VERSION "DNNBNNNYNNNNNNNNNNNNNNNNNNNNNNNNNNNNNNNNNN/4/%%%/4/'%**4NNN///"

NS_ :

BS_:

BU_: Vector__XXX xSolarWave xSolarSurveyor xSolarStorm xNova xMiata_SCP xMiata_AGS UI INV_CHG INV GATEWAY EMS DIAG CHG BMS BATTMON AGS

BO_ 2147612871 WarnLogSts2: 223 AGS
 SG_ WarnType : 8|3@1+ (1,0) [0|0] "" DIAG,UI
 SG_ WarnTime : 24|32@1+ (1,0) [0|4.29497E+09] "seconds" DIAG,UI
 SG_ WarnId : 11|13@1+ (1,0) [0|0] "" DIAG,UI
 SG_ StringId : 56|16@1+ (1,0) [0|65532] "" DIAG,UI
 SG_ RsvBits : 0|2@1+ (1,0) [0|0] "" DIAG,UI
 SG_ MsgCount : 2|6@1+ (1,0) [0|0] "" DIAG,UI

BO_ 2147612684 WarnLogSts: 223 AGS
 SG_ WarnType : 8|3@1+ (1,0) [0|0] "" DIAG,UI
 SG_ WarnTime : 24|32@1+ (1,0) [0|4.29497E+09] "seconds" DIAG,UI
 SG_ WarnId : 11|13@1+ (1,0) [0|0] "" DIAG,UI
 SG_ RsvBits : 0|2@1+ (1,0) [0|0] "" DIAG,UI
 SG_ MsgCount : 2|6@1+ (1,0) [0|0] "" DIAG,UI

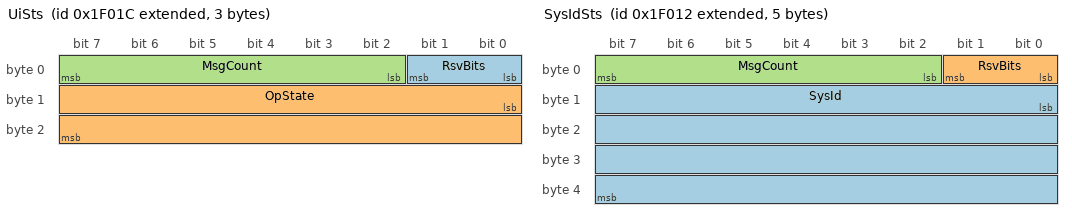
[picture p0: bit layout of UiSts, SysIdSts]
BO_ 2147610652 UiSts: 3 UI
 SG_ RsvBits : 0|2@1+ (1,0) [0|0] "" AGS,BATTMON,CHG,DIAG,INV,INV_CHG,UI
 SG_ OpState : 8|16@1+ (1,0) [0|65532] "" AGS,BATTMON,CHG,DIAG,INV,INV_CHG,UI
 SG_ MsgCount : 2|6@1+ (1,0) [0|0] "" AGS,BATTMON,CHG,DIAG,INV,INV_CHG,UI

BO_ 2147567104 UiCfgWarnTxt: 1785 DIAG
 SG_ WarnType : 16|3@1+ (1,0) [0|0] "" DIAG,UI
 SG_ WarnTxt : 32|256@1+ (1,0) [0|1785] "characters" DIAG,UI
 SG_ WarnId : 19|13@1+ (1,0) [0|0] "" DIAG,UI
 SG_ MsgCount : 2|6@1+ (1,0) [0|0] "" DIAG,UI
 SG_ ConcurAccCtr : 8|8@1+ (1,0) [0|252] "" DIAG,UI
 SG_ CfgType : 0|2@1+ (1,0) [0|0] "" DIAG,UI

BO_ 2147570944 UiCfgWarnBehaviour: 223 DIAG
 SG_ WarnId : 19|13@1+ (1,0) [0|0] "" DIAG,UI
 SG_ WarnBehaviour : 16|3@1+ (1,0) [0|0] "" DIAG,UI
 SG_ MsgCount : 2|6@1+ (1,0) [0|0] "" DIAG,UI
 SG_ ConcurAccCtr : 8|8@1+ (1,0) [0|252] "" DIAG,UI
 SG_ CfgType : 0|2@1+ (1,0) [0|0] "" DIAG,UI

BO_ 2147566080 UiCfgSplashImg: 1785 DIAG
 SG_ Rows : 24|8@1+ (1,0) [0|252] "" DIAG,UI
 SG_ MsgCount : 2|6@1+ (1,0) [0|0] "" DIAG,UI
 SG_ ImgDepth : 16|8@1+ (1,0) [0|252] "" DIAG,UI
 SG_ Image : 40|8@1+ (1,0) [0|1785] "8-Bit Bytes" DIAG,UI
 SG_ ConcurAccCtr : 8|8@1+ (1,0) [0|252] "" DIAG,UI
 SG_ Cols : 32|8@1+ (1,0) [0|252] "" DIAG,UI
 SG_ CfgType : 0|2@1+ (1,0) [0|0] "" DIAG,UI

BO_ 2147566336 UiCfgNodeLbl: 1785 DIAG
 SG_ SystemInstance : 40|4@1+ (1,0) [0|0] "" DIAG,UI
 SG_ RsvBit4 : 44|4@1+ (1,0) [0|0] "" DIAG,UI
 SG_ RsvBit1 : 32|1@1+ (1,0) [0|0] "" DIAG,UI
 SG_ NodeLbl : 48|128@1+ (1,0) [0|1785] "characters" DIAG,UI
 SG_ MsgCount : 2|6@1+ (1,0) [0|0] "" DIAG,UI
 SG_ DeviceInstanceUpper : 19|5@1+ (1,0) [0|0] "" DIAG,UI
 SG_ DeviceInstanceLower : 16|3@1+ (1,0) [0|0] "" DIAG,UI
 SG_ DeviceFunction : 24|8@1+ (1,0) [0|252] "" DIAG,UI
 SG_ DeviceClass : 33|7@1+ (1,0) [0|0] "" DIAG,UI
 SG_ ConcurAccCtr : 8|8@1+ (1,0) [0|252] "" DIAG,UI
 SG_ CfgType : 0|2@1+ (1,0) [0|0] "" DIAG,UI

BO_ 2147566848 UiCfgFaultTxt: 1785 DIAG
 SG_ MsgCount : 2|6@1+ (1,0) [0|0] "" DIAG,UI
 SG_ FaultType : 16|3@1+ (1,0) [0|0] "" DIAG,UI
 SG_ FaultTxt : 32|256@1+ (1,0) [0|1785] "characters" DIAG,UI
 SG_ FaultId : 19|13@1+ (1,0) [0|0] "" DIAG,UI
 SG_ ConcurAccCtr : 8|8@1+ (1,0) [0|252] "" DIAG,UI
 SG_ CfgType : 0|2@1+ (1,0) [0|0] "" DIAG,UI

BO_ 2147570688 UiCfgFaultBehaviour: 223 DIAG
 SG_ MsgCount : 2|6@1+ (1,0) [0|0] "" DIAG,UI
 SG_ FaultId : 19|13@1+ (1,0) [0|0] "" DIAG,UI
 SG_ FaultBehaviour : 16|3@1+ (1,0) [0|0] "" DIAG,UI
 SG_ ConcurAccCtr : 8|8@1+ (1,0) [0|252] "" DIAG,UI
 SG_ CfgType : 0|2@1+ (1,0) [0|0] "" DIAG,UI

BO_ 2147566592 UiCfgAssocLbl: 1785 DIAG
 SG_ RsvBits : 19|5@1+ (1,0) [0|0] "" DIAG,UI
 SG_ MsgCount : 2|6@1+ (1,0) [0|0] "" DIAG,UI
 SG_ ConcurAccCtr : 8|8@1+ (1,0) [0|252] "" DIAG,UI
 SG_ CfgType : 0|2@1+ (1,0) [0|0] "" DIAG,UI
 SG_ AssocType : 16|3@1+ (1,0) [0|0] "" DIAG,UI
 SG_ AssocLbl : 32|128@1+ (1,0) [0|1785] "characters" DIAG,UI
 SG_ AssocId : 24|8@1+ (1,0) [0|252] "" DIAG,UI

BO_ 2147565824 UiCfg: 17 DIAG
 SG_ WarnSndEnDis : 118|2@1+ (1,0) [0|0] "" DIAG,UI
 SG_ Vol : 104|8@1+ (1,0) [0|252] "%" DIAG,UI
 SG_ TimeFmt : 128|8@1+ (1,0) [0|252] "" DIAG,UI
 SG_ SplashScrnTo : 80|8@1+ (1,0) [0|252] "seconds" DIAG,UI
 SG_ SplashScrnStyl : 72|8@1+ (1,0) [0|252] "" DIAG,UI
 SG_ SplashOnWakeEnDis : 96|2@1+ (1,0) [0|0] "" DIAG,UI
 SG_ SndEnDis : 112|2@1+ (1,0) [0|0] "" DIAG,UI
 SG_ ScrnSaveTo : 64|8@1+ (1,0) [0|252] "minutes" DIAG,UI
 SG_ RsvBits : 98|6@1+ (1,0) [0|0] "" DIAG,UI
 SG_ MsgCount : 2|6@1+ (1,0) [0|0] "" DIAG,UI
 SG_ MeasUnit : 120|8@1+ (1,0) [0|252] "" DIAG,UI
 SG_ FaultSndEnDis : 116|2@1+ (1,0) [0|0] "" DIAG,UI
 SG_ DispSeqTo : 56|8@1+ (1,0) [0|252] "seconds" DIAG,UI
 SG_ DispContrast : 24|8@1+ (1,0) [0|252] "%" DIAG,UI
 SG_ DispBright : 16|8@1+ (1,0) [0|252] "%" DIAG,UI
 SG_ ConcurAccCtr : 8|8@1+ (1,0) [0|252] "" DIAG,UI
 SG_ CfgType : 0|2@1+ (1,0) [0|0] "" DIAG,UI
 SG_ BtnSndEnDis : 114|2@1+ (1,0) [0|0] "" DIAG,UI
 SG_ BtnRptRate : 40|8@1+ (1,0) [0|252] "Hz" DIAG,UI
 SG_ BtnHoldTo : 32|8@1+ (1,0) [0|252] "seconds" DIAG,UI
 SG_ BkltTo : 88|8@1+ (1,0) [0|252] "minutes" DIAG,UI
 SG_ AccMode : 48|8@1+ (1,0) [0|252] "" DIAG,UI

BO_ 2147610642 SysIdSts: 5 AGS
 SG_ SysId : 8|32@1+ (1,0) [0|4.29497E+09] "" DIAG,UI,xSolarSurveyor
 SG_ RsvBits : 0|2@1+ (1,0) [0|0] "" DIAG,UI,xSolarSurveyor
 SG_ MsgCount : 2|6@1+ (1,0) [0|0] "" DIAG,UI,xSolarSurveyor

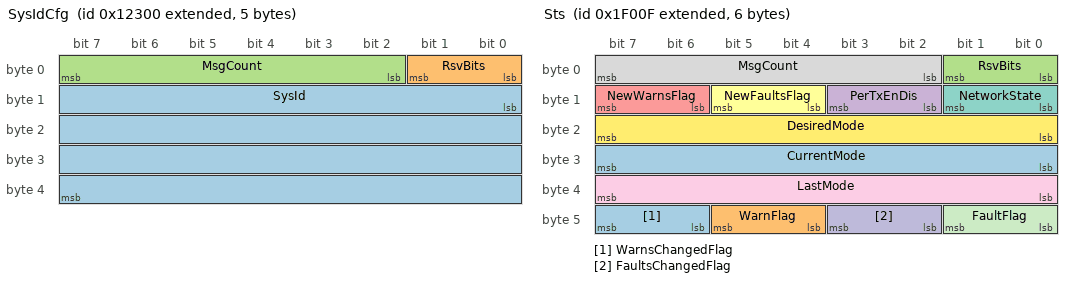
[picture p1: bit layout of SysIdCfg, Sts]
BO_ 2147558144 SysIdCfg: 5 AGS
 SG_ SysId : 8|32@1+ (1,0) [0|4.29497E+09] "" AGS,BATTMON,BMS,CHG,DIAG,EMS,GATEWAY,INV,INV_CHG,UI,xMiata_AGS,xSolarSurveyor,xSolarWave
 SG_ RsvBits : 0|2@1+ (1,0) [0|0] "" AGS,BATTMON,BMS,CHG,DIAG,EMS,GATEWAY,INV,INV_CHG,UI,xMiata_AGS,xSolarSurveyor,xSolarWave
 SG_ MsgCount : 2|6@1+ (1,0) [0|0] "" AGS,BATTMON,BMS,CHG,DIAG,EMS,GATEWAY,INV,INV_CHG,UI,xMiata_AGS,xSolarSurveyor,xSolarWave

BO_ 2147612686 SwVerSts: 223 AGS
 SG_ SwVer : 24|32@1+ (1,0) [0|4.29497E+09] "" DIAG,UI,xSolarWave
 SG_ SwModId : 16|8@1+ (1,0) [0|252] "" DIAG,UI,xSolarWave
 SG_ SwBldNum : 56|16@1+ (1,0) [0|65532] "" DIAG,UI,xSolarWave
 SG_ RsvBits2 : 12|4@1+ (1,0) [0|0] "" DIAG,UI,xSolarWave
 SG_ RsvBits1 : 0|2@1+ (1,0) [0|0] "" DIAG,UI,xSolarWave
 SG_ ProcessorInst : 8|4@1+ (1,0) [0|0] "" DIAG,UI,xSolarWave
 SG_ MsgCount : 2|6@1+ (1,0) [0|0] "" DIAG,UI,xSolarWave

BO_ 2147610639 Sts: 6 AGS
 SG_ WarnsChangedFlag : 46|2@1+ (1,0) [0|0] "" AGS,BATTMON,BMS,CHG,DIAG,EMS,GATEWAY,INV,INV_CHG,UI
 SG_ WarnFlag : 44|2@1+ (1,0) [0|0] "" AGS,BATTMON,BMS,CHG,DIAG,EMS,GATEWAY,INV,INV_CHG,UI
 SG_ RsvBits : 0|2@1+ (1,0) [0|0] "" AGS,BATTMON,BMS,CHG,DIAG,EMS,GATEWAY,INV,INV_CHG,UI
 SG_ PerTxEnDis : 10|2@1+ (1,0) [0|0] "" AGS,BATTMON,BMS,CHG,DIAG,EMS,GATEWAY,INV,INV_CHG,UI
 SG_ NewWarnsFlag : 14|2@1+ (1,0) [0|0] "" AGS,BATTMON,BMS,CHG,DIAG,EMS,GATEWAY,INV,INV_CHG,UI
 SG_ NewFaultsFlag : 12|2@1+ (1,0) [0|0] "" AGS,BATTMON,BMS,CHG,DIAG,EMS,GATEWAY,INV,INV_CHG,UI
 SG_ NetworkState : 8|2@1+ (1,0) [0|0] "" AGS,BATTMON,BMS,CHG,DIAG,EMS,GATEWAY,INV,INV_CHG,UI
 SG_ MsgCount : 2|6@1+ (1,0) [0|0] "" AGS,BATTMON,BMS,CHG,DIAG,EMS,GATEWAY,INV,INV_CHG,UI
 SG_ LastMode : 32|8@1+ (1,0) [0|252] "" AGS,BATTMON,BMS,CHG,DIAG,EMS,GATEWAY,INV,INV_CHG,UI
 SG_ FaultsChangedFlag : 42|2@1+ (1,0) [0|0] "" AGS,BATTMON,BMS,CHG,DIAG,EMS,GATEWAY,INV,INV_CHG,UI
 SG_ FaultFlag : 40|2@1+ (1,0) [0|0] "" AGS,BATTMON,BMS,CHG,DIAG,EMS,GATEWAY,INV,INV_CHG,UI
 SG_ DesiredMode : 16|8@1+ (1,0) [0|252] "" AGS,BATTMON,BMS,CHG,DIAG,EMS,GATEWAY,INV,INV_CHG,UI
 SG_ CurrentMode : 24|8@1+ (1,0) [0|252] "" AGS,BATTMON,BMS,CHG,DIAG,EMS,GATEWAY,INV,INV_CHG,UI

BO_ 2147605760 StringCfg: 223 AGS
 SG_ StringId : 16|16@1+ (1,0) [0|65532] "" AGS,BATTMON,CHG,DIAG,EMS,GATEWAY,INV,INV_CHG,UI,xSolarSurveyor,xSolarWave
 SG_ MsgCount : 2|6@1+ (1,0) [0|0] "" AGS,BATTMON,CHG,DIAG,EMS,GATEWAY,INV,INV_CHG,UI,xSolarSurveyor,xSolarWave
 SG_ ConcurAccCtr : 8|8@1+ (1,0) [0|252] "" AGS,BATTMON,CHG,DIAG,EMS,GATEWAY,INV,INV_CHG,UI,xSolarSurveyor,xSolarWave
 SG_ CharType : 32|8@1- (1,0) [-128|124] "" AGS,BATTMON,CHG,DIAG,EMS,GATEWAY,INV,INV_CHG,UI,xSolarSurveyor,xSolarWave
 SG_ CfgType : 0|2@1+ (1,0) [0|0] "" AGS,BATTMON,CHG,DIAG,EMS,GATEWAY,INV,INV_CHG,UI,xSolarSurveyor,xSolarWave
 SG_ Byte : 40|8@1+ (1,0) [0|1785] "8-Bit Bytes" AGS,BATTMON,CHG,DIAG,EMS,GATEWAY,INV,INV_CHG,UI,xSolarSurveyor,xSolarWave

BO_ 2147612873 StateEvtLogSts2: 223 AGS
 SG_ StringId : 72|16@1+ (1,0) [0|65532] "" DIAG,UI
 SG_ StateId : 24|16@1+ (1,0) [0|65532] "" DIAG,UI
 SG_ RsvBits : 0|2@1+ (1,0) [0|0] "" DIAG,UI
 SG_ MsgCount : 2|6@1+ (1,0) [0|0] "" DIAG,UI
 SG_ EvtTime : 40|32@1+ (1,0) [0|4.29497E+09] "seconds" DIAG,UI
 SG_ EvtId : 8|16@1+ (1,0) [0|65532] "" DIAG,UI

BO_ 2147612687 StateEvtLogSts: 223 AGS
 SG_ StateId : 24|16@1+ (1,0) [0|65532] "" DIAG,UI
 SG_ RsvBits : 0|2@1+ (1,0) [0|0] "" DIAG,UI
 SG_ MsgCount : 2|6@1+ (1,0) [0|0] "" DIAG,UI
 SG_ EvtTime : 40|32@1+ (1,0) [0|4.29497E+09] "seconds" DIAG,UI
 SG_ EvtId : 8|16@1+ (1,0) [0|65532] "" DIAG,UI

BO_ 2147610822 SpsSts: 14 DIAG
 SG_ Voltage : 16|32@1- (0.001,0) [-2.14748E+06|2.14748E+06] "V" DIAG,UI
 SG_ RsvBits : 0|2@1+ (1,0) [0|0] "" DIAG,UI
 SG_ OutputId : 8|8@1+ (1,0) [0|252] "" DIAG,UI
 SG_ OpState : 80|16@1+ (1,0) [0|65532] "" DIAG,UI
 SG_ OnReason : 96|8@1+ (1,0) [0|252] "" DIAG,UI
 SG_ OffReason : 104|8@1+ (1,0) [0|252] "" DIAG,UI
 SG_ MsgCount : 2|6@1+ (1,0) [0|0] "" DIAG,UI
 SG_ Current : 48|32@1- (0.001,0) [-2.14748E+06|2.14748E+06] "Amps" DIAG,UI

BO_ 2147599616 SpsCtrlCmd: 2 DIAG
 SG_ OutputId : 0|8@1+ (1,0) [0|252] "" xSolarSurveyor,xSolarWave
 SG_ DesiredState : 8|8@1+ (1,0) [0|252] "" xSolarSurveyor,xSolarWave

BO_ 2147600128 SpsCfgTrig: 223 BMS
 SG_ TrigEnDis : 24|2@1+ (1,0) [0|0] "" BMS,DIAG,UI,xSolarSurveyor,xSolarWave
 SG_ RsvBits : 26|6@1+ (1,0) [0|0] "" BMS,DIAG,UI,xSolarSurveyor,xSolarWave
 SG_ OutputId : 16|8@1+ (1,0) [0|252] "" BMS,DIAG,UI,xSolarSurveyor,xSolarWave
 SG_ MsgCount : 2|6@1+ (1,0) [0|0] "" BMS,DIAG,UI,xSolarSurveyor,xSolarWave
 SG_ EvtId : 32|16@1+ (1,0) [0|65532] "" BMS,DIAG,UI,xSolarSurveyor,xSolarWave
 SG_ ConcurAccCtr : 8|8@1+ (1,0) [0|252] "" BMS,DIAG,UI,xSolarSurveyor,xSolarWave
 SG_ CfgType : 0|2@1+ (1,0) [0|0] "" BMS,DIAG,UI,xSolarSurveyor,xSolarWave

BO_ 2147574272 SpsCfgBattSoc: 22 BMS
 SG_ TimeIntStopMin : 72|16@1+ (0.01,0) [0|655.32] "seconds" BMS,CHG,DIAG,INV,INV_CHG,UI,xSolarSurveyor,xSolarWave
 SG_ TimeIntStopMax : 88|16@1+ (0.01,0) [0|655.32] "seconds" BMS,CHG,DIAG,INV,INV_CHG,UI,xSolarSurveyor,xSolarWave
 SG_ TimeIntStop : 56|16@1+ (0.01,0) [0|655.32] "seconds" BMS,CHG,DIAG,INV,INV_CHG,UI,xSolarSurveyor,xSolarWave
 SG_ TimeIntStartMin : 144|16@1+ (0.01,0) [0|655.32] "seconds" BMS,CHG,DIAG,INV,INV_CHG,UI,xSolarSurveyor,xSolarWave
 SG_ TimeIntStartMax : 160|16@1+ (0.01,0) [0|655.32] "seconds" BMS,CHG,DIAG,INV,INV_CHG,UI,xSolarSurveyor,xSolarWave
 SG_ TimeIntStart : 128|16@1+ (0.01,0) [0|655.32] "seconds" BMS,CHG,DIAG,INV,INV_CHG,UI,xSolarSurveyor,xSolarWave
 SG_ SocLvlStopMin : 40|8@1+ (1,0) [0|252] "%" BMS,CHG,DIAG,INV,INV_CHG,UI,xSolarSurveyor,xSolarWave
 SG_ SocLvlStopMax : 48|8@1+ (1,0) [0|252] "%" BMS,CHG,DIAG,INV,INV_CHG,UI,xSolarSurveyor,xSolarWave
 SG_ SocLvlStop : 32|8@1+ (1,0) [0|252] "%" BMS,CHG,DIAG,INV,INV_CHG,UI,xSolarSurveyor,xSolarWave
 SG_ SocLvlStartMin : 112|8@1+ (1,0) [0|252] "%" BMS,CHG,DIAG,INV,INV_CHG,UI,xSolarSurveyor,xSolarWave
 SG_ SocLvlStartMax : 120|8@1+ (1,0) [0|252] "%" BMS,CHG,DIAG,INV,INV_CHG,UI,xSolarSurveyor,xSolarWave
 SG_ SocLvlStart : 104|8@1+ (1,0) [0|252] "%" BMS,CHG,DIAG,INV,INV_CHG,UI,xSolarSurveyor,xSolarWave
 SG_ OutputId : 24|8@1+ (1,0) [0|252] "" BMS,CHG,DIAG,INV,INV_CHG,UI,xSolarSurveyor,xSolarWave
 SG_ MsgCount : 2|6@1+ (1,0) [0|0] "" BMS,CHG,DIAG,INV,INV_CHG,UI,xSolarSurveyor,xSolarWave
 SG_ DcSrcId : 16|8@1+ (1,0) [0|252] "" BMS,CHG,DIAG,INV,INV_CHG,UI,xSolarSurveyor,xSolarWave
 SG_ ConcurAccCtr : 8|8@1+ (1,0) [0|252] "" BMS,CHG,DIAG,INV,INV_CHG,UI,xSolarSurveyor,xSolarWave
 SG_ CfgType : 0|2@1+ (1,0) [0|0] "" BMS,CHG,DIAG,INV,INV_CHG,UI,xSolarSurveyor,xSolarWave

BO_ 2147599872 SpsCfg: 28 BMS
 SG_ VoltageMin : 64|32@1- (0.001,0) [-2.14748E+06|2.14748E+06] "V" BMS,DIAG,UI,xSolarSurveyor,xSolarWave
 SG_ VoltageMax : 96|32@1- (0.001,0) [-2.14748E+06|2.14748E+06] "V" BMS,DIAG,UI,xSolarSurveyor,xSolarWave
 SG_ Voltage : 32|32@1- (0.001,0) [-2.14748E+06|2.14748E+06] "V" BMS,DIAG,UI,xSolarSurveyor,xSolarWave
 SG_ RsvBits : 26|6@1+ (1,0) [0|0] "" BMS,DIAG,UI,xSolarSurveyor,xSolarWave
 SG_ OutputId : 16|8@1+ (1,0) [0|252] "" BMS,DIAG,UI,xSolarSurveyor,xSolarWave
 SG_ MsgCount : 2|6@1+ (1,0) [0|0] "" BMS,DIAG,UI,xSolarSurveyor,xSolarWave
 SG_ CurrentMin : 160|32@1- (0.001,0) [-2.14748E+06|2.14748E+06] "Amps" BMS,DIAG,UI,xSolarSurveyor,xSolarWave
 SG_ CurrentMax : 192|32@1- (0.001,0) [-2.14748E+06|2.14748E+06] "Amps" BMS,DIAG,UI,xSolarSurveyor,xSolarWave
 SG_ Current : 128|32@1- (0.001,0) [-2.14748E+06|2.14748E+06] "Amps" BMS,DIAG,UI,xSolarSurveyor,xSolarWave
 SG_ ConcurAccCtr : 8|8@1+ (1,0) [0|252] "" BMS,DIAG,UI,xSolarSurveyor,xSolarWave
 SG_ CfgType : 0|2@1+ (1,0) [0|0] "" BMS,DIAG,UI,xSolarSurveyor,xSolarWave
 SG_ ActiveLevel : 24|2@1+ (1,0) [0|0] "" BMS,DIAG,UI,xSolarSurveyor,xSolarWave

BO_ 2147563520 SimpleCalibCfg: 13 BATTMON
 SG_ Value : 72|32@1- (1,0) [-2.14748E+09|2.14748E+09] "" BATTMON,DIAG,EMS,xNova,xSolarSurveyor,xSolarWave
 SG_ StsPgn : 8|24@1+ (1,0) [0|0] "" BATTMON,DIAG,EMS,xNova,xSolarSurveyor,xSolarWave
 SG_ Scale : 40|16@1+ (1,0) [0|65532] "" BATTMON,DIAG,EMS,xNova,xSolarSurveyor,xSolarWave
 SG_ RsvBits : 0|2@1+ (1,0) [0|0] "" BATTMON,DIAG,EMS,xNova,xSolarSurveyor,xSolarWave
 SG_ Offset : 56|16@1- (1,0) [-32768|32764] "" BATTMON,DIAG,EMS,xNova,xSolarSurveyor,xSolarWave
 SG_ MsgCount : 2|6@1+ (1,0) [0|0] "" BATTMON,DIAG,EMS,xNova,xSolarSurveyor,xSolarWave
 SG_ DataPtId : 32|8@1+ (1,0) [0|252] "" BATTMON,DIAG,EMS,xNova,xSolarSurveyor,xSolarWave

BO_ 2147562240 RxToCfg: 223 AGS
 SG_ Timeout : 40|16@1+ (0.01,0) [0|655.32] "seconds" AGS,BATTMON,BMS,CHG,DIAG,EMS,GATEWAY,INV,INV_CHG,UI,xMiata_AGS,xNova,xSolarSurveyor,xSolarWave
 SG_ ParmGrpNum : 16|24@1+ (1,0) [0|0] "" AGS,BATTMON,BMS,CHG,DIAG,EMS,GATEWAY,INV,INV_CHG,UI,xMiata_AGS,xNova,xSolarSurveyor,xSolarWave
 SG_ MsgCount : 2|6@1+ (1,0) [0|0] "" AGS,BATTMON,BMS,CHG,DIAG,EMS,GATEWAY,INV,INV_CHG,UI,xMiata_AGS,xNova,xSolarSurveyor,xSolarWave
 SG_ ConcurAccCtr : 8|8@1+ (1,0) [0|252] "" AGS,BATTMON,BMS,CHG,DIAG,EMS,GATEWAY,INV,INV_CHG,UI,xMiata_AGS,xNova,xSolarSurveyor,xSolarWave
 SG_ CfgType : 0|2@1+ (1,0) [0|0] "" AGS,BATTMON,BMS,CHG,DIAG,EMS,GATEWAY,INV,INV_CHG,UI,xMiata_AGS,xNova,xSolarSurveyor,xSolarWave

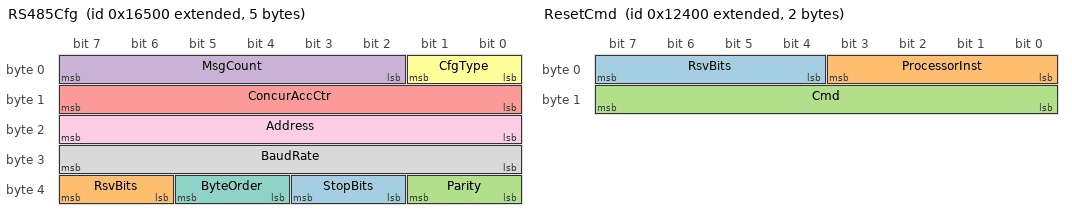
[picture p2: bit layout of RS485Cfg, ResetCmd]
BO_ 2147575040 RS485Cfg: 5 BATTMON
 SG_ StopBits : 34|2@1+ (1,0) [0|0] "" BATTMON,DIAG,UI
 SG_ RsvBits : 38|2@1+ (1,0) [0|0] "" BATTMON,DIAG,UI
 SG_ Parity : 32|2@1+ (1,0) [0|0] "" BATTMON,DIAG,UI
 SG_ MsgCount : 2|6@1+ (1,0) [0|0] "" BATTMON,DIAG,UI
 SG_ ConcurAccCtr : 8|8@1+ (1,0) [0|252] "" BATTMON,DIAG,UI
 SG_ CfgType : 0|2@1+ (1,0) [0|0] "" BATTMON,DIAG,UI
 SG_ ByteOrder : 36|2@1+ (1,0) [0|0] "" BATTMON,DIAG,UI
 SG_ BaudRate : 24|8@1+ (1,0) [0|252] "" BATTMON,DIAG,UI
 SG_ Address : 16|8@1+ (1,0) [0|252] "" BATTMON,DIAG,UI

BO_ 2147606272 RmtProcCallCmd: 223 DIAG
 SG_ ProcedureId : 0|32@1+ (1,0) [0|4.29497E+09] "" INV,INV_CHG,xNova,xSolarWave
 SG_ ProcedureArg : 32|32@1+ (1,0) [0|4.29497E+09] "" INV,INV_CHG,xNova,xSolarWave

BO_ 2147558400 ResetCmd: 2 DIAG
 SG_ RsvBits : 4|4@1+ (1,0) [0|0] "" AGS,BATTMON,BMS,CHG,EMS,GATEWAY,INV,INV_CHG,UI,xMiata_AGS,xNova,xSolarSurveyor,xSolarWave
 SG_ ProcessorInst : 0|4@1+ (1,0) [0|0] "" AGS,BATTMON,BMS,CHG,EMS,GATEWAY,INV,INV_CHG,UI,xMiata_AGS,xNova,xSolarSurveyor,xSolarWave
 SG_ Cmd : 8|8@1+ (1,0) [0|252] "" AGS,BATTMON,BMS,CHG,EMS,GATEWAY,INV,INV_CHG,UI,xMiata_AGS,xNova,xSolarSurveyor,xSolarWave

BO_ 2147610644 ProdInfoSts: 43 AGS
 SG_ RsvBits : 0|2@1+ (1,0) [0|0] "" DIAG,GATEWAY,UI,xSolarWave
 SG_ PwrLvl : 232|32@1+ (1,0) [0|4.29497E+09] "W" DIAG,GATEWAY,UI,xSolarWave
 SG_ NomDcLvl : 264|32@1- (0.001,0) [-2.14748E+06|2.14748E+06] "V" DIAG,GATEWAY,UI,xSolarWave
 SG_ NomAcOutFreq : 328|16@1+ (0.01,0) [0|655.32] "Hz" DIAG,GATEWAY,UI,xSolarWave
 SG_ NomAcLvl : 296|32@1+ (0.001,0) [0|4.29497E+06] "V" DIAG,GATEWAY,UI,xSolarWave
 SG_ MsgCount : 2|6@1+ (1,0) [0|0] "" DIAG,GATEWAY,UI,xSolarWave
 SG_ ModelName : 8|128@1+ (1,0) [0|1785] "characters" DIAG,GATEWAY,UI,xSolarWave
 SG_ Fga : 136|96@1+ (1,0) [0|1785] "characters" DIAG,GATEWAY,UI,xSolarWave

BO_ 2147610826 PidSts: 223 xSolarSurveyor
 SG_ RsvBits : 0|2@1+ (1,0) [0|0] "" DIAG
 SG_ Reference : 16|32@1- (1,0) [-2.14748E+09|2.14748E+09] "" DIAG
 SG_ Readback : 48|32@1- (1,0) [-2.14748E+09|2.14748E+09] "" DIAG
 SG_ PropTerm : 176|32@1- (1,0) [-2.14748E+09|2.14748E+09] "" DIAG
 SG_ Output : 272|32@1- (1,0) [-2.14748E+09|2.14748E+09] "" DIAG
 SG_ MsgCount : 2|6@1+ (1,0) [0|0] "" DIAG
 SG_ LoopId : 8|8@1+ (1,0) [0|252] "" DIAG
 SG_ IntTerm : 208|32@1- (1,0) [-2.14748E+09|2.14748E+09] "" DIAG
 SG_ IntErrterm : 112|32@1- (1,0) [-2.14748E+09|2.14748E+09] "" DIAG
 SG_ ExtraField2 : 320|16@1- (1,0) [-32768|32764] "" DIAG
 SG_ ExtraField1 : 304|16@1- (1,0) [-32768|32764] "" DIAG
 SG_ ErrTerm : 80|32@1- (1,0) [-2.14748E+09|2.14748E+09] "" DIAG
 SG_ DerTerm : 240|32@1- (1,0) [-2.14748E+09|2.14748E+09] "" DIAG
 SG_ DerErrTerm : 144|32@1- (1,0) [-2.14748E+09|2.14748E+09] "" DIAG

BO_ 2147600640 PidCfg: 32 xSolarSurveyor
 SG_ ResBits1 : 26|6@1+ (1,0) [0|0] "" DIAG
 SG_ OutputMin : 160|32@1- (1,0) [-2.14748E+09|2.14748E+09] "" DIAG
 SG_ OutputMax : 192|32@1- (1,0) [-2.14748E+09|2.14748E+09] "" DIAG
 SG_ MsgCount : 2|6@1+ (1,0) [0|0] "" DIAG
 SG_ LoopId : 16|8@1+ (1,0) [0|252] "" DIAG
 SG_ LoopFreq : 32|32@1+ (1,0) [0|4.29497E+09] "" DIAG
 SG_ LoopEnDis : 24|2@1+ (1,0) [0|0] "" DIAG
 SG_ Kp : 64|32@1- (1,0) [-2.14748E+09|2.14748E+09] "" DIAG
 SG_ Ki : 96|32@1- (1,0) [-2.14748E+09|2.14748E+09] "" DIAG
 SG_ Kd : 128|32@1- (1,0) [-2.14748E+09|2.14748E+09] "" DIAG
 SG_ ExtraField2 : 240|16@1- (1,0) [-32768|32764] "" DIAG
 SG_ ExtraField1 : 224|16@1- (1,0) [-32768|32764] "" DIAG
 SG_ ConcurAccCtr : 8|8@1+ (1,0) [0|252] "" DIAG
 SG_ CfgType : 0|2@1+ (1,0) [0|0] "" DIAG

BO_ 2147610112 PgnList: 1785 AGS
 SG_ TXPgns_0 m0 : 8|24@1+ (1,0) [0|0] "" DIAG,UI
 SG_ TXedPgnGroupFunctionCode M : 0|8@1+ (1,0) [0|252] "" DIAG,UI
 SG_ RXPgns_1 m1 : 8|24@1+ (1,0) [0|0] "" DIAG,UI

BO_ 2147560704 PerXmitCfg: 223 AGS
 SG_ XmitPeriod : 48|16@1+ (0.01,0) [0|655.32] "seconds" AGS,BATTMON,BMS,CHG,DIAG,EMS,GATEWAY,INV,INV_CHG,UI,xMiata_AGS,xNova,xSolarSurveyor,xSolarWave
 SG_ XmitAddr : 40|8@1+ (1,0) [0|252] "" AGS,BATTMON,BMS,CHG,DIAG,EMS,GATEWAY,INV,INV_CHG,UI,xMiata_AGS,xNova,xSolarSurveyor,xSolarWave
 SG_ ParmGrpNum : 16|24@1+ (1,0) [0|0] "" AGS,BATTMON,BMS,CHG,DIAG,EMS,GATEWAY,INV,INV_CHG,UI,xMiata_AGS,xNova,xSolarSurveyor,xSolarWave
 SG_ MsgCount : 2|6@1+ (1,0) [0|0] "" AGS,BATTMON,BMS,CHG,DIAG,EMS,GATEWAY,INV,INV_CHG,UI,xMiata_AGS,xNova,xSolarSurveyor,xSolarWave
 SG_ ConcurAccCtr : 8|8@1+ (1,0) [0|252] "" AGS,BATTMON,BMS,CHG,DIAG,EMS,GATEWAY,INV,INV_CHG,UI,xMiata_AGS,xNova,xSolarSurveyor,xSolarWave
 SG_ CfgType : 0|2@1+ (1,0) [0|0] "" AGS,BATTMON,BMS,CHG,DIAG,EMS,GATEWAY,INV,INV_CHG,UI,xMiata_AGS,xNova,xSolarSurveyor,xSolarWave

BO_ 2147610634 OpsSts: 10 CHG
 SG_ Voltage : 16|32@1- (0.001,0) [-2.14748E+06|2.14748E+06] "V" CHG,DIAG,INV,INV_CHG
 SG_ RsvBits : 0|2@1+ (1,0) [0|0] "" CHG,DIAG,INV,INV_CHG
 SG_ OutputId : 8|8@1+ (1,0) [0|252] "" CHG,DIAG,INV,INV_CHG
 SG_ MsgCount : 2|6@1+ (1,0) [0|0] "" CHG,DIAG,INV,INV_CHG
 SG_ Current : 48|32@1- (0.001,0) [-2.14748E+06|2.14748E+06] "Amps" CHG,DIAG,INV,INV_CHG

BO_ 2147553024 OpsCfgUv: 223 CHG
 SG_ UvLvlMin : 88|32@1- (0.001,0) [-2.14748E+06|2.14748E+06] "V" CHG,DIAG,INV,INV_CHG
 SG_ UvLvlMax : 120|32@1- (0.001,0) [-2.14748E+06|2.14748E+06] "V" CHG,DIAG,INV,INV_CHG
 SG_ UvLvl : 56|32@1- (0.001,0) [-2.14748E+06|2.14748E+06] "V" CHG,DIAG,INV,INV_CHG
 SG_ UvIntvlMin : 168|16@1+ (0.01,0) [0|655.32] "seconds" CHG,DIAG,INV,INV_CHG
 SG_ UvIntvlMax : 184|16@1+ (0.01,0) [0|655.32] "seconds" CHG,DIAG,INV,INV_CHG
 SG_ UvIntvl : 152|16@1+ (0.01,0) [0|655.32] "seconds" CHG,DIAG,INV,INV_CHG
 SG_ RefEvtId : 40|16@1+ (1,0) [0|65532] "" CHG,DIAG,INV,INV_CHG
 SG_ OutputId : 16|8@1+ (1,0) [0|252] "" CHG,DIAG,INV,INV_CHG
 SG_ MsgCount : 2|6@1+ (1,0) [0|0] "" CHG,DIAG,INV,INV_CHG
 SG_ EvtId : 24|16@1+ (1,0) [0|65532] "" CHG,DIAG,INV,INV_CHG
 SG_ ConcurAccCtr : 8|8@1+ (1,0) [0|252] "" CHG,DIAG,INV,INV_CHG
 SG_ CfgType : 0|2@1+ (1,0) [0|0] "" CHG,DIAG,INV,INV_CHG

BO_ 2147553280 OpsCfgOv: 223 CHG
 SG_ RefEvtId : 40|16@1+ (1,0) [0|65532] "" CHG,DIAG,INV,INV_CHG
 SG_ OvLvlMin : 88|32@1- (0.001,0) [-2.14748E+06|2.14748E+06] "V" CHG,DIAG,INV,INV_CHG
 SG_ OvLvlMax : 120|32@1- (0.001,0) [-2.14748E+06|2.14748E+06] "V" CHG,DIAG,INV,INV_CHG
 SG_ OvLvl : 56|32@1- (0.001,0) [-2.14748E+06|2.14748E+06] "V" CHG,DIAG,INV,INV_CHG
 SG_ OvIntvlMin : 168|16@1+ (0.01,0) [0|655.32] "seconds" CHG,DIAG,INV,INV_CHG
 SG_ OvIntvlMax : 184|16@1+ (0.01,0) [0|655.32] "seconds" CHG,DIAG,INV,INV_CHG
 SG_ OvIntvl : 152|16@1+ (0.01,0) [0|655.32] "seconds" CHG,DIAG,INV,INV_CHG
 SG_ OutputId : 16|8@1+ (1,0) [0|252] "" CHG,DIAG,INV,INV_CHG
 SG_ MsgCount : 2|6@1+ (1,0) [0|0] "" CHG,DIAG,INV,INV_CHG
 SG_ EvtId : 24|16@1+ (1,0) [0|65532] "" CHG,DIAG,INV,INV_CHG
 SG_ ConcurAccCtr : 8|8@1+ (1,0) [0|252] "" CHG,DIAG,INV,INV_CHG
 SG_ CfgType : 0|2@1+ (1,0) [0|0] "" CHG,DIAG,INV,INV_CHG

BO_ 2147564032 NAMECfg: 10 AGS
 SG_ UniqueNumber : 16|21@1+ (1,0) [0|0] "" AGS,BATTMON,BMS,CHG,DIAG,EMS,GATEWAY,INV,INV_CHG,UI,xMiata_AGS,xNova,xSolarSurveyor,xSolarWave
 SG_ SystemInstance : 72|4@1+ (1,0) [0|0] "" AGS,BATTMON,BMS,CHG,DIAG,EMS,GATEWAY,INV,INV_CHG,UI,xMiata_AGS,xNova,xSolarSurveyor,xSolarWave
 SG_ SelfCfgAddr : 79|1@1+ (1,0) [0|0] "" AGS,BATTMON,BMS,CHG,DIAG,EMS,GATEWAY,INV,INV_CHG,UI,xMiata_AGS,xNova,xSolarSurveyor,xSolarWave
 SG_ RsvBit : 64|1@1+ (1,0) [0|0] "" AGS,BATTMON,BMS,CHG,DIAG,EMS,GATEWAY,INV,INV_CHG,UI,xMiata_AGS,xNova,xSolarSurveyor,xSolarWave
 SG_ MsgCount : 2|6@1+ (1,0) [0|0] "" AGS,BATTMON,BMS,CHG,DIAG,EMS,GATEWAY,INV,INV_CHG,UI,xMiata_AGS,xNova,xSolarSurveyor,xSolarWave
 SG_ ManufacturerCode : 37|11@1+ (1,0) [0|0] "" AGS,BATTMON,BMS,CHG,DIAG,EMS,GATEWAY,INV,INV_CHG,UI,xMiata_AGS,xNova,xSolarSurveyor,xSolarWave
 SG_ IndustryGroup : 76|3@1+ (1,0) [0|0] "" AGS,BATTMON,BMS,CHG,DIAG,EMS,GATEWAY,INV,INV_CHG,UI,xMiata_AGS,xNova,xSolarSurveyor,xSolarWave
 SG_ DeviceInstanceUpper : 51|5@1+ (1,0) [0|0] "" AGS,BATTMON,BMS,CHG,DIAG,EMS,GATEWAY,INV,INV_CHG,UI,xMiata_AGS,xNova,xSolarSurveyor,xSolarWave
 SG_ DeviceInstanceLower : 48|3@1+ (1,0) [0|0] "" AGS,BATTMON,BMS,CHG,DIAG,EMS,GATEWAY,INV,INV_CHG,UI,xMiata_AGS,xNova,xSolarSurveyor,xSolarWave
 SG_ DeviceFunction : 56|8@1+ (1,0) [0|252] "" AGS,BATTMON,BMS,CHG,DIAG,EMS,GATEWAY,INV,INV_CHG,UI,xMiata_AGS,xNova,xSolarSurveyor,xSolarWave
 SG_ DeviceClass : 65|7@1+ (1,0) [0|0] "" AGS,BATTMON,BMS,CHG,DIAG,EMS,GATEWAY,INV,INV_CHG,UI,xMiata_AGS,xNova,xSolarSurveyor,xSolarWave
 SG_ ConcurAccCtr : 8|8@1+ (1,0) [0|252] "" AGS,BATTMON,BMS,CHG,DIAG,EMS,GATEWAY,INV,INV_CHG,UI,xMiata_AGS,xNova,xSolarSurveyor,xSolarWave
 SG_ CfgType : 0|2@1+ (1,0) [0|0] "" AGS,BATTMON,BMS,CHG,DIAG,EMS,GATEWAY,INV,INV_CHG,UI,xMiata_AGS,xNova,xSolarSurveyor,xSolarWave

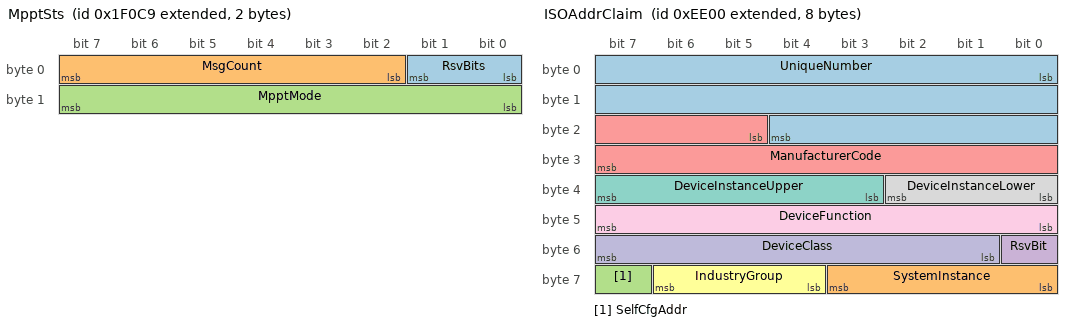
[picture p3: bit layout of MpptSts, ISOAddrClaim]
BO_ 2147610825 MpptSts: 2 CHG
 SG_ RsvBits : 0|2@1+ (1,0) [0|0] "" DIAG,INV_CHG,UI,xSolarWave
 SG_ MsgCount : 2|6@1+ (1,0) [0|0] "" DIAG,INV_CHG,UI,xSolarWave
 SG_ MpptMode : 8|8@1+ (1,0) [0|252] "" DIAG,INV_CHG,UI,xSolarWave

BO_ 2147543808 ISOTpXfer: 8 AGS
 SG_ SeqNumMultiPacketFrame : 0|8@1+ (1,0) [0|252] "" AGS,BATTMON,BMS,CHG,DIAG,EMS,GATEWAY,INV,INV_CHG,UI,xMiata_AGS,xNova,xSolarSurveyor,xSolarWave
 SG_ MultiPacketPacketizedData : 8|56@1+ (1,0) [0|0] "" AGS,BATTMON,BMS,CHG,DIAG,EMS,GATEWAY,INV,INV_CHG,UI,xMiata_AGS,xNova,xSolarSurveyor,xSolarWave

BO_ 2147544064 ISOTpConnMan: 8 AGS
 SG_ TotalNumFramesXmit_16 m16 : 24|8@1+ (1,0) [0|252] "" AGS,BATTMON,BMS,CHG,DIAG,EMS,GATEWAY,INV,INV_CHG,UI,xMiata_AGS,xNova,xSolarSurveyor,xSolarWave
 SG_ TotalNumFramesToBeSent_32 m32 : 24|8@1+ (1,0) [0|252] "" AGS,BATTMON,BMS,CHG,DIAG,EMS,GATEWAY,INV,INV_CHG,UI,xMiata_AGS,xNova,xSolarSurveyor,xSolarWave
 SG_ TotalNumFramesRXed_19 m19 : 24|8@1+ (1,0) [0|252] "" AGS,BATTMON,BMS,CHG,DIAG,EMS,GATEWAY,INV,INV_CHG,UI,xMiata_AGS,xNova,xSolarSurveyor,xSolarWave
 SG_ TotalMsgSz_16 m16 : 8|16@1+ (1,0) [0|65532] "" AGS,BATTMON,BMS,CHG,DIAG,EMS,GATEWAY,INV,INV_CHG,UI,xMiata_AGS,xNova,xSolarSurveyor,xSolarWave
 SG_ TotalMsgSz_32 m32 : 8|16@1+ (1,0) [0|65532] "" AGS,BATTMON,BMS,CHG,DIAG,EMS,GATEWAY,INV,INV_CHG,UI,xMiata_AGS,xNova,xSolarSurveyor,xSolarWave
 SG_ TotalMsgSz_19 m19 : 8|16@1+ (1,0) [0|65532] "" AGS,BATTMON,BMS,CHG,DIAG,EMS,GATEWAY,INV,INV_CHG,UI,xMiata_AGS,xNova,xSolarSurveyor,xSolarWave
 SG_ RTSGroupFunctionCode M : 0|8@1+ (1,0) [0|252] "" AGS,BATTMON,BMS,CHG,DIAG,EMS,GATEWAY,INV,INV_CHG,UI,xMiata_AGS,xNova,xSolarSurveyor,xSolarWave
 SG_ RsvBits_255 m255 : 8|32@1+ (1,0) [0|0] "" AGS,BATTMON,BMS,CHG,DIAG,EMS,GATEWAY,INV,INV_CHG,UI,xMiata_AGS,xNova,xSolarSurveyor,xSolarWave
 SG_ RsvBits_32 m32 : 32|8@1+ (1,0) [0|0] "" AGS,BATTMON,BMS,CHG,DIAG,EMS,GATEWAY,INV,INV_CHG,UI,xMiata_AGS,xNova,xSolarSurveyor,xSolarWave
 SG_ RsvBits_19 m19 : 32|8@1+ (1,0) [0|0] "" AGS,BATTMON,BMS,CHG,DIAG,EMS,GATEWAY,INV,INV_CHG,UI,xMiata_AGS,xNova,xSolarSurveyor,xSolarWave
 SG_ RsvBits_17 m17 : 24|16@1+ (1,0) [0|0] "" AGS,BATTMON,BMS,CHG,DIAG,EMS,GATEWAY,INV,INV_CHG,UI,xMiata_AGS,xNova,xSolarSurveyor,xSolarWave
 SG_ RsvBits_16 m16 : 32|8@1+ (1,0) [0|0] "" AGS,BATTMON,BMS,CHG,DIAG,EMS,GATEWAY,INV,INV_CHG,UI,xMiata_AGS,xNova,xSolarSurveyor,xSolarWave
 SG_ ParmGrpNum_16 m16 : 40|24@1+ (1,0) [0|0] "" AGS,BATTMON,BMS,CHG,DIAG,EMS,GATEWAY,INV,INV_CHG,UI,xMiata_AGS,xNova,xSolarSurveyor,xSolarWave
 SG_ ParmGrpNum_32 m32 : 40|24@1+ (1,0) [0|0] "" AGS,BATTMON,BMS,CHG,DIAG,EMS,GATEWAY,INV,INV_CHG,UI,xMiata_AGS,xNova,xSolarSurveyor,xSolarWave
 SG_ ParmGrpNum_17 m17 : 40|24@1+ (1,0) [0|0] "" AGS,BATTMON,BMS,CHG,DIAG,EMS,GATEWAY,INV,INV_CHG,UI,xMiata_AGS,xNova,xSolarSurveyor,xSolarWave
 SG_ ParmGrpNum_255 m255 : 40|24@1+ (1,0) [0|0] "" AGS,BATTMON,BMS,CHG,DIAG,EMS,GATEWAY,INV,INV_CHG,UI,xMiata_AGS,xNova,xSolarSurveyor,xSolarWave
 SG_ ParmGrpNum_19 m19 : 40|24@1+ (1,0) [0|0] "" AGS,BATTMON,BMS,CHG,DIAG,EMS,GATEWAY,INV,INV_CHG,UI,xMiata_AGS,xNova,xSolarSurveyor,xSolarWave
 SG_ NumNextFrameToBeSent_17 m17 : 16|8@1+ (1,0) [0|252] "" AGS,BATTMON,BMS,CHG,DIAG,EMS,GATEWAY,INV,INV_CHG,UI,xMiata_AGS,xNova,xSolarSurveyor,xSolarWave
 SG_ NumFramesThatCanBeSent_17 m17 : 8|8@1+ (1,0) [0|252] "" AGS,BATTMON,BMS,CHG,DIAG,EMS,GATEWAY,INV,INV_CHG,UI,xMiata_AGS,xNova,xSolarSurveyor,xSolarWave

BO_ 2147543552 ISOReq: 3 AGS
 SG_ ParmGrpNum : 0|24@1+ (1,0) [0|0] "" AGS,BATTMON,BMS,CHG,DIAG,EMS,GATEWAY,INV,INV_CHG,UI,xMiata_AGS,xNova,xSolarSurveyor,xSolarWave

BO_ 2147548888 ISOCmdAddr: 9 DIAG
 SG_ UniqueNumber : 0|21@1+ (1,0) [0|0] "" AGS,BATTMON,BMS,CHG,DIAG,EMS,GATEWAY,INV,INV_CHG,UI,xMiata_AGS,xNova,xSolarSurveyor,xSolarWave
 SG_ SystemInstance : 56|4@1+ (1,0) [0|0] "" AGS,BATTMON,BMS,CHG,DIAG,EMS,GATEWAY,INV,INV_CHG,UI,xMiata_AGS,xNova,xSolarSurveyor,xSolarWave
 SG_ SelfCfgAddr : 63|1@1+ (1,0) [0|0] "" AGS,BATTMON,BMS,CHG,DIAG,EMS,GATEWAY,INV,INV_CHG,UI,xMiata_AGS,xNova,xSolarSurveyor,xSolarWave
 SG_ RsvBit : 48|1@1+ (1,0) [0|0] "" AGS,BATTMON,BMS,CHG,DIAG,EMS,GATEWAY,INV,INV_CHG,UI,xMiata_AGS,xNova,xSolarSurveyor,xSolarWave
 SG_ PrefSrcAddr : 64|8@1+ (1,0) [0|252] "" AGS,BATTMON,BMS,CHG,DIAG,EMS,GATEWAY,INV,INV_CHG,UI,xMiata_AGS,xNova,xSolarSurveyor,xSolarWave
 SG_ ManufacturerCode : 21|11@1+ (1,0) [0|0] "" AGS,BATTMON,BMS,CHG,DIAG,EMS,GATEWAY,INV,INV_CHG,UI,xMiata_AGS,xNova,xSolarSurveyor,xSolarWave
 SG_ IndustryGroup : 60|3@1+ (1,0) [0|0] "" AGS,BATTMON,BMS,CHG,DIAG,EMS,GATEWAY,INV,INV_CHG,UI,xMiata_AGS,xNova,xSolarSurveyor,xSolarWave
 SG_ DeviceInstanceUpper : 35|5@1+ (1,0) [0|0] "" AGS,BATTMON,BMS,CHG,DIAG,EMS,GATEWAY,INV,INV_CHG,UI,xMiata_AGS,xNova,xSolarSurveyor,xSolarWave
 SG_ DeviceInstanceLower : 32|3@1+ (1,0) [0|0] "" AGS,BATTMON,BMS,CHG,DIAG,EMS,GATEWAY,INV,INV_CHG,UI,xMiata_AGS,xNova,xSolarSurveyor,xSolarWave
 SG_ DeviceFunction : 40|8@1+ (1,0) [0|252] "" AGS,BATTMON,BMS,CHG,DIAG,EMS,GATEWAY,INV,INV_CHG,UI,xMiata_AGS,xNova,xSolarSurveyor,xSolarWave
 SG_ DeviceClass : 49|7@1+ (1,0) [0|0] "" AGS,BATTMON,BMS,CHG,DIAG,EMS,GATEWAY,INV,INV_CHG,UI,xMiata_AGS,xNova,xSolarSurveyor,xSolarWave

BO_ 2147544576 ISOAddrClaim: 8 AGS
 SG_ UniqueNumber : 0|21@1+ (1,0) [0|0] "" AGS,BATTMON,BMS,CHG,DIAG,EMS,GATEWAY,INV,INV_CHG,UI,xMiata_AGS,xNova,xSolarSurveyor,xSolarWave
 SG_ SystemInstance : 56|4@1+ (1,0) [0|0] "" AGS,BATTMON,BMS,CHG,DIAG,EMS,GATEWAY,INV,INV_CHG,UI,xMiata_AGS,xNova,xSolarSurveyor,xSolarWave
 SG_ SelfCfgAddr : 63|1@1+ (1,0) [0|0] "" AGS,BATTMON,BMS,CHG,DIAG,EMS,GATEWAY,INV,INV_CHG,UI,xMiata_AGS,xNova,xSolarSurveyor,xSolarWave
 SG_ RsvBit : 48|1@1+ (1,0) [0|0] "" AGS,BATTMON,BMS,CHG,DIAG,EMS,GATEWAY,INV,INV_CHG,UI,xMiata_AGS,xNova,xSolarSurveyor,xSolarWave
 SG_ ManufacturerCode : 21|11@1+ (1,0) [0|0] "" AGS,BATTMON,BMS,CHG,DIAG,EMS,GATEWAY,INV,INV_CHG,UI,xMiata_AGS,xNova,xSolarSurveyor,xSolarWave
 SG_ IndustryGroup : 60|3@1+ (1,0) [0|0] "" AGS,BATTMON,BMS,CHG,DIAG,EMS,GATEWAY,INV,INV_CHG,UI,xMiata_AGS,xNova,xSolarSurveyor,xSolarWave
 SG_ DeviceInstanceUpper : 35|5@1+ (1,0) [0|0] "" AGS,BATTMON,BMS,CHG,DIAG,EMS,GATEWAY,INV,INV_CHG,UI,xMiata_AGS,xNova,xSolarSurveyor,xSolarWave
 SG_ DeviceInstanceLower : 32|3@1+ (1,0) [0|0] "" AGS,BATTMON,BMS,CHG,DIAG,EMS,GATEWAY,INV,INV_CHG,UI,xMiata_AGS,xNova,xSolarSurveyor,xSolarWave
 SG_ DeviceFunction : 40|8@1+ (1,0) [0|252] "" AGS,BATTMON,BMS,CHG,DIAG,EMS,GATEWAY,INV,INV_CHG,UI,xMiata_AGS,xNova,xSolarSurveyor,xSolarWave
 SG_ DeviceClass : 49|7@1+ (1,0) [0|0] "" AGS,BATTMON,BMS,CHG,DIAG,EMS,GATEWAY,INV,INV_CHG,UI,xMiata_AGS,xNova,xSolarSurveyor,xSolarWave

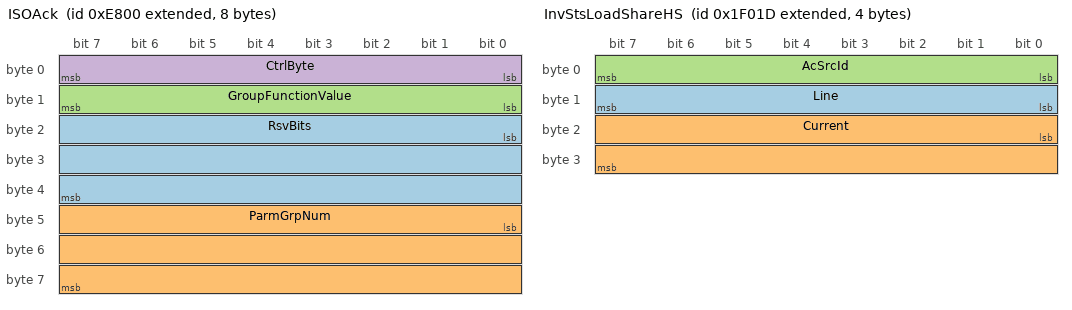
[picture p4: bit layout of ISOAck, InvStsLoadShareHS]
BO_ 2147543040 ISOAck: 8 AGS
 SG_ RsvBits : 16|24@1+ (1,0) [0|0] "" AGS,BATTMON,BMS,CHG,DIAG,EMS,GATEWAY,INV,INV_CHG,UI
 SG_ ParmGrpNum : 40|24@1+ (1,0) [0|0] "" AGS,BATTMON,BMS,CHG,DIAG,EMS,GATEWAY,INV,INV_CHG,UI
 SG_ GroupFunctionValue : 8|8@1+ (1,0) [0|252] "" AGS,BATTMON,BMS,CHG,DIAG,EMS,GATEWAY,INV,INV_CHG,UI
 SG_ CtrlByte : 0|8@1+ (1,0) [0|252] "" AGS,BATTMON,BMS,CHG,DIAG,EMS,GATEWAY,INV,INV_CHG,UI

BO_ 2147610653 InvStsLoadShareHS: 4 INV
 SG_ Line : 8|8@1+ (1,0) [0|252] "" DIAG,INV,INV_CHG,xSolarWave
 SG_ Current : 16|16@1- (0.01,0) [-327.68|327.68] "A" DIAG,INV,INV_CHG,xSolarWave
 SG_ AcSrcId : 0|8@1+ (1,0) [0|252] "" DIAG,INV,INV_CHG,xSolarWave

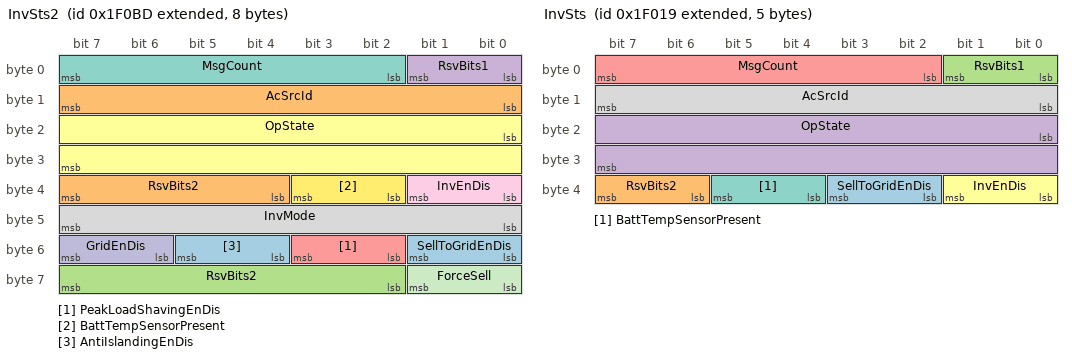
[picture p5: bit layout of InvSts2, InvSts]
BO_ 2147610813 InvSts2: 8 INV
 SG_ SellToGridEnDis : 48|2@1+ (1,0) [0|0] "" AGS,BATTMON,BMS,CHG,DIAG,GATEWAY,INV,INV_CHG,UI,xSolarWave
 SG_ RsvBits2 : 36|4@1+ (1,0) [0|0] "" AGS,BATTMON,BMS,CHG,DIAG,GATEWAY,INV,INV_CHG,UI,xSolarWave
 SG_ RsvBits2 : 58|6@1+ (1,0) [0|0] "" AGS,BATTMON,BMS,CHG,DIAG,GATEWAY,INV,INV_CHG,UI,xSolarWave
 SG_ RsvBits1 : 0|2@1+ (1,0) [0|0] "" AGS,BATTMON,BMS,CHG,DIAG,GATEWAY,INV,INV_CHG,UI,xSolarWave
 SG_ PeakLoadShavingEnDis : 50|2@1+ (1,0) [0|0] "" AGS,BATTMON,BMS,CHG,DIAG,GATEWAY,INV,INV_CHG,UI,xSolarWave
 SG_ OpState : 16|16@1+ (1,0) [0|65532] "" AGS,BATTMON,BMS,CHG,DIAG,GATEWAY,INV,INV_CHG,UI,xSolarWave
 SG_ MsgCount : 2|6@1+ (1,0) [0|0] "" AGS,BATTMON,BMS,CHG,DIAG,GATEWAY,INV,INV_CHG,UI,xSolarWave
 SG_ InvMode : 40|8@1+ (1,0) [0|252] "" AGS,BATTMON,BMS,CHG,DIAG,GATEWAY,INV,INV_CHG,UI,xSolarWave
 SG_ InvEnDis : 32|2@1+ (1,0) [0|0] "" AGS,BATTMON,BMS,CHG,DIAG,GATEWAY,INV,INV_CHG,UI,xSolarWave
 SG_ GridEnDis : 54|2@1+ (1,0) [0|0] "" AGS,BATTMON,BMS,CHG,DIAG,GATEWAY,INV,INV_CHG,UI,xSolarWave
 SG_ ForceSell : 56|2@1+ (1,0) [0|0] "" AGS,BATTMON,BMS,CHG,DIAG,GATEWAY,INV,INV_CHG,UI,xSolarWave
 SG_ BattTempSensorPresent : 34|2@1+ (1,0) [0|0] "" AGS,BATTMON,BMS,CHG,DIAG,GATEWAY,INV,INV_CHG,UI,xSolarWave
 SG_ AntiIslandingEnDis : 52|2@1+ (1,0) [0|0] "" AGS,BATTMON,BMS,CHG,DIAG,GATEWAY,INV,INV_CHG,UI,xSolarWave
 SG_ AcSrcId : 8|8@1+ (1,0) [0|252] "" AGS,BATTMON,BMS,CHG,DIAG,GATEWAY,INV,INV_CHG,UI,xSolarWave

BO_ 2147610649 InvSts: 5 INV
 SG_ SellToGridEnDis : 34|2@1+ (1,0) [0|0] "" AGS,BATTMON,CHG,DIAG,GATEWAY,INV,INV_CHG,UI
 SG_ RsvBits2 : 38|2@1+ (1,0) [0|0] "" AGS,BATTMON,CHG,DIAG,GATEWAY,INV,INV_CHG,UI
 SG_ RsvBits1 : 0|2@1+ (1,0) [0|0] "" AGS,BATTMON,CHG,DIAG,GATEWAY,INV,INV_CHG,UI
 SG_ OpState : 16|16@1+ (1,0) [0|65532] "" AGS,BATTMON,CHG,DIAG,GATEWAY,INV,INV_CHG,UI
 SG_ MsgCount : 2|6@1+ (1,0) [0|0] "" AGS,BATTMON,CHG,DIAG,GATEWAY,INV,INV_CHG,UI
 SG_ InvEnDis : 32|2@1+ (1,0) [0|0] "" AGS,BATTMON,CHG,DIAG,GATEWAY,INV,INV_CHG,UI
 SG_ BattTempSensorPresent : 36|2@1+ (1,0) [0|0] "" AGS,BATTMON,CHG,DIAG,GATEWAY,INV,INV_CHG,UI
 SG_ AcSrcId : 8|8@1+ (1,0) [0|252] "" AGS,BATTMON,CHG,DIAG,GATEWAY,INV,INV_CHG,UI

BO_ 2147610655 InvStatsIntTemp: 223 INV
 SG_ TempSensId : 8|8@1+ (1,0) [0|252] "" DIAG,UI
 SG_ TempMax : 16|16@1+ (0.01,0) [0|655.32] "°K" DIAG,UI
 SG_ RsvBits : 0|2@1+ (1,0) [0|0] "" DIAG,UI
 SG_ MsgCount : 2|6@1+ (1,0) [0|0] "" DIAG,UI

BO_ 2147610656 InvStatsExtTemp: 223 INV
 SG_ TempSensId : 8|8@1+ (1,0) [0|252] "" DIAG,UI
 SG_ TempMin : 16|16@1+ (0.01,0) [0|655.32] "°K" DIAG,UI
 SG_ TempMax : 32|16@1+ (0.01,0) [0|655.32] "°K" DIAG,UI
 SG_ RsvBits : 0|2@1+ (1,0) [0|0] "" DIAG,UI
 SG_ MsgCount : 2|6@1+ (1,0) [0|0] "" DIAG,UI

BO_ 2147610819 InvStatsDc2: 223 INV
 SG_ VoltageMin : 72|32@1- (0.001,0) [-2.14748E+06|2.14748E+06] "V" DIAG,UI
 SG_ VoltageMax : 104|32@1- (0.001,0) [-2.14748E+06|2.14748E+06] "V" DIAG,UI
 SG_ RsvBits : 0|2@1+ (1,0) [0|0] "" DIAG,UI
 SG_ PreviousPeriodCount : 19|5@1+ (1,0) [0|0] "" DIAG,UI
 SG_ PreviousPeriod : 16|3@1+ (1,0) [0|0] "" DIAG,UI
 SG_ NumDcUvDetect : 24|16@1+ (1,0) [0|65532] "" DIAG,UI
 SG_ MsgCount : 2|6@1+ (1,0) [0|0] "" DIAG,UI
 SG_ DcSrcId : 8|8@1+ (1,0) [0|252] "" DIAG,UI
 SG_ CurrentMax : 40|32@1- (0.001,0) [-2.14748E+06|2.14748E+06] "Amps" DIAG,UI
 SG_ CapacityConsumed : 136|32@1- (1,0) [-2.14748E+09|2.14748E+09] "Ah" DIAG,UI

BO_ 2147610654 InvStatsDc: 12 INV
 SG_ VoltageMin : 32|32@1- (0.001,0) [-2.14748E+06|2.14748E+06] "V" DIAG,UI
 SG_ VoltageMax : 64|32@1- (0.001,0) [-2.14748E+06|2.14748E+06] "V" DIAG,UI
 SG_ RsvBits : 0|2@1+ (1,0) [0|0] "" DIAG,UI
 SG_ NumDcUvDetect : 16|16@1+ (1,0) [0|65532] "" DIAG,UI
 SG_ MsgCount : 2|6@1+ (1,0) [0|0] "" DIAG,UI
 SG_ DcSrcId : 8|8@1+ (1,0) [0|252] "" DIAG,UI

BO_ 2147610818 InvStatsAc2: 223 INV
 SG_ VoltageMin : 64|32@1+ (0.001,0) [0|4.29497E+06] "V" DIAG,UI
 SG_ VoltageMax : 96|32@1+ (0.001,0) [0|4.29497E+06] "V" DIAG,UI
 SG_ RsvBits : 0|2@1+ (1,0) [0|0] "" DIAG,UI
 SG_ RealPwrMax : 128|32@1+ (1,0) [0|4.29497E+09] "W" DIAG,UI
 SG_ PreviousPeriodCount : 19|5@1+ (1,0) [0|0] "" DIAG,UI
 SG_ PreviousPeriod : 16|3@1+ (1,0) [0|0] "" DIAG,UI
 SG_ MsgCount : 2|6@1+ (1,0) [0|0] "" DIAG,UI
 SG_ Line : 24|8@1+ (1,0) [0|252] "" DIAG,UI
 SG_ InvTime : 192|32@1+ (1,0) [0|4.29497E+09] "seconds" DIAG,UI
 SG_ Energy : 160|32@1+ (1,0) [0|4.29497E+09] "W h" DIAG,UI
 SG_ CurrentMax : 32|32@1+ (0.001,0) [0|4.29497E+06] "Amps" DIAG,UI
 SG_ AcSrcId : 8|8@1+ (1,0) [0|252] "" DIAG,UI

BO_ 2147610640 InvStatsAc: 223 INV
 SG_ VoltageMin : 208|32@1+ (0.001,0) [0|4.29497E+06] "V" DIAG,UI
 SG_ VoltageMax : 240|32@1+ (0.001,0) [0|4.29497E+06] "V" DIAG,UI
 SG_ TotalInvTimeToday : 152|16@1+ (1,0) [0|65532] "minutes" DIAG,UI
 SG_ TotalFlag : 8|2@1+ (1,0) [0|0] "" DIAG,UI
 SG_ TotalEnergyToday : 88|32@1+ (1,0) [0|4.29497E+09] "W h" DIAG,UI
 SG_ TotalEnergyLife : 120|32@1+ (1,0) [0|4.29497E+09] "W h" DIAG,UI
 SG_ RsvBits2 : 10|6@1+ (1,0) [0|0] "" DIAG,UI
 SG_ RsvBits1 : 0|2@1+ (1,0) [0|0] "" DIAG,UI
 SG_ RealPwrMax : 56|32@1+ (1,0) [0|4.29497E+09] "W" DIAG,UI
 SG_ NumTimesLoadSenseEngaged : 40|16@1+ (1,0) [0|65532] "" DIAG,UI
 SG_ NumInvAcOutOL : 24|16@1+ (1,0) [0|65532] "" DIAG,UI
 SG_ MsgCount : 2|6@1+ (1,0) [0|0] "" DIAG,UI
 SG_ Line : 168|8@1+ (1,0) [0|252] "" DIAG,UI
 SG_ CurrentMax : 176|32@1+ (0.001,0) [0|4.29497E+06] "Amps" DIAG,UI
 SG_ AcSrcId : 16|8@1+ (1,0) [0|252] "" DIAG,UI

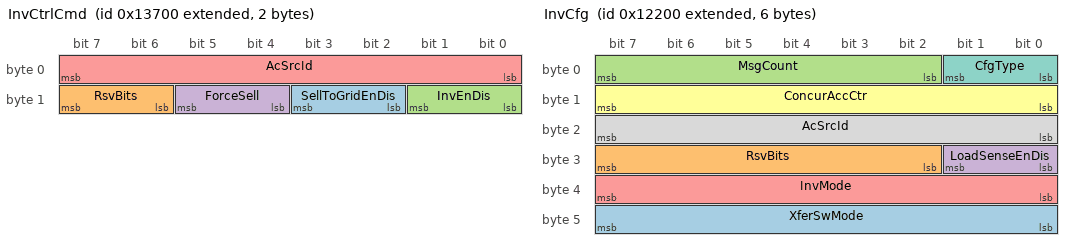
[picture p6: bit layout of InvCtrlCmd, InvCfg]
BO_ 2147563264 InvCtrlCmd: 2 BMS
 SG_ SellToGridEnDis : 10|2@1+ (1,0) [0|0] "" INV,INV_CHG,xNova,xSolarWave
 SG_ RsvBits : 14|2@1+ (1,0) [0|0] "" INV,INV_CHG,xNova,xSolarWave
 SG_ InvEnDis : 8|2@1+ (1,0) [0|0] "" INV,INV_CHG,xNova,xSolarWave
 SG_ ForceSell : 12|2@1+ (1,0) [0|0] "" INV,INV_CHG,xNova,xSolarWave
 SG_ AcSrcId : 0|8@1+ (1,0) [0|252] "" INV,INV_CHG,xNova,xSolarWave

BO_ 2147557632 InvCfgLoadSense: 15 DIAG
 SG_ MsgCount : 2|6@1+ (1,0) [0|0] "" DIAG,INV,INV_CHG,UI,xNova,xSolarWave
 SG_ LoadSensePwrThreshMin : 40|16@1+ (1,0) [0|65532] "W" DIAG,INV,INV_CHG,UI,xNova,xSolarWave
 SG_ LoadSensePwrThreshMax : 56|16@1+ (1,0) [0|65532] "W" DIAG,INV,INV_CHG,UI,xNova,xSolarWave
 SG_ LoadSensePwrThresh : 24|16@1+ (1,0) [0|65532] "W" DIAG,INV,INV_CHG,UI,xNova,xSolarWave
 SG_ LoadSenseIntervalMin : 88|16@1+ (0.01,0) [0|655.32] "seconds" DIAG,INV,INV_CHG,UI,xNova,xSolarWave
 SG_ LoadSenseIntervalMax : 104|16@1+ (0.01,0) [0|655.32] "seconds" DIAG,INV,INV_CHG,UI,xNova,xSolarWave
 SG_ LoadSenseInterval : 72|16@1+ (0.01,0) [0|655.32] "seconds" DIAG,INV,INV_CHG,UI,xNova,xSolarWave
 SG_ ConcurAccCtr : 8|8@1+ (1,0) [0|252] "" DIAG,INV,INV_CHG,UI,xNova,xSolarWave
 SG_ CfgType : 0|2@1+ (1,0) [0|0] "" DIAG,INV,INV_CHG,UI,xNova,xSolarWave
 SG_ AcSrcId : 16|8@1+ (1,0) [0|252] "" DIAG,INV,INV_CHG,UI,xNova,xSolarWave

BO_ 2147557888 InvCfg: 6 DIAG
 SG_ XferSwMode : 40|8@1+ (1,0) [0|252] "" DIAG,INV,INV_CHG,UI,xNova,xSolarWave
 SG_ RsvBits : 26|6@1+ (1,0) [0|0] "" DIAG,INV,INV_CHG,UI,xNova,xSolarWave
 SG_ MsgCount : 2|6@1+ (1,0) [0|0] "" DIAG,INV,INV_CHG,UI,xNova,xSolarWave
 SG_ LoadSenseEnDis : 24|2@1+ (1,0) [0|0] "" DIAG,INV,INV_CHG,UI,xNova,xSolarWave
 SG_ InvMode : 32|8@1+ (1,0) [0|252] "" DIAG,INV,INV_CHG,UI,xNova,xSolarWave
 SG_ ConcurAccCtr : 8|8@1+ (1,0) [0|252] "" DIAG,INV,INV_CHG,UI,xNova,xSolarWave
 SG_ CfgType : 0|2@1+ (1,0) [0|0] "" DIAG,INV,INV_CHG,UI,xNova,xSolarWave
 SG_ AcSrcId : 16|8@1+ (1,0) [0|252] "" DIAG,INV,INV_CHG,UI,xNova,xSolarWave

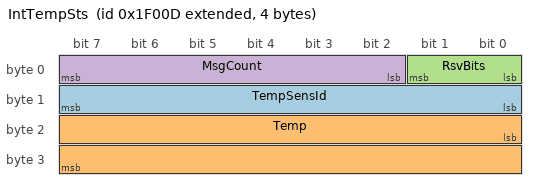
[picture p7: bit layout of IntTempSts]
BO_ 2147610637 IntTempSts: 4 AGS
 SG_ TempSensId : 8|8@1+ (1,0) [0|252] "" AGS,BATTMON,CHG,DIAG,INV,INV_CHG,UI
 SG_ Temp : 16|16@1+ (0.01,0) [0|655.32] "°K" AGS,BATTMON,CHG,DIAG,INV,INV_CHG,UI
 SG_ RsvBits : 0|2@1+ (1,0) [0|0] "" AGS,BATTMON,CHG,DIAG,INV,INV_CHG,UI
 SG_ MsgCount : 2|6@1+ (1,0) [0|0] "" AGS,BATTMON,CHG,DIAG,INV,INV_CHG,UI

BO_ 2147610824 IntTempStats2: 223 AGS
 SG_ TempSensId : 8|8@1+ (1,0) [0|252] "" DIAG,UI
 SG_ TempMin : 24|16@1+ (0.01,0) [0|655.32] "°K" DIAG,UI
 SG_ TempMax : 40|16@1+ (0.01,0) [0|655.32] "°K" DIAG,UI
 SG_ RsvBits : 0|2@1+ (1,0) [0|0] "" DIAG,UI
 SG_ PreviousPeriodCount : 19|5@1+ (1,0) [0|0] "" DIAG,UI
 SG_ PreviousPeriod : 16|3@1+ (1,0) [0|0] "" DIAG,UI
 SG_ MsgCount : 2|6@1+ (1,0) [0|0] "" DIAG,UI

BO_TX_BU_ 2147612871 : xSolarWave,BATTMON,AGS,INV,CHG,UI,INV_CHG,DIAG,GATEWAY,xSolarSurveyor,EMS,BMS;
BO_TX_BU_ 2147612684 : xMiata_AGS,BATTMON,AGS,INV,CHG,UI,INV_CHG,DIAG,GATEWAY,xNova;
BO_TX_BU_ 2147567104 : UI,DIAG;
BO_TX_BU_ 2147570944 : UI,DIAG;
BO_TX_BU_ 2147566080 : UI,DIAG;
BO_TX_BU_ 2147566336 : UI,DIAG;
BO_TX_BU_ 2147566848 : UI,DIAG;
BO_TX_BU_ 2147570688 : UI,DIAG;
BO_TX_BU_ 2147566592 : UI,DIAG;
BO_TX_BU_ 2147565824 : UI,DIAG;
BO_TX_BU_ 2147610642 : xMiata_AGS,xSolarWave,BATTMON,AGS,INV,CHG,UI,INV_CHG,DIAG,GATEWAY,xSolarSurveyor,EMS,BMS;
BO_TX_BU_ 2147558144 : xMiata_AGS,xSolarWave,BATTMON,AGS,INV,CHG,UI,INV_CHG,DIAG,GATEWAY,xSolarSurveyor,EMS,BMS;
BO_TX_BU_ 2147612686 : xMiata_AGS,xSolarWave,BATTMON,AGS,INV,CHG,UI,INV_CHG,DIAG,GATEWAY,xNova,xSolarSurveyor,EMS,BMS;
BO_TX_BU_ 2147610639 : xMiata_AGS,xSolarWave,BATTMON,AGS,INV,CHG,UI,INV_CHG,DIAG,GATEWAY,xNova,xSolarSurveyor,EMS,BMS;
BO_TX_BU_ 2147605760 : xSolarWave,BATTMON,AGS,INV,CHG,UI,INV_CHG,DIAG,GATEWAY,xSolarSurveyor,EMS;
BO_TX_BU_ 2147612873 : xSolarWave,BATTMON,AGS,INV,CHG,UI,INV_CHG,DIAG,GATEWAY,xSolarSurveyor,EMS,BMS;
BO_TX_BU_ 2147612687 : xMiata_AGS,xSolarWave,BATTMON,AGS,INV,CHG,UI,INV_CHG,DIAG,GATEWAY,xNova,xSolarSurveyor;
BO_TX_BU_ 2147610822 : xSolarWave,DIAG,xSolarSurveyor;
BO_TX_BU_ 2147599616 : UI,DIAG;
BO_TX_BU_ 2147600128 : xSolarWave,UI,DIAG,xSolarSurveyor,BMS;
BO_TX_BU_ 2147574272 : xSolarWave,INV,CHG,UI,INV_CHG,DIAG,xSolarSurveyor,BMS;
BO_TX_BU_ 2147599872 : xSolarWave,UI,DIAG,xSolarSurveyor,BMS;
BO_TX_BU_ 2147563520 : xSolarWave,BATTMON,DIAG,xNova,xSolarSurveyor,EMS;
BO_TX_BU_ 2147562240 : xMiata_AGS,xSolarWave,BATTMON,AGS,INV,CHG,UI,INV_CHG,DIAG,GATEWAY,xNova,xSolarSurveyor,EMS,BMS;
BO_TX_BU_ 2147575040 : BATTMON,UI,DIAG;
BO_TX_BU_ 2147606272 : xSolarWave,INV,UI,INV_CHG,DIAG,xNova;
BO_TX_BU_ 2147558400 : UI,DIAG;
BO_TX_BU_ 2147610644 : xMiata_AGS,xSolarWave,BATTMON,AGS,INV,CHG,UI,INV_CHG,DIAG,GATEWAY,xNova,xSolarSurveyor,EMS,BMS;
BO_TX_BU_ 2147610112 : xMiata_AGS,xSolarWave,BATTMON,AGS,INV,CHG,UI,INV_CHG,DIAG,GATEWAY,xNova,xSolarSurveyor,EMS,BMS;
BO_TX_BU_ 2147560704 : xMiata_AGS,xSolarWave,BATTMON,AGS,INV,CHG,UI,INV_CHG,DIAG,GATEWAY,xNova,xSolarSurveyor,EMS,BMS;
BO_TX_BU_ 2147610634 : INV,CHG,INV_CHG,DIAG,xNova;
BO_TX_BU_ 2147553024 : INV,CHG,INV_CHG,DIAG;
BO_TX_BU_ 2147553280 : INV,CHG,INV_CHG,DIAG;
BO_TX_BU_ 2147564032 : xMiata_AGS,xSolarWave,BATTMON,AGS,INV,CHG,UI,INV_CHG,DIAG,GATEWAY,xNova,xSolarSurveyor,EMS,BMS;
BO_TX_BU_ 2147610825 : INV,CHG,INV_CHG,xSolarSurveyor;
BO_TX_BU_ 2147543808 : xMiata_AGS,xSolarWave,BATTMON,AGS,INV,CHG,UI,INV_CHG,DIAG,GATEWAY,xNova,xSolarSurveyor,EMS,BMS;
BO_TX_BU_ 2147544064 : xMiata_AGS,xSolarWave,BATTMON,AGS,INV,CHG,UI,INV_CHG,DIAG,GATEWAY,xNova,xSolarSurveyor,EMS,BMS;
BO_TX_BU_ 2147543552 : xSolarWave,BATTMON,AGS,INV,CHG,UI,INV_CHG,DIAG,GATEWAY,xSolarSurveyor,EMS,BMS;
BO_TX_BU_ 2147544576 : xMiata_AGS,xSolarWave,BATTMON,AGS,INV,CHG,UI,INV_CHG,DIAG,GATEWAY,xNova,xSolarSurveyor,EMS,BMS;
BO_TX_BU_ 2147543040 : xMiata_AGS,xSolarWave,BATTMON,AGS,INV,CHG,UI,INV_CHG,DIAG,GATEWAY,xNova,xSolarSurveyor,EMS,BMS;
BO_TX_BU_ 2147610653 : xSolarWave,INV,INV_CHG;
BO_TX_BU_ 2147610813 : xSolarWave,INV,INV_CHG;
BO_TX_BU_ 2147610649 : INV,INV_CHG,xNova;
BO_TX_BU_ 2147610655 : xSolarWave,INV,INV_CHG,xNova;
BO_TX_BU_ 2147610656 : xSolarWave,INV,INV_CHG,xNova;
BO_TX_BU_ 2147610819 : xSolarWave,INV,INV_CHG;
BO_TX_BU_ 2147610654 : INV,INV_CHG,xNova;
BO_TX_BU_ 2147610818 : xSolarWave,INV,INV_CHG;
BO_TX_BU_ 2147610640 : INV,INV_CHG,xNova;
BO_TX_BU_ 2147563264 : UI,DIAG,GATEWAY,BMS;
BO_TX_BU_ 2147557632 : xSolarWave,INV,UI,INV_CHG,DIAG,xNova;
BO_TX_BU_ 2147557888 : xSolarWave,INV,UI,INV_CHG,DIAG,xNova;
BO_TX_BU_ 2147610637 : xSolarWave,BATTMON,AGS,INV,CHG,UI,INV_CHG,DIAG,xNova,xSolarSurveyor;
BO_TX_BU_ 2147610824 : BATTMON,AGS,INV,CHG,UI,INV_CHG,GATEWAY;

CM_ BO_ 2147612871 "Warning Log Status (Deux)";
CM_ SG_ 2147612871 WarnType "Warning Type";
CM_ SG_ 2147612871 WarnTime "Warning Time";
CM_ SG_ 2147612871 WarnId "Warning Identifier";
CM_ SG_ 2147612871 StringId "String Identifier";
CM_ SG_ 2147612871 RsvBits "Reserved Bits";
CM_ SG_ 2147612871 MsgCount "Message Count";
CM_ BO_ 2147612684 "Warning Log Status";
CM_ SG_ 2147612684 WarnType "Warning Type";
CM_ SG_ 2147612684 WarnTime "Warning Time";
CM_ SG_ 2147612684 WarnId "Warning Identifier";
CM_ SG_ 2147612684 RsvBits "Reserved Bits";
CM_ SG_ 2147612684 MsgCount "Message Count";
CM_ BO_ 2147610652 "User Interface Status";
CM_ SG_ 2147610652 RsvBits "Reserved Bits";
CM_ SG_ 2147610652 OpState "Operating State";
CM_ SG_ 2147610652 MsgCount "Message Count";
CM_ BO_ 2147567104 "User Interface Configuration - Warnings Text";
CM_ SG_ 2147567104 WarnType "Warning Type";
CM_ SG_ 2147567104 WarnTxt "Warning Text";
CM_ SG_ 2147567104 WarnId "Warning Identifier";
CM_ SG_ 2147567104 MsgCount "Message Count";
CM_ SG_ 2147567104 ConcurAccCtr "Concurrent Access Counter";
CM_ SG_ 2147567104 CfgType "Configuration Type";
CM_ BO_ 2147570944 "User Interface Configuration - Warnings Behaviour";
CM_ SG_ 2147570944 WarnId "Warning Identifier";
CM_ SG_ 2147570944 WarnBehaviour "Warning Behaviour";
CM_ SG_ 2147570944 MsgCount "Message Count";
CM_ SG_ 2147570944 ConcurAccCtr "Concurrent Access Counter";
CM_ SG_ 2147570944 CfgType "Configuration Type";
CM_ BO_ 2147566080 "User Interface Configuration - Splash Image";
CM_ SG_ 2147566080 Rows "Number of Pixel Rows";
CM_ SG_ 2147566080 MsgCount "Message Count";
CM_ SG_ 2147566080 ImgDepth "Image Depth";
CM_ SG_ 2147566080 Image "Image Data";
CM_ SG_ 2147566080 ConcurAccCtr "Concurrent Access Counter";
CM_ SG_ 2147566080 Cols "Number of Pixel Columns";
CM_ SG_ 2147566080 CfgType "Configuration Type";
CM_ BO_ 2147566336 "User Interface Configuration - Node Labels";
CM_ SG_ 2147566336 SystemInstance "System Instance (ISO Device Class Instance)";
CM_ SG_ 2147566336 RsvBit4 "Reserved Bit";
CM_ SG_ 2147566336 RsvBit1 "Reserved Bit";
CM_ SG_ 2147566336 NodeLbl "Node Label";
CM_ SG_ 2147566336 MsgCount "Message Count";
CM_ SG_ 2147566336 DeviceInstanceUpper "Device Instance Upper (ISO Function Instance)";
CM_ SG_ 2147566336 DeviceInstanceLower "Device Instance Lower (ISO ECU Instance)";
CM_ SG_ 2147566336 DeviceFunction "Device Function (ISO Function)";
CM_ SG_ 2147566336 DeviceClass "Device Class";
CM_ SG_ 2147566336 ConcurAccCtr "Concurrent Access Counter";
CM_ SG_ 2147566336 CfgType "Configuration Type";
CM_ BO_ 2147566848 "User Interface Configuration - Faults Text";
CM_ SG_ 2147566848 MsgCount "Message Count";
CM_ SG_ 2147566848 FaultType "Fault Type";
CM_ SG_ 2147566848 FaultTxt "Fault Text";
CM_ SG_ 2147566848 FaultId "Fault Identifier";
CM_ SG_ 2147566848 ConcurAccCtr "Concurrent Access Counter";
CM_ SG_ 2147566848 CfgType "Configuration Type";
CM_ BO_ 2147570688 "User Interface Configuration - Faults Behaviour";
CM_ SG_ 2147570688 MsgCount "Message Count";
CM_ SG_ 2147570688 FaultId "Fault Identifier";
CM_ SG_ 2147570688 FaultBehaviour "Fault Behaviour";
CM_ SG_ 2147570688 ConcurAccCtr "Concurrent Access Counter";
CM_ SG_ 2147570688 CfgType "Configuration Type";
CM_ BO_ 2147566592 "User Interface Configuration - Association Labels";
CM_ SG_ 2147566592 RsvBits "Reserved Bits";
CM_ SG_ 2147566592 MsgCount "Message Count";
CM_ SG_ 2147566592 ConcurAccCtr "Concurrent Access Counter";
CM_ SG_ 2147566592 CfgType "Configuration Type";
CM_ SG_ 2147566592 AssocType "Association Type";
CM_ SG_ 2147566592 AssocLbl "Association Label";
CM_ SG_ 2147566592 AssocId "Association Identifier";
CM_ BO_ 2147565824 "User Interface Configuration";
CM_ SG_ 2147565824 WarnSndEnDis "Warning Sound Enable/Disable";
CM_ SG_ 2147565824 Vol "Volume";
CM_ SG_ 2147565824 TimeFmt "Time Format";
CM_ SG_ 2147565824 SplashScrnTo "Splash Screen Timeout";
CM_ SG_ 2147565824 SplashScrnStyl "Splash Screen Style";
CM_ SG_ 2147565824 SplashOnWakeEnDis "Splash Screen on Wakeup Enable/Disable";
CM_ SG_ 2147565824 SndEnDis "Sound Enable/Disable";
CM_ SG_ 2147565824 ScrnSaveTo "Screen Saver Timeout";
CM_ SG_ 2147565824 RsvBits "Reserved Bits";
CM_ SG_ 2147565824 MsgCount "Message Count";
CM_ SG_ 2147565824 MeasUnit "Measurement Unit";
CM_ SG_ 2147565824 FaultSndEnDis "Fault Sound Enable/Disable";
CM_ SG_ 2147565824 DispSeqTo "Display Seqeunce Timeout";
CM_ SG_ 2147565824 DispContrast "Display Contrast";
CM_ SG_ 2147565824 DispBright "Display Brightness";
CM_ SG_ 2147565824 ConcurAccCtr "Concurrent Access Counter";
CM_ SG_ 2147565824 CfgType "Configuration Type";
CM_ SG_ 2147565824 BtnSndEnDis "Button Sound Enable/Disable";
CM_ SG_ 2147565824 BtnRptRate "Button Repeat Rate";
CM_ SG_ 2147565824 BtnHoldTo "Button Hold Timeout";
CM_ SG_ 2147565824 BkltTo "Backlight Timeout";
CM_ SG_ 2147565824 AccMode "Access Mode";
CM_ BO_ 2147610642 "System Identifier Status";
CM_ SG_ 2147610642 SysId "System Identifier";
CM_ SG_ 2147610642 RsvBits "Reserved Bits";
CM_ SG_ 2147610642 MsgCount "Message Count";
CM_ BO_ 2147558144 "System Identifier Configuration";
CM_ SG_ 2147558144 SysId "System Identifier";
CM_ SG_ 2147558144 RsvBits "Reserved Bits";
CM_ SG_ 2147558144 MsgCount "Message Count";
CM_ BO_ 2147612686 "Software Version Status";
CM_ SG_ 2147612686 SwVer "Software Version";
CM_ SG_ 2147612686 SwModId "Software Module Identifier";
CM_ SG_ 2147612686 SwBldNum "Software Build Number";
CM_ SG_ 2147612686 RsvBits2 "Reserved Bits 2";
CM_ SG_ 2147612686 RsvBits1 "Reserved Bits 1";
CM_ SG_ 2147612686 ProcessorInst "Controller or Processor Instance";
CM_ SG_ 2147612686 MsgCount "Message Count";
CM_ BO_ 2147610639 "Status";
CM_ SG_ 2147610639 WarnsChangedFlag "Warnings Changed Flag";
CM_ SG_ 2147610639 WarnFlag "Warning Flag";
CM_ SG_ 2147610639 RsvBits "Reserved Bits";
CM_ SG_ 2147610639 PerTxEnDis "Periodic Transmit Enable/Disable";
CM_ SG_ 2147610639 NewWarnsFlag "New Warnings Flag";
CM_ SG_ 2147610639 NewFaultsFlag "New Faults Flag";
CM_ SG_ 2147610639 NetworkState "Network State";
CM_ SG_ 2147610639 MsgCount "Message Count";
CM_ SG_ 2147610639 LastMode "Last Mode";
CM_ SG_ 2147610639 FaultsChangedFlag "Faults Changed Flag";
CM_ SG_ 2147610639 FaultFlag "Fault Flag";
CM_ SG_ 2147610639 DesiredMode "Desired Mode";
CM_ SG_ 2147610639 CurrentMode "Current Mode";
CM_ BO_ 2147605760 "String Configuration";
CM_ SG_ 2147605760 StringId "String Identifier";
CM_ SG_ 2147605760 MsgCount "Message Count";
CM_ SG_ 2147605760 ConcurAccCtr "Concurrent Access Counter";
CM_ SG_ 2147605760 CharType "Character Type";
CM_ SG_ 2147605760 CfgType "Configuration Type";
CM_ SG_ 2147605760 Byte "Byte";
CM_ BO_ 2147612873 "State/Event Log Status( Duex )";
CM_ SG_ 2147612873 StringId "String Identifier";
CM_ SG_ 2147612873 StateId "State Identifier";
CM_ SG_ 2147612873 RsvBits "Reserved Bits";
CM_ SG_ 2147612873 MsgCount "Message Count";
CM_ SG_ 2147612873 EvtTime "Event Time";
CM_ SG_ 2147612873 EvtId "Event Identifier";
CM_ BO_ 2147612687 "State/Event Log Status";
CM_ SG_ 2147612687 StateId "State Identifier";
CM_ SG_ 2147612687 RsvBits "Reserved Bits";
CM_ SG_ 2147612687 MsgCount "Message Count";
CM_ SG_ 2147612687 EvtTime "Event Time";
CM_ SG_ 2147612687 EvtId "Event Identifier";
CM_ BO_ 2147610822 "Secondary Power Supply Status";
CM_ SG_ 2147610822 Voltage "Voltage";
CM_ SG_ 2147610822 RsvBits "Reserved Bits";
CM_ SG_ 2147610822 OutputId "Output Identifier";
CM_ SG_ 2147610822 OpState "Operating State";
CM_ SG_ 2147610822 OnReason "On Reason";
CM_ SG_ 2147610822 OffReason "Off Reason";
CM_ SG_ 2147610822 MsgCount "Message Count";
CM_ SG_ 2147610822 Current "Current";
CM_ BO_ 2147599616 "Secondary Power Supply Control Command";
CM_ SG_ 2147599616 OutputId "Output Identifier";
CM_ SG_ 2147599616 DesiredState "Desired State";
CM_ BO_ 2147600128 "Secondary Power Supply Configuration - Triggers";
CM_ SG_ 2147600128 TrigEnDis "Trigger Enabled/Disabled";
CM_ SG_ 2147600128 RsvBits "Reserved Bits";
CM_ SG_ 2147600128 OutputId "Output Identifier";
CM_ SG_ 2147600128 MsgCount "Message Count";
CM_ SG_ 2147600128 EvtId "Event Identifier";
CM_ SG_ 2147600128 ConcurAccCtr "Concurrent Access Counter";
CM_ SG_ 2147600128 CfgType "Configuration Type";
CM_ BO_ 2147574272 "Secondary Power Supply Configuration - Battery SOC";
CM_ SG_ 2147574272 TimeIntStopMin "Time Interval to Stop - Min";
CM_ SG_ 2147574272 TimeIntStopMax "Time Interval to Stop - Max";
CM_ SG_ 2147574272 TimeIntStop "Time Interval to Stop";
CM_ SG_ 2147574272 TimeIntStartMin "Time Interval to Start - Min";
CM_ SG_ 2147574272 TimeIntStartMax "Time Interval to Start - Max";
CM_ SG_ 2147574272 TimeIntStart "Time Interval to Start";
CM_ SG_ 2147574272 SocLvlStopMin "State of Charge Level to Stop - Min";
CM_ SG_ 2147574272 SocLvlStopMax "State of Charge Level to Stop - Max";
CM_ SG_ 2147574272 SocLvlStop "State of Charge Level to Stop";
CM_ SG_ 2147574272 SocLvlStartMin "State of Charge Level to Start - Min";
CM_ SG_ 2147574272 SocLvlStartMax "State of Charge Level to Start - Max";
CM_ SG_ 2147574272 SocLvlStart "State of Charge Level to Start";
CM_ SG_ 2147574272 OutputId "Output Identifier";
CM_ SG_ 2147574272 MsgCount "Message Count";
CM_ SG_ 2147574272 DcSrcId "DC Source Identifier";
CM_ SG_ 2147574272 ConcurAccCtr "Concurrent Access Counter";
CM_ SG_ 2147574272 CfgType "Configuration Type";
CM_ BO_ 2147599872 "Secondary Power Supply Configuration";
CM_ SG_ 2147599872 VoltageMin "Voltage - Min";
CM_ SG_ 2147599872 VoltageMax "Voltage - Max";
CM_ SG_ 2147599872 Voltage "Voltage";
CM_ SG_ 2147599872 RsvBits "Reserved Bits";
CM_ SG_ 2147599872 OutputId "Output Identifier";
CM_ SG_ 2147599872 MsgCount "Message Count";
CM_ SG_ 2147599872 CurrentMin "Current - Min";
CM_ SG_ 2147599872 CurrentMax "Current - Max";
CM_ SG_ 2147599872 Current "Current";
CM_ SG_ 2147599872 ConcurAccCtr "Concurrent Access Counter";
CM_ SG_ 2147599872 CfgType "Configuration Type";
CM_ SG_ 2147599872 ActiveLevel "Active Level";
CM_ BO_ 2147563520 "Simple Calibration Configuration";
CM_ SG_ 2147563520 Value "Value";
CM_ SG_ 2147563520 StsPgn "Status Parameter Group Number";
CM_ SG_ 2147563520 Scale "Scaling Factor (k)";
CM_ SG_ 2147563520 RsvBits "Reserved Bits";
CM_ SG_ 2147563520 Offset "Offset";
CM_ SG_ 2147563520 MsgCount "Message Count";
CM_ SG_ 2147563520 DataPtId "Data Point Identifier";
CM_ BO_ 2147562240 "Receive Timeout Configuration";
CM_ SG_ 2147562240 Timeout "Timeout";
CM_ SG_ 2147562240 ParmGrpNum "Parameter Group Number";
CM_ SG_ 2147562240 MsgCount "Message Count";
CM_ SG_ 2147562240 ConcurAccCtr "Concurrent Access Counter";
CM_ SG_ 2147562240 CfgType "Configuration Type";
CM_ BO_ 2147575040 "RS485 Configuration";
CM_ SG_ 2147575040 StopBits "RS485 Stop Bits";
CM_ SG_ 2147575040 RsvBits "Reserved Bits";
CM_ SG_ 2147575040 Parity "RS485 Parity";
CM_ SG_ 2147575040 MsgCount "Message Count";
CM_ SG_ 2147575040 ConcurAccCtr "Concurrent Access Counter";
CM_ SG_ 2147575040 CfgType "Configuration Type";
CM_ SG_ 2147575040 ByteOrder "Modbus Byte Order";
CM_ SG_ 2147575040 BaudRate "RS485 Baud Rate";
CM_ SG_ 2147575040 Address "RS485 Address";
CM_ BO_ 2147606272 "Remote Procedure Call Command";
CM_ SG_ 2147606272 ProcedureId "Procedure Identifier";
CM_ SG_ 2147606272 ProcedureArg "Procedure Argument";
CM_ BO_ 2147558400 "Reset Command";
CM_ SG_ 2147558400 RsvBits "Reserved Bits";
CM_ SG_ 2147558400 ProcessorInst "Controller Instance";
CM_ SG_ 2147558400 Cmd "Command";
CM_ BO_ 2147610644 "Product Information Status";
CM_ SG_ 2147610644 RsvBits "Reserved Bits";
CM_ SG_ 2147610644 PwrLvl "Power Level";
CM_ SG_ 2147610644 NomDcLvl "Nominal DC Level";
CM_ SG_ 2147610644 NomAcOutFreq "Nominal AC Output Frequency";
CM_ SG_ 2147610644 NomAcLvl "Nominal AC Level";
CM_ SG_ 2147610644 MsgCount "Message Count";
CM_ SG_ 2147610644 ModelName "Model Name";
CM_ SG_ 2147610644 Fga "Finished Goods Assembly";
CM_ BO_ 2147610826 "PID Control Loop Status";
CM_ SG_ 2147610826 RsvBits "Reserved Bits";
CM_ SG_ 2147610826 Reference "Loop Reference Value";
CM_ SG_ 2147610826 Readback "Loop Readback Value";
CM_ SG_ 2147610826 PropTerm "Proportional Term";
CM_ SG_ 2147610826 Output "Loop Output";
CM_ SG_ 2147610826 MsgCount "Message Count";
CM_ SG_ 2147610826 LoopId "PID Control Loop Identifier";
CM_ SG_ 2147610826 IntTerm "Integral Term";
CM_ SG_ 2147610826 IntErrterm "Integral Error Term";
CM_ SG_ 2147610826 ExtraField2 "Extra Field 2";
CM_ SG_ 2147610826 ExtraField1 "Extra Field 1";
CM_ SG_ 2147610826 ErrTerm "Error Term";
CM_ SG_ 2147610826 DerTerm "Derivative Term";
CM_ SG_ 2147610826 DerErrTerm "Derivative Error Term";
CM_ BO_ 2147600640 "PID Control Loop Configuration";
CM_ SG_ 2147600640 ResBits1 "Reserve Bits";
CM_ SG_ 2147600640 OutputMin "Minimum output clamp value";
CM_ SG_ 2147600640 OutputMax "Maximum output clamp value";
CM_ SG_ 2147600640 MsgCount "Message Count";
CM_ SG_ 2147600640 LoopId "PID Control Loop Identifier";
CM_ SG_ 2147600640 LoopFreq "Loop Frequency";
CM_ SG_ 2147600640 LoopEnDis "PID Control Loop Enable/Disable";
CM_ SG_ 2147600640 Kp "Proportional Gain";
CM_ SG_ 2147600640 Ki "Integral Gain";
CM_ SG_ 2147600640 Kd "Derivative Gain";
CM_ SG_ 2147600640 ExtraField2 "Extra Field 2";
CM_ SG_ 2147600640 ExtraField1 "Extra Field 1";
CM_ SG_ 2147600640 ConcurAccCtr "Concurrent Access Counter";
CM_ SG_ 2147600640 CfgType "Configuration Type";
CM_ BO_ 2147610112 "PGN List - ";
CM_ SG_ 2147610112 TXPgns_0 "Transmittable PGNs";
CM_ SG_ 2147610112 TXedPgnGroupFunctionCode "Transmitted PGN Group Function Code";
CM_ SG_ 2147610112 RXPgns_1 "Receivable PGNs";
CM_ BO_ 2147560704 "Periodic Transmit Configuration";
CM_ SG_ 2147560704 XmitPeriod "Transmit Period";
CM_ SG_ 2147560704 XmitAddr "Transmit Address";
CM_ SG_ 2147560704 ParmGrpNum "PGN to Transmit";
CM_ SG_ 2147560704 MsgCount "Message Count";
CM_ SG_ 2147560704 ConcurAccCtr "Concurrent Access Counter";
CM_ SG_ 2147560704 CfgType "Configuration Type";
CM_ BO_ 2147610634 "Offline Power Supply Status";
CM_ SG_ 2147610634 Voltage "Voltage";
CM_ SG_ 2147610634 RsvBits "Reserved Bits";
CM_ SG_ 2147610634 OutputId "Output Identifier";
CM_ SG_ 2147610634 MsgCount "Message Count";
CM_ SG_ 2147610634 Current "Current";
CM_ BO_ 2147553024 "Offline Power Supply Configuration - Under Voltage";
CM_ SG_ 2147553024 UvLvlMin "Under Voltage Level - Minimum";
CM_ SG_ 2147553024 UvLvlMax "Under Voltage Level - Maximum";
CM_ SG_ 2147553024 UvLvl "Under Voltage Level";
CM_ SG_ 2147553024 UvIntvlMin "Under Voltage Interval - Minimum";
CM_ SG_ 2147553024 UvIntvlMax "Under Voltage Interval - Maximum";
CM_ SG_ 2147553024 UvIntvl "Under Voltage Interval";
CM_ SG_ 2147553024 RefEvtId "Reference Event Identifier";
CM_ SG_ 2147553024 OutputId "Output Identifier";
CM_ SG_ 2147553024 MsgCount "Message Count";
CM_ SG_ 2147553024 EvtId "Event Identifier";
CM_ SG_ 2147553024 ConcurAccCtr "Concurrent Access Counter";
CM_ SG_ 2147553024 CfgType "Configuration Type";
CM_ BO_ 2147553280 "Offline Power Supply Configuration - Over Voltage";
CM_ SG_ 2147553280 RefEvtId "Reference Event Identifier";
CM_ SG_ 2147553280 OvLvlMin "Over Voltage Level - Minimum";
CM_ SG_ 2147553280 OvLvlMax "Over Voltage Level - Maximum";
CM_ SG_ 2147553280 OvLvl "Over Voltage Level";
CM_ SG_ 2147553280 OvIntvlMin "Over Voltage Interval - Minimum";
CM_ SG_ 2147553280 OvIntvlMax "Over Voltage Interval - Maximum";
CM_ SG_ 2147553280 OvIntvl "Over Voltage Interval";
CM_ SG_ 2147553280 OutputId "Output Identifier";
CM_ SG_ 2147553280 MsgCount "Message Count";
CM_ SG_ 2147553280 EvtId "Event Identifier";
CM_ SG_ 2147553280 ConcurAccCtr "Concurrent Access Counter";
CM_ SG_ 2147553280 CfgType "Configuration Type";
CM_ BO_ 2147564032 "NAME Configuration";
CM_ SG_ 2147564032 UniqueNumber "Unique Number (ISO Identity Number)";
CM_ SG_ 2147564032 SystemInstance "System Instance (ISO Device Class Instance)";
CM_ SG_ 2147564032 SelfCfgAddr "ISO Self Configurable Address";
CM_ SG_ 2147564032 RsvBit "Reserved Bit";
CM_ SG_ 2147564032 MsgCount "Message Count";
CM_ SG_ 2147564032 ManufacturerCode "Manufacturer Code";
CM_ SG_ 2147564032 IndustryGroup "Industry Group";
CM_ SG_ 2147564032 DeviceInstanceUpper "Device Instance Upper (ISO Function Instance)";
CM_ SG_ 2147564032 DeviceInstanceLower "Device Instance Lower (ISO ECU Instance)";
CM_ SG_ 2147564032 DeviceFunction "Device Function (ISO Function)";
CM_ SG_ 2147564032 DeviceClass "Device Class";
CM_ SG_ 2147564032 ConcurAccCtr "Concurrent Access Counter";
CM_ SG_ 2147564032 CfgType "Configuration Type";
CM_ BO_ 2147610825 "Maximum Power Point Tracker Status";
CM_ SG_ 2147610825 RsvBits "Reserved Bits";
CM_ SG_ 2147610825 MsgCount "Message Count";
CM_ SG_ 2147610825 MpptMode "MPPT Mode";
CM_ BO_ 2147543808 "ISO Transport Protocol, Data Transfer";
CM_ SG_ 2147543808 SeqNumMultiPacketFrame "Sequence number of multi-packet frame";
CM_ SG_ 2147543808 MultiPacketPacketizedData "Multi-packet packetized data";
CM_ BO_ 2147544064 "ISO Transport Protocol, Connection Management - ";
CM_ SG_ 2147544064 TotalNumFramesXmit_16 "Total number of frames to be transmitted";
CM_ SG_ 2147544064 TotalNumFramesToBeSent_32 "Total number of frames to be sent";
CM_ SG_ 2147544064 TotalNumFramesRXed_19 "Total number of frames received";
CM_ SG_ 2147544064 TotalMsgSz_16 "Total message size, bytes";
CM_ SG_ 2147544064 TotalMsgSz_32 "Total message size, bytes";
CM_ SG_ 2147544064 TotalMsgSz_19 "Total message size, bytes";
CM_ SG_ 2147544064 RTSGroupFunctionCode "RTS Group Function Code";
CM_ SG_ 2147544064 RsvBits_255 "Reserved Bits";
CM_ SG_ 2147544064 RsvBits_32 "Reserved Bits";
CM_ SG_ 2147544064 RsvBits_19 "Reserved Bits";
CM_ SG_ 2147544064 RsvBits_17 "Reserved Bits";
CM_ SG_ 2147544064 RsvBits_16 "Reserved Bits";
CM_ SG_ 2147544064 ParmGrpNum_16 "PGN of multi-packet message";
CM_ SG_ 2147544064 ParmGrpNum_32 "PGN of multi-packet message";
CM_ SG_ 2147544064 ParmGrpNum_17 "PGN of multi-packet message";
CM_ SG_ 2147544064 ParmGrpNum_255 "PGN of multi-packet message";
CM_ SG_ 2147544064 ParmGrpNum_19 "PGN of multi-packet message";
CM_ SG_ 2147544064 NumNextFrameToBeSent_17 "Number of next frame to be sent";
CM_ SG_ 2147544064 NumFramesThatCanBeSent_17 "Number of frames that can be sent";
CM_ BO_ 2147543552 "ISO Request";
CM_ SG_ 2147543552 ParmGrpNum "PGN being requested";
CM_ BO_ 2147548888 "ISO Commanded Address";
CM_ SG_ 2147548888 UniqueNumber "Unique Number (ISO Identity Number)";
CM_ SG_ 2147548888 SystemInstance "System Instance (ISO Device Class Instance)";
CM_ SG_ 2147548888 SelfCfgAddr "ISO Self Configurable Address";
CM_ SG_ 2147548888 RsvBit "Reserved Bit";
CM_ SG_ 2147548888 PrefSrcAddr "Preferred Source Address";
CM_ SG_ 2147548888 ManufacturerCode "Manufacturer Code";
CM_ SG_ 2147548888 IndustryGroup "Industry Group";
CM_ SG_ 2147548888 DeviceInstanceUpper "Device Instance Upper (ISO Function Instance)";
CM_ SG_ 2147548888 DeviceInstanceLower "Device Instance Lower (ISO ECU Instance)";
CM_ SG_ 2147548888 DeviceFunction "Device Function (ISO Function)";
CM_ SG_ 2147548888 DeviceClass "Device Class";
CM_ BO_ 2147544576 "ISO Address Claim";
CM_ SG_ 2147544576 UniqueNumber "Unique Number (ISO Identity Number)";
CM_ SG_ 2147544576 SystemInstance "System Instance (ISO Device Class Instance)";
CM_ SG_ 2147544576 SelfCfgAddr "ISO Self Configurable Address";
CM_ SG_ 2147544576 RsvBit "Reserved Bit";
CM_ SG_ 2147544576 ManufacturerCode "Manufacturer Code";
CM_ SG_ 2147544576 IndustryGroup "Industry Group";
CM_ SG_ 2147544576 DeviceInstanceUpper "Device Instance Upper (ISO Function Instance)";
CM_ SG_ 2147544576 DeviceInstanceLower "Device Instance Lower (ISO ECU Instance)";
CM_ SG_ 2147544576 DeviceFunction "Device Function (ISO Function)";
CM_ SG_ 2147544576 DeviceClass "Device Class";
CM_ BO_ 2147543040 "ISO Acknowledgment";
CM_ SG_ 2147543040 RsvBits "Reserved Bits";
CM_ SG_ 2147543040 ParmGrpNum "PGN of Requested Information";
CM_ SG_ 2147543040 GroupFunctionValue "Group Function Value";
CM_ SG_ 2147543040 CtrlByte "Control Byte";
CM_ BO_ 2147610653 "Inverter Status - Load Share (High Speed)";
CM_ SG_ 2147610653 Line "Line";
CM_ SG_ 2147610653 Current "Current";
CM_ SG_ 2147610653 AcSrcId "AC Source ID";
CM_ BO_ 2147610813 "Inverter Status (Deux)";
CM_ SG_ 2147610813 SellToGridEnDis "Sell Enable/Disable";
CM_ SG_ 2147610813 RsvBits2 "Reserved Bits";
CM_ SG_ 2147610813 RsvBits2 "Reserved Bits 2";
CM_ SG_ 2147610813 RsvBits1 "Reserved Bits 1";
CM_ SG_ 2147610813 PeakLoadShavingEnDis "Peak Load Shaving Enable/Disable";
CM_ SG_ 2147610813 OpState "Operating State";
CM_ SG_ 2147610813 MsgCount "Message Count";
CM_ SG_ 2147610813 InvMode "Inverter Mode";
CM_ SG_ 2147610813 InvEnDis "Inverter Enable/Disable";
CM_ SG_ 2147610813 GridEnDis "Grid Enable/Disable";
CM_ SG_ 2147610813 ForceSell "Force Sell On/Off";
CM_ SG_ 2147610813 BattTempSensorPresent "Battery Temperature Sensor Present";
CM_ SG_ 2147610813 AntiIslandingEnDis "Anti Islanading Enable/Disable";
CM_ SG_ 2147610813 AcSrcId "AC Source Identifier";
CM_ BO_ 2147610649 "Inverter Status";
CM_ SG_ 2147610649 SellToGridEnDis "Sell Enable/Disable";
CM_ SG_ 2147610649 RsvBits2 "Reserved Bits 2";
CM_ SG_ 2147610649 RsvBits1 "Reserved Bits 1";
CM_ SG_ 2147610649 OpState "Operating State";
CM_ SG_ 2147610649 MsgCount "Message Count";
CM_ SG_ 2147610649 InvEnDis "Inverter Enable/Disable";
CM_ SG_ 2147610649 BattTempSensorPresent "Battery Temperature Sensor Present";
CM_ SG_ 2147610649 AcSrcId "AC Source Identifier";
CM_ BO_ 2147610655 "Inverter Statistics - Internal Temperature";
CM_ SG_ 2147610655 TempSensId "Temperature Sensor Identifier";
CM_ SG_ 2147610655 TempMax "Highest Recorded Temperature";
CM_ SG_ 2147610655 RsvBits "Reserved Bits";
CM_ SG_ 2147610655 MsgCount "Message Count";
CM_ BO_ 2147610656 "Inverter Statistics - External Temperature";
CM_ SG_ 2147610656 TempSensId "Temperature Sensor Identifier";
CM_ SG_ 2147610656 TempMin "Lowest Recorded Temperature";
CM_ SG_ 2147610656 TempMax "Highest Recorded Temperature";
CM_ SG_ 2147610656 RsvBits "Reserved Bits";
CM_ SG_ 2147610656 MsgCount "Message Count";
CM_ BO_ 2147610819 "Inverter Statistics - DC (Deux)";
CM_ SG_ 2147610819 VoltageMin "Lowest DC Voltage";
CM_ SG_ 2147610819 VoltageMax "Highest DC Voltage";
CM_ SG_ 2147610819 RsvBits "Reserved Bits";
CM_ SG_ 2147610819 PreviousPeriodCount "Previous Period Count";
CM_ SG_ 2147610819 PreviousPeriod "Previous Period";
CM_ SG_ 2147610819 NumDcUvDetect "Number of DC Under Voltage Detections";
CM_ SG_ 2147610819 MsgCount "Message Count";
CM_ SG_ 2147610819 DcSrcId "DC Source Identifier";
CM_ SG_ 2147610819 CurrentMax "Current Maximum";
CM_ SG_ 2147610819 CapacityConsumed "CapacityConsumed";
CM_ BO_ 2147610654 "Inverter Statistics - DC";
CM_ SG_ 2147610654 VoltageMin "Lowest DC Voltage";
CM_ SG_ 2147610654 VoltageMax "Highest DC Voltage";
CM_ SG_ 2147610654 RsvBits "Reserved Bits";
CM_ SG_ 2147610654 NumDcUvDetect "Number of DC Under Voltage Detections";
CM_ SG_ 2147610654 MsgCount "Message Count";
CM_ SG_ 2147610654 DcSrcId "DC Source Identifier";
CM_ BO_ 2147610818 "Inverter Statistics - AC (Deux)";
CM_ SG_ 2147610818 VoltageMin "Voltage Minimum";
CM_ SG_ 2147610818 VoltageMax "Voltage Maximum";
CM_ SG_ 2147610818 RsvBits "Reserved Bits";
CM_ SG_ 2147610818 RealPwrMax "Real Power Maximum";
CM_ SG_ 2147610818 PreviousPeriodCount "Previous Period Count";
CM_ SG_ 2147610818 PreviousPeriod "Previous Period";
CM_ SG_ 2147610818 MsgCount "Message Count";
CM_ SG_ 2147610818 Line "Line";
CM_ SG_ 2147610818 InvTime "Inverter Time";
CM_ SG_ 2147610818 Energy "Energy";
CM_ SG_ 2147610818 CurrentMax "Current Maximum";
CM_ SG_ 2147610818 AcSrcId "AC Source Identifier";
CM_ BO_ 2147610640 "Inverter Statistics - AC";
CM_ SG_ 2147610640 VoltageMin "Lowest AC Output Voltage";
CM_ SG_ 2147610640 VoltageMax "Highest AC Output Voltage";
CM_ SG_ 2147610640 TotalInvTimeToday "Total Invert Time Today";
CM_ SG_ 2147610640 TotalFlag "Total Flag";
CM_ SG_ 2147610640 TotalEnergyToday "Total Energy Delivered Today";
CM_ SG_ 2147610640 TotalEnergyLife "Total Energy Delivered Over the Lifetime";
CM_ SG_ 2147610640 RsvBits2 "Reserved Bits 2";
CM_ SG_ 2147610640 RsvBits1 "Reserved Bits 1";
CM_ SG_ 2147610640 RealPwrMax "Highest Output Power";
CM_ SG_ 2147610640 NumTimesLoadSenseEngaged "Number of Times Load Sense has been Engaged";
CM_ SG_ 2147610640 NumInvAcOutOL "Number of Inverter AC Output Over-loads";
CM_ SG_ 2147610640 MsgCount "Message Count";
CM_ SG_ 2147610640 Line "Line";
CM_ SG_ 2147610640 CurrentMax "Highest AC Output Current";
CM_ SG_ 2147610640 AcSrcId "AC Source Identifier";
CM_ BO_ 2147563264 "Inverter Control Command";
CM_ SG_ 2147563264 SellToGridEnDis "Sell Enable/Disable";
CM_ SG_ 2147563264 RsvBits "Reserved Bits";
CM_ SG_ 2147563264 InvEnDis "Inverter Enable/Disable";
CM_ SG_ 2147563264 ForceSell "Force Sell On/Off";
CM_ SG_ 2147563264 AcSrcId "AC Source Identifier";
CM_ BO_ 2147557632 "Inverter Configuration - Load Sense";
CM_ SG_ 2147557632 MsgCount "Message Count";
CM_ SG_ 2147557632 LoadSensePwrThreshMin "Load Sense Power Threshold - Minimum";
CM_ SG_ 2147557632 LoadSensePwrThreshMax "Load Sense Power Threshold - Maximum";
CM_ SG_ 2147557632 LoadSensePwrThresh "Load Sense Power Threshold";
CM_ SG_ 2147557632 LoadSenseIntervalMin "Load Sense Interval - Minimum";
CM_ SG_ 2147557632 LoadSenseIntervalMax "Load Sense Interval - Maximum";
CM_ SG_ 2147557632 LoadSenseInterval "Load Sense Interval";
CM_ SG_ 2147557632 ConcurAccCtr "Concurrent Access Counter";
CM_ SG_ 2147557632 CfgType "Configuration Type";
CM_ SG_ 2147557632 AcSrcId "AC Source Identifier";
CM_ BO_ 2147557888 "Inverter Configuration";
CM_ SG_ 2147557888 XferSwMode "Transfer Switch Mode";
CM_ SG_ 2147557888 RsvBits "Reserved Bits";
CM_ SG_ 2147557888 MsgCount "Message Count";
CM_ SG_ 2147557888 LoadSenseEnDis "Load Sense Enable/Disable";
CM_ SG_ 2147557888 InvMode "Inverter Mode";
CM_ SG_ 2147557888 ConcurAccCtr "Concurrent Access Counter";
CM_ SG_ 2147557888 CfgType "Configuration Type";
CM_ SG_ 2147557888 AcSrcId "AC Source Identifier";
CM_ BO_ 2147610637 "Internal Temperature Status";
CM_ SG_ 2147610637 TempSensId "Temperature Sensor Identifier";
CM_ SG_ 2147610637 Temp "Temperature";
CM_ SG_ 2147610637 RsvBits "Reserved Bits";
CM_ SG_ 2147610637 MsgCount "Message Count";
CM_ BO_ 2147610824 "Internal Temperature Statistics (Deux)";
CM_ SG_ 2147610824 TempSensId "Temperature Sensor Identifier";
CM_ SG_ 2147610824 TempMin "Temperature Minimum";
CM_ SG_ 2147610824 TempMax "Temperature Maximum";
CM_ SG_ 2147610824 RsvBits "Reserved Bits";
CM_ SG_ 2147610824 PreviousPeriodCount "Previous Period Count";
CM_ SG_ 2147610824 PreviousPeriod "Previous Period";
CM_ SG_ 2147610824 MsgCount "Message Count";
BA_DEF_  "IsNMEA" INT 0 1;
BA_DEF_ BO_  "J1939PGPrio" INT 0 7;
BA_DEF_ BO_  "J1939PGR1" INT 0 1;
BA_DEF_ BO_  "J1939PGDest" INT 0 255;
BA_DEF_ BO_  "J1939PGSrc" INT 0 255;
BA_DEF_ BO_  "CycleTime" INT 5 1000;
BA_DEF_ BO_  "SingleFrame" INT 0 1;
BA_DEF_DEF_  "IsNMEA" 1;
BA_DEF_DEF_  "J1939PGPrio" 0;
BA_DEF_DEF_  "J1939PGR1" 0;
BA_DEF_DEF_  "J1939PGDest" 0;
BA_DEF_DEF_  "J1939PGSrc" 0;
BA_DEF_DEF_  "CycleTime" 100;
BA_DEF_DEF_  "SingleFrame" 0;
BA_ "J1939PGPrio" BO_ 2147612871 6;
BA_ "J1939PGDest" BO_ 2147612871 255;
BA_ "J1939PGPrio" BO_ 2147612684 6;
BA_ "J1939PGDest" BO_ 2147612684 255;
BA_ "J1939PGPrio" BO_ 2147610652 6;
BA_ "J1939PGDest" BO_ 2147610652 255;
BA_ "CycleTime" BO_ 2147610652 500;
BA_ "SingleFrame" BO_ 2147610652 1;
BA_ "J1939PGPrio" BO_ 2147567104 6;
BA_ "J1939PGDest" BO_ 2147567104 255;
BA_ "SingleFrame" BO_ 2147567104 1;
BA_ "J1939PGPrio" BO_ 2147570944 6;
BA_ "J1939PGDest" BO_ 2147570944 255;
BA_ "J1939PGPrio" BO_ 2147566080 6;
BA_ "J1939PGDest" BO_ 2147566080 255;
BA_ "SingleFrame" BO_ 2147566080 1;
BA_ "J1939PGPrio" BO_ 2147566336 6;
BA_ "J1939PGDest" BO_ 2147566336 255;
BA_ "SingleFrame" BO_ 2147566336 1;
BA_ "J1939PGPrio" BO_ 2147566848 6;
BA_ "J1939PGDest" BO_ 2147566848 255;
BA_ "SingleFrame" BO_ 2147566848 1;
BA_ "J1939PGPrio" BO_ 2147570688 6;
BA_ "J1939PGDest" BO_ 2147570688 255;
BA_ "J1939PGPrio" BO_ 2147566592 6;
BA_ "J1939PGDest" BO_ 2147566592 255;
BA_ "SingleFrame" BO_ 2147566592 1;
BA_ "J1939PGPrio" BO_ 2147565824 6;
BA_ "J1939PGDest" BO_ 2147565824 255;
BA_ "J1939PGPrio" BO_ 2147610642 6;
BA_ "J1939PGDest" BO_ 2147610642 255;
BA_ "SingleFrame" BO_ 2147610642 1;
BA_ "J1939PGPrio" BO_ 2147558144 6;
BA_ "J1939PGDest" BO_ 2147558144 255;
BA_ "SingleFrame" BO_ 2147558144 1;
BA_ "J1939PGPrio" BO_ 2147612686 6;
BA_ "J1939PGDest" BO_ 2147612686 255;
BA_ "J1939PGPrio" BO_ 2147610639 6;
BA_ "J1939PGDest" BO_ 2147610639 255;
BA_ "CycleTime" BO_ 2147610639 250;
BA_ "SingleFrame" BO_ 2147610639 1;
BA_ "J1939PGPrio" BO_ 2147605760 6;
BA_ "J1939PGDest" BO_ 2147605760 255;
BA_ "J1939PGPrio" BO_ 2147612873 6;
BA_ "J1939PGDest" BO_ 2147612873 255;
BA_ "CycleTime" BO_ 2147612873 5;
BA_ "J1939PGPrio" BO_ 2147612687 6;
BA_ "J1939PGDest" BO_ 2147612687 255;
BA_ "J1939PGPrio" BO_ 2147610822 6;
BA_ "J1939PGDest" BO_ 2147610822 255;
BA_ "CycleTime" BO_ 2147610822 500;
BA_ "J1939PGPrio" BO_ 2147599616 6;
BA_ "J1939PGDest" BO_ 2147599616 255;
BA_ "SingleFrame" BO_ 2147599616 1;
BA_ "J1939PGPrio" BO_ 2147600128 6;
BA_ "J1939PGDest" BO_ 2147600128 255;
BA_ "J1939PGPrio" BO_ 2147574272 6;
BA_ "J1939PGDest" BO_ 2147574272 255;
BA_ "J1939PGPrio" BO_ 2147599872 6;
BA_ "J1939PGDest" BO_ 2147599872 255;
BA_ "J1939PGPrio" BO_ 2147563520 6;
BA_ "J1939PGDest" BO_ 2147563520 255;
BA_ "J1939PGPrio" BO_ 2147562240 6;
BA_ "J1939PGDest" BO_ 2147562240 255;
BA_ "J1939PGPrio" BO_ 2147575040 6;
BA_ "J1939PGDest" BO_ 2147575040 255;
BA_ "SingleFrame" BO_ 2147575040 1;
BA_ "J1939PGPrio" BO_ 2147606272 6;
BA_ "J1939PGDest" BO_ 2147606272 255;
BA_ "CycleTime" BO_ 2147606272 5;
BA_ "J1939PGPrio" BO_ 2147558400 6;
BA_ "J1939PGDest" BO_ 2147558400 255;
BA_ "SingleFrame" BO_ 2147558400 1;
BA_ "J1939PGPrio" BO_ 2147610644 6;
BA_ "J1939PGDest" BO_ 2147610644 255;
BA_ "J1939PGPrio" BO_ 2147610826 6;
BA_ "J1939PGDest" BO_ 2147610826 255;
BA_ "CycleTime" BO_ 2147610826 5;
BA_ "J1939PGPrio" BO_ 2147600640 6;
BA_ "J1939PGDest" BO_ 2147600640 255;
BA_ "CycleTime" BO_ 2147600640 5;
BA_ "J1939PGPrio" BO_ 2147610112 6;
BA_ "J1939PGDest" BO_ 2147610112 255;
BA_ "SingleFrame" BO_ 2147610112 1;
BA_ "J1939PGPrio" BO_ 2147560704 6;
BA_ "J1939PGDest" BO_ 2147560704 255;
BA_ "J1939PGPrio" BO_ 2147610634 6;
BA_ "J1939PGDest" BO_ 2147610634 255;
BA_ "J1939PGPrio" BO_ 2147553024 6;
BA_ "J1939PGDest" BO_ 2147553024 255;
BA_ "J1939PGPrio" BO_ 2147553280 6;
BA_ "J1939PGDest" BO_ 2147553280 255;
BA_ "J1939PGPrio" BO_ 2147564032 6;
BA_ "J1939PGDest" BO_ 2147564032 255;
BA_ "J1939PGPrio" BO_ 2147610825 6;
BA_ "J1939PGDest" BO_ 2147610825 255;
BA_ "CycleTime" BO_ 2147610825 5;
BA_ "SingleFrame" BO_ 2147610825 1;
BA_ "J1939PGPrio" BO_ 2147543808 7;
BA_ "J1939PGDest" BO_ 2147543808 255;
BA_ "SingleFrame" BO_ 2147543808 1;
BA_ "J1939PGPrio" BO_ 2147544064 7;
BA_ "J1939PGDest" BO_ 2147544064 255;
BA_ "SingleFrame" BO_ 2147544064 1;
BA_ "J1939PGPrio" BO_ 2147543552 6;
BA_ "J1939PGDest" BO_ 2147543552 255;
BA_ "SingleFrame" BO_ 2147543552 1;
BA_ "J1939PGPrio" BO_ 2147548888 6;
BA_ "J1939PGDest" BO_ 2147548888 255;
BA_ "SingleFrame" BO_ 2147548888 1;
BA_ "J1939PGPrio" BO_ 2147544576 6;
BA_ "J1939PGDest" BO_ 2147544576 255;
BA_ "CycleTime" BO_ 2147544576 1000;
BA_ "SingleFrame" BO_ 2147544576 1;
BA_ "J1939PGPrio" BO_ 2147543040 6;
BA_ "J1939PGDest" BO_ 2147543040 255;
BA_ "SingleFrame" BO_ 2147543040 1;
BA_ "J1939PGPrio" BO_ 2147610653 2;
BA_ "J1939PGDest" BO_ 2147610653 255;
BA_ "SingleFrame" BO_ 2147610653 1;
BA_ "J1939PGPrio" BO_ 2147610813 6;
BA_ "J1939PGDest" BO_ 2147610813 255;
BA_ "CycleTime" BO_ 2147610813 500;
BA_ "SingleFrame" BO_ 2147610813 1;
BA_ "J1939PGPrio" BO_ 2147610649 6;
BA_ "J1939PGDest" BO_ 2147610649 255;
BA_ "CycleTime" BO_ 2147610649 500;
BA_ "SingleFrame" BO_ 2147610649 1;
BA_ "J1939PGPrio" BO_ 2147610655 6;
BA_ "J1939PGDest" BO_ 2147610655 255;
BA_ "J1939PGPrio" BO_ 2147610656 6;
BA_ "J1939PGDest" BO_ 2147610656 255;
BA_ "J1939PGPrio" BO_ 2147610819 6;
BA_ "J1939PGDest" BO_ 2147610819 255;
BA_ "J1939PGPrio" BO_ 2147610654 6;
BA_ "J1939PGDest" BO_ 2147610654 255;
BA_ "J1939PGPrio" BO_ 2147610818 6;
BA_ "J1939PGDest" BO_ 2147610818 255;
BA_ "J1939PGPrio" BO_ 2147610640 6;
BA_ "J1939PGDest" BO_ 2147610640 255;
BA_ "J1939PGPrio" BO_ 2147563264 6;
BA_ "J1939PGDest" BO_ 2147563264 255;
BA_ "SingleFrame" BO_ 2147563264 1;
BA_ "J1939PGPrio" BO_ 2147557632 6;
BA_ "J1939PGDest" BO_ 2147557632 255;
BA_ "J1939PGPrio" BO_ 2147557888 6;
BA_ "J1939PGDest" BO_ 2147557888 255;
BA_ "SingleFrame" BO_ 2147557888 1;
BA_ "J1939PGPrio" BO_ 2147610637 6;
BA_ "J1939PGDest" BO_ 2147610637 255;
BA_ "SingleFrame" BO_ 2147610637 1;
BA_ "J1939PGPrio" BO_ 2147610824 6;
BA_ "J1939PGDest" BO_ 2147610824 255;
VAL_ 2147612871 WarnType 0 "Auto Reset Warning" 1 "Manual Warning" 5 "Reserved" 6 "Out Of Range" 7 "No Change Data NA" ;
VAL_ 2147612871 WarnId 34 "DC Over Voltage Warning 2" 35 "Heatsink Over Temperature Warning 1" 0 "Transistor Over Temperature Warning 1" 1 "Transistor Over Temperature Warning 2" 2 "Capacitor Over Temperature Warning 1" 3 "Transformer Over Temperature Warning 1" 4 "Battery Over Temperature Warning 1" 5 "Ambient Over Temperature Warning 1" 6 "AC Output Overload Warning" 7 "Auto Restart After Fault Enabled Warning" 9 "Battery Sensor Not Present Warning" 10 "Battery Sensor Short Warning" 11 "DC Over Voltage Warning 1" 12 "DC Under Voltage Warning 1" 13 "AC Line 1 Input Over Voltage Warning" 14 "AC Line 1 Input Under Voltage Warning" 15 "AC Line 2 Input Over Voltage Warning" 16 "AC Line 2 Input Under Voltage Warning" 18 "Cannot Equalize" 19 "Equalization Terminated Abnormally" 20 "AC Output Over Voltage Warning 1" 21 "AC Output Under Voltage Warning 1" 22 "AC Output Over Voltage Warning 2" 23 "AC Output Under Voltage Warning 2" 24 "Generator Line 1 Input Over Voltage Warning" 25 "Generator Line 1 Input Under Voltage Warning" 26 "Generator Line 2 Input Over Voltage Warning" 27 "Generator Line 2 Input Under Voltage Warning" 28 "Generator Line 1 Input Over Frequency Warning" 29 "Generator Line 1 Input Under Frequency Warning" 30 "Generator Line 2 Input Over Frequency Warning" 31 "Generator Line 2 Input Under Frequency Warning" 32 "AC Input L1 L2 120 Over Frequency Warning" 33 "AC Input L1 L2 120 Under Frequency Warning" 200 "External Genset Shutdown Warning" 201 "External Genset Startup Warning" 202 "Unable To Start Genset Warning" 203 "Reached Max Run Time Warning" 204 "Max Genset Cycle With No Intervention Warning" 205 "Gen On Not Ags" 206 "Orphaned Auto Start Trigger" 207 "Orphaned Auto Stop Trigger" 208 "No Auto Triggers Defined" 209 "Gen Off Not Ags" 250 "Failed To Set Value Warning" 251 "Confirm Equalization Warning" 252 "Confirm Restore Defaults Warning" 253 "Aborted Equalization" 254 "Failed To Set Value Due To System Mode" 255 "Clock Not Set" 256 "Device Lost" 257 "New Device" 258 "Node Instance Duplicated" 500 "Lost Network Connection" 501 "Defaults Restored On Powerup Warning" 502 "Missing Expected Status" 599 "Associations Invalid" 8189 "Reserved" 8190 "Out Of Range" 8191 "No Change Data NA" ;
VAL_ 2147612684 WarnType 0 "Auto Reset Warning" 1 "Manual Warning" 5 "Reserved" 6 "Out Of Range" 7 "No Change Data NA" ;
VAL_ 2147612684 WarnId 34 "DC Over Voltage Warning 2" 35 "Heatsink Over Temperature Warning 1" 0 "Transistor Over Temperature Warning 1" 1 "Transistor Over Temperature Warning 2" 2 "Capacitor Over Temperature Warning 1" 3 "Transformer Over Temperature Warning 1" 4 "Battery Over Temperature Warning 1" 5 "Ambient Over Temperature Warning 1" 6 "AC Output Overload Warning" 7 "Auto Restart After Fault Enabled Warning" 9 "Battery Sensor Not Present Warning" 10 "Battery Sensor Short Warning" 11 "DC Over Voltage Warning 1" 12 "DC Under Voltage Warning 1" 13 "AC Line 1 Input Over Voltage Warning" 14 "AC Line 1 Input Under Voltage Warning" 15 "AC Line 2 Input Over Voltage Warning" 16 "AC Line 2 Input Under Voltage Warning" 18 "Cannot Equalize" 19 "Equalization Terminated Abnormally" 20 "AC Output Over Voltage Warning 1" 21 "AC Output Under Voltage Warning 1" 22 "AC Output Over Voltage Warning 2" 23 "AC Output Under Voltage Warning 2" 24 "Generator Line 1 Input Over Voltage Warning" 25 "Generator Line 1 Input Under Voltage Warning" 26 "Generator Line 2 Input Over Voltage Warning" 27 "Generator Line 2 Input Under Voltage Warning" 28 "Generator Line 1 Input Over Frequency Warning" 29 "Generator Line 1 Input Under Frequency Warning" 30 "Generator Line 2 Input Over Frequency Warning" 31 "Generator Line 2 Input Under Frequency Warning" 32 "AC Input L1 L2 120 Over Frequency Warning" 33 "AC Input L1 L2 120 Under Frequency Warning" 200 "External Genset Shutdown Warning" 201 "External Genset Startup Warning" 202 "Unable To Start Genset Warning" 203 "Reached Max Run Time Warning" 204 "Max Genset Cycle With No Intervention Warning" 205 "Gen On Not Ags" 206 "Orphaned Auto Start Trigger" 207 "Orphaned Auto Stop Trigger" 208 "No Auto Triggers Defined" 209 "Gen Off Not Ags" 250 "Failed To Set Value Warning" 251 "Confirm Equalization Warning" 252 "Confirm Restore Defaults Warning" 253 "Aborted Equalization" 254 "Failed To Set Value Due To System Mode" 255 "Clock Not Set" 256 "Device Lost" 257 "New Device" 258 "Node Instance Duplicated" 500 "Lost Network Connection" 501 "Defaults Restored On Powerup Warning" 502 "Missing Expected Status" 599 "Associations Invalid" 8189 "Reserved" 8190 "Out Of Range" 8191 "No Change Data NA" ;
VAL_ 2147610652 OpState 1280 "Screen Saver" 1281 "Active" ;
VAL_ 2147567104 WarnType 0 "Auto Reset Warning" 1 "Manual Warning" 5 "Reserved" 6 "Out Of Range" 7 "No Change Data NA" ;
VAL_ 2147567104 WarnId 34 "DC Over Voltage Warning 2" 35 "Heatsink Over Temperature Warning 1" 0 "Transistor Over Temperature Warning 1" 1 "Transistor Over Temperature Warning 2" 2 "Capacitor Over Temperature Warning 1" 3 "Transformer Over Temperature Warning 1" 4 "Battery Over Temperature Warning 1" 5 "Ambient Over Temperature Warning 1" 6 "AC Output Overload Warning" 7 "Auto Restart After Fault Enabled Warning" 9 "Battery Sensor Not Present Warning" 10 "Battery Sensor Short Warning" 11 "DC Over Voltage Warning 1" 12 "DC Under Voltage Warning 1" 13 "AC Line 1 Input Over Voltage Warning" 14 "AC Line 1 Input Under Voltage Warning" 15 "AC Line 2 Input Over Voltage Warning" 16 "AC Line 2 Input Under Voltage Warning" 18 "Cannot Equalize" 19 "Equalization Terminated Abnormally" 20 "AC Output Over Voltage Warning 1" 21 "AC Output Under Voltage Warning 1" 22 "AC Output Over Voltage Warning 2" 23 "AC Output Under Voltage Warning 2" 24 "Generator Line 1 Input Over Voltage Warning" 25 "Generator Line 1 Input Under Voltage Warning" 26 "Generator Line 2 Input Over Voltage Warning" 27 "Generator Line 2 Input Under Voltage Warning" 28 "Generator Line 1 Input Over Frequency Warning" 29 "Generator Line 1 Input Under Frequency Warning" 30 "Generator Line 2 Input Over Frequency Warning" 31 "Generator Line 2 Input Under Frequency Warning" 32 "AC Input L1 L2 120 Over Frequency Warning" 33 "AC Input L1 L2 120 Under Frequency Warning" 200 "External Genset Shutdown Warning" 201 "External Genset Startup Warning" 202 "Unable To Start Genset Warning" 203 "Reached Max Run Time Warning" 204 "Max Genset Cycle With No Intervention Warning" 205 "Gen On Not Ags" 206 "Orphaned Auto Start Trigger" 207 "Orphaned Auto Stop Trigger" 208 "No Auto Triggers Defined" 209 "Gen Off Not Ags" 250 "Failed To Set Value Warning" 251 "Confirm Equalization Warning" 252 "Confirm Restore Defaults Warning" 253 "Aborted Equalization" 254 "Failed To Set Value Due To System Mode" 255 "Clock Not Set" 256 "Device Lost" 257 "New Device" 258 "Node Instance Duplicated" 500 "Lost Network Connection" 501 "Defaults Restored On Powerup Warning" 502 "Missing Expected Status" 599 "Associations Invalid" 8189 "Reserved" 8190 "Out Of Range" 8191 "No Change Data NA" ;
VAL_ 2147567104 CfgType 0 "User" 1 "OEM" 2 "Factory" 3 "Reserved" ;
VAL_ 2147570944 WarnId 34 "DC Over Voltage Warning 2" 35 "Heatsink Over Temperature Warning 1" 0 "Transistor Over Temperature Warning 1" 1 "Transistor Over Temperature Warning 2" 2 "Capacitor Over Temperature Warning 1" 3 "Transformer Over Temperature Warning 1" 4 "Battery Over Temperature Warning 1" 5 "Ambient Over Temperature Warning 1" 6 "AC Output Overload Warning" 7 "Auto Restart After Fault Enabled Warning" 9 "Battery Sensor Not Present Warning" 10 "Battery Sensor Short Warning" 11 "DC Over Voltage Warning 1" 12 "DC Under Voltage Warning 1" 13 "AC Line 1 Input Over Voltage Warning" 14 "AC Line 1 Input Under Voltage Warning" 15 "AC Line 2 Input Over Voltage Warning" 16 "AC Line 2 Input Under Voltage Warning" 18 "Cannot Equalize" 19 "Equalization Terminated Abnormally" 20 "AC Output Over Voltage Warning 1" 21 "AC Output Under Voltage Warning 1" 22 "AC Output Over Voltage Warning 2" 23 "AC Output Under Voltage Warning 2" 24 "Generator Line 1 Input Over Voltage Warning" 25 "Generator Line 1 Input Under Voltage Warning" 26 "Generator Line 2 Input Over Voltage Warning" 27 "Generator Line 2 Input Under Voltage Warning" 28 "Generator Line 1 Input Over Frequency Warning" 29 "Generator Line 1 Input Under Frequency Warning" 30 "Generator Line 2 Input Over Frequency Warning" 31 "Generator Line 2 Input Under Frequency Warning" 32 "AC Input L1 L2 120 Over Frequency Warning" 33 "AC Input L1 L2 120 Under Frequency Warning" 200 "External Genset Shutdown Warning" 201 "External Genset Startup Warning" 202 "Unable To Start Genset Warning" 203 "Reached Max Run Time Warning" 204 "Max Genset Cycle With No Intervention Warning" 205 "Gen On Not Ags" 206 "Orphaned Auto Start Trigger" 207 "Orphaned Auto Stop Trigger" 208 "No Auto Triggers Defined" 209 "Gen Off Not Ags" 250 "Failed To Set Value Warning" 251 "Confirm Equalization Warning" 252 "Confirm Restore Defaults Warning" 253 "Aborted Equalization" 254 "Failed To Set Value Due To System Mode" 255 "Clock Not Set" 256 "Device Lost" 257 "New Device" 258 "Node Instance Duplicated" 500 "Lost Network Connection" 501 "Defaults Restored On Powerup Warning" 502 "Missing Expected Status" 599 "Associations Invalid" 8189 "Reserved" 8190 "Out Of Range" 8191 "No Change Data NA" ;
VAL_ 2147570944 WarnBehaviour 0 "Ignore" 1 "Visual Alert" 2 "Audio Visual Alert" 5 "Reserved" 6 "Out Of Range" 7 "Do Not Change Data Not Available" ;
VAL_ 2147570944 CfgType 0 "User" 1 "OEM" 2 "Factory" 3 "Reserved" ;
VAL_ 2147566080 ImgDepth 1 "Depth1" 2 "Depth2" 3 "Depth3" 4 "Depth4" 8 "Depth8" 16 "Depth16" 24 "Depth24" 32 "Depth32" ;
VAL_ 2147566080 CfgType 0 "User" 1 "OEM" 2 "Factory" 3 "Reserved" ;
VAL_ 2147566336 DeviceFunction 128 "User Interface" 129 "Inverter Charger" 130 "Inverter" 131 "Charger" 132 "Battery Monitor" 133 "AGS" 134 "Diagnostic Terminal" 135 "Gateway" 136 "Energy Management System" 137 "Battery Management System" ;
VAL_ 2147566336 DeviceClass 30 "Power Management" ;
VAL_ 2147566336 CfgType 0 "User" 1 "OEM" 2 "Factory" 3 "Reserved" ;
VAL_ 2147566848 FaultType 0 "Auto Reset Escalating Fault" 1 "Auto Reset Non Escalating Fault" 2 "Manual Fault" 5 "Reserved" 6 "Out Of Range" 7 "No Change Data NA" ;
VAL_ 2147566848 FaultId 73 "DC Over Current Shutdown 2" 74 "DC Over Voltage Shutdown 3" 0 "Transistor Over Temperature Shutdown 1" 1 "Transistor Over Temperature Shutdown 2" 2 "Capacitor Over Temperature Shutdown 1" 3 "Transformer Over Temperature Shutdown 1" 4 "Battery Over Temperature Shutdown 1" 5 "Ambient Over Temperature Shutdown 1" 6 "AC Output Overload Shutdown 1" 7 "AC Output Overload Peak Current Shutdown 1" 8 "Neutral Loss Shutdown" 9 "DC Over Voltage Shutdown 1" 10 "DC Under Voltage Immediate Shutdown 1" 11 "DC Under Voltage Shutdown 1" 12 "AC Input Line 1 Over Voltage Shutdown" 13 "AC Input Line 1 Under Voltage Shutdown" 14 "AC Input Line 2 Over Voltage Shutdown" 15 "AC Input Line 2 Under Voltage Shutdown" 16 "AC Input Line 1 Over Frequency Shutdown" 17 "AC Input Line 1 Under Frequency Shutdown" 18 "AC Input Line 2 Over Frequency Shutdown" 19 "AC Input Line 2 Under Frequency Shutdown" 22 "ADC Conversion Timeout" 23 "AC Output Over Voltage Shutdown 1" 24 "AC Output Under Voltage Shutdown 1" 25 "APS Over Voltage" 26 "APS Under Voltage" 27 "OPS Over Voltage" 28 "OPS Under Voltage" 29 "AC Backfeed Shutdown" 30 "Battery Under Temperature" 31 "Echo Charger Short Circuit" 32 "Echo Charger Reverse Polarity" 33 "Echo Charger Input Over Voltage" 34 "Echo Charger Input Under Voltage" 35 "Echo Charger Over Temperature" 36 "Echo Charger Under Temperature" 37 "Echo Charger Not Communicating" 40 "Lost Interprocessor Communications" 41 "Dead Battery Charge Timeout" 42 "AC Output Over Voltage Shutdown 2" 43 "AC Output Under Voltage Shutdown 2" 44 "Generator Line 1 Input Over Voltage Shutdown" 45 "Generator Line 1 Input Under Voltage Shutdown" 46 "Generator Line 2 Input Over Voltage Shutdown" 47 "Generator Line 2 Input Under Voltage Shutdown" 48 "Generator Line 1 Input Over Frequency Shutdown" 49 "Generator Line 1 Input Under Frequency Shutdown" 50 "Generator Line 2 Input Over Frequency Shutdown" 51 "Generator Line 2 Input Under Frequency Shutdown" 52 "AC Input L1 L2 120 Over Frequency Shutdown" 53 "AC Input L1 L2 120 Under Frequency Shutdown" 54 "APS 1 Off" 55 "Heatsink 1 Over Temperature Shutdown" 56 "Ground Fault" 57 "External Shutdown" 58 "AC Output 1 Voltage Shutdown" 59 "AC Output 1 Frequency Shutdown" 60 "AC Output 1 Impedance Shutdown" 61 "Reconnecting 1" 62 "DC-DC 1 Saturated" 63 "User Shutdown" 64 "Neutral Over Current 1" 65 "Over Voltage Antiislanding" 66 "Under Voltage Antiislanding" 67 "Over Frequency Antiislanding" 68 "Under Frequency Antiislanding" 69 "Battery Conflicting Setup" 70 "DC Over Voltage Shutdown 2" 71 "DC Over Current Shutdown" 72 "SPS Overload" 200 "Max Start Retries" 201 "Unable to Stop Generator" 203 "Gen Stop by Ext Shutdown" 250 "Clock Not Set" 251 "Device Lost" 252 "New Device" 500 "Silicon Serial ID Failure" 501 "Non-Volatile Error" 502 "Watchdog Reset" 503 "Real-time Clock Failure" 504 "Lost Network Connection" 505 "Controller Failure" 506 "Wrong Fault Identifier" 507 "Wrong Warning Identifier" 508 "Invalid Interrupt" 599 "Associations Invalid" 8189 "Reserved" 8190 "Out Of Range" 8191 "No Change Data NA" 75 "Fan Problem 1" 76 "Fan Problem 2" 77 "DC Over Current Shutdown 3" 78 "DC Over Current Shutdown 4" 79 "Fan Problem 3" 80 "Fan Problem 4" 81 "Fan Problem 5" 82 "Network Power Supply Failure" 83 "Battery Discharge Over Current" ;
VAL_ 2147566848 CfgType 0 "User" 1 "OEM" 2 "Factory" 3 "Reserved" ;
VAL_ 2147570688 FaultId 73 "DC Over Current Shutdown 2" 74 "DC Over Voltage Shutdown 3" 0 "Transistor Over Temperature Shutdown 1" 1 "Transistor Over Temperature Shutdown 2" 2 "Capacitor Over Temperature Shutdown 1" 3 "Transformer Over Temperature Shutdown 1" 4 "Battery Over Temperature Shutdown 1" 5 "Ambient Over Temperature Shutdown 1" 6 "AC Output Overload Shutdown 1" 7 "AC Output Overload Peak Current Shutdown 1" 8 "Neutral Loss Shutdown" 9 "DC Over Voltage Shutdown 1" 10 "DC Under Voltage Immediate Shutdown 1" 11 "DC Under Voltage Shutdown 1" 12 "AC Input Line 1 Over Voltage Shutdown" 13 "AC Input Line 1 Under Voltage Shutdown" 14 "AC Input Line 2 Over Voltage Shutdown" 15 "AC Input Line 2 Under Voltage Shutdown" 16 "AC Input Line 1 Over Frequency Shutdown" 17 "AC Input Line 1 Under Frequency Shutdown" 18 "AC Input Line 2 Over Frequency Shutdown" 19 "AC Input Line 2 Under Frequency Shutdown" 22 "ADC Conversion Timeout" 23 "AC Output Over Voltage Shutdown 1" 24 "AC Output Under Voltage Shutdown 1" 25 "APS Over Voltage" 26 "APS Under Voltage" 27 "OPS Over Voltage" 28 "OPS Under Voltage" 29 "AC Backfeed Shutdown" 30 "Battery Under Temperature" 31 "Echo Charger Short Circuit" 32 "Echo Charger Reverse Polarity" 33 "Echo Charger Input Over Voltage" 34 "Echo Charger Input Under Voltage" 35 "Echo Charger Over Temperature" 36 "Echo Charger Under Temperature" 37 "Echo Charger Not Communicating" 40 "Lost Interprocessor Communications" 41 "Dead Battery Charge Timeout" 42 "AC Output Over Voltage Shutdown 2" 43 "AC Output Under Voltage Shutdown 2" 44 "Generator Line 1 Input Over Voltage Shutdown" 45 "Generator Line 1 Input Under Voltage Shutdown" 46 "Generator Line 2 Input Over Voltage Shutdown" 47 "Generator Line 2 Input Under Voltage Shutdown" 48 "Generator Line 1 Input Over Frequency Shutdown" 49 "Generator Line 1 Input Under Frequency Shutdown" 50 "Generator Line 2 Input Over Frequency Shutdown" 51 "Generator Line 2 Input Under Frequency Shutdown" 52 "AC Input L1 L2 120 Over Frequency Shutdown" 53 "AC Input L1 L2 120 Under Frequency Shutdown" 54 "APS 1 Off" 55 "Heatsink 1 Over Temperature Shutdown" 56 "Ground Fault" 57 "External Shutdown" 58 "AC Output 1 Voltage Shutdown" 59 "AC Output 1 Frequency Shutdown" 60 "AC Output 1 Impedance Shutdown" 61 "Reconnecting 1" 62 "DC-DC 1 Saturated" 63 "User Shutdown" 64 "Neutral Over Current 1" 65 "Over Voltage Antiislanding" 66 "Under Voltage Antiislanding" 67 "Over Frequency Antiislanding" 68 "Under Frequency Antiislanding" 69 "Battery Conflicting Setup" 70 "DC Over Voltage Shutdown 2" 71 "DC Over Current Shutdown" 72 "SPS Overload" 200 "Max Start Retries" 201 "Unable to Stop Generator" 203 "Gen Stop by Ext Shutdown" 250 "Clock Not Set" 251 "Device Lost" 252 "New Device" 500 "Silicon Serial ID Failure" 501 "Non-Volatile Error" 502 "Watchdog Reset" 503 "Real-time Clock Failure" 504 "Lost Network Connection" 505 "Controller Failure" 506 "Wrong Fault Identifier" 507 "Wrong Warning Identifier" 508 "Invalid Interrupt" 599 "Associations Invalid" 8189 "Reserved" 8190 "Out Of Range" 8191 "No Change Data NA" 75 "Fan Problem 1" 76 "Fan Problem 2" 77 "DC Over Current Shutdown 3" 78 "DC Over Current Shutdown 4" 79 "Fan Problem 3" 80 "Fan Problem 4" 81 "Fan Problem 5" 82 "Network Power Supply Failure" 83 "Battery Discharge Over Current" ;
VAL_ 2147570688 FaultBehaviour 0 "Ignore" 1 "Visual Alert" 2 "Audio Visual Alert" 5 "Reserved" 6 "Out Of Range" 7 "Do Not Change Data Not Available" ;
VAL_ 2147570688 CfgType 0 "User" 1 "OEM" 2 "Factory" 3 "Reserved" ;
VAL_ 2147566592 CfgType 0 "User" 1 "OEM" 2 "Factory" 3 "Reserved" ;
VAL_ 2147566592 AssocType 0 "Invalid" 1 "DCInput" 2 "DCOut" 3 "DCInputOut" 4 "Reserved" 5 "ACInput" 6 "ACOut" 7 "ACInputOut" ;
VAL_ 2147565824 WarnSndEnDis 0 "Off" 1 "On" 2 "Reserved" 3 "No Change" ;
VAL_ 2147565824 TimeFmt 0 "AMPM" 1 "24 Hour" 253 "Reserved" 254 "Out Of Range" 255 "Data Not Available Do Not Change" ;
VAL_ 2147565824 SplashScrnStyl 0 "Still" 1 "Bounce" 2 "MarqueeH" 3 "MarqueeV" 253 "Reserved" 254 "Out Of Range" 255 "Data Not Available Do Not Change" ;
VAL_ 2147565824 SplashOnWakeEnDis 0 "Off" 1 "On" 2 "Reserved" 3 "No Change" ;
VAL_ 2147565824 SndEnDis 0 "Off" 1 "On" 2 "Reserved" 3 "No Change" ;
VAL_ 2147565824 MeasUnit 0 "Imperial" 1 "Standard" 2 "Metric" 253 "Reserved" 254 "Out Of Range" 255 "Data Not Available Do Not Change" ;
VAL_ 2147565824 FaultSndEnDis 0 "Off" 1 "On" 2 "Reserved" 3 "No Change" ;
VAL_ 2147565824 CfgType 0 "User" 1 "OEM" 2 "Factory" 3 "Reserved" ;
VAL_ 2147565824 BtnSndEnDis 0 "Off" 1 "On" 2 "Reserved" 3 "No Change" ;
VAL_ 2147565824 AccMode 0 "Simple" 1 "Savvy" 2 "Dealer" 3 "OEM" 4 "Mfg" 253 "Reserved" 254 "Out Of Range" 255 "Data Not Available Do Not Change" ;
VAL_ 2147612686 SwModId 0 "XanBus" 1 "OperatingSystem" 2 "Application" 3 "Loader" 4 "Reserved2" 5 "Other1" 6 "Other2" 253 "Reserved" 254 "Out Of Range" 255 "Data Not Available Do Not Change" ;
VAL_ 2147610639 WarnsChangedFlag 0 "Off" 1 "On" 2 "Error" 3 "Unknown" ;
VAL_ 2147610639 WarnFlag 0 "Off" 1 "On" 2 "Error" 3 "Unknown" ;
VAL_ 2147610639 PerTxEnDis 0 "Off" 1 "On" 2 "Error" 3 "Unknown" ;
VAL_ 2147610639 NewWarnsFlag 0 "Off" 1 "On" 2 "Error" 3 "Unknown" ;
VAL_ 2147610639 NewFaultsFlag 0 "Off" 1 "On" 2 "Error" 3 "Unknown" ;
VAL_ 2147610639 NetworkState 0 "Error Active" 1 "Error Passive" 2 "Bus Off" 3 "Unknown" ;
VAL_ 2147610639 LastMode 0 "Hibernate" 1 "Power Save" 2 "Safe" 3 "Operating" 4 "Diagnostic" 5 "Remote Power Off" 252 "Last Mode" 253 "Reserved" 254 "Out Of Range" 255 "Data Not Available Do Not Change" ;
VAL_ 2147610639 FaultsChangedFlag 0 "Off" 1 "On" 2 "Error" 3 "Unknown" ;
VAL_ 2147610639 FaultFlag 0 "Off" 1 "On" 2 "Error" 3 "Unknown" ;
VAL_ 2147610639 DesiredMode 0 "Hibernate" 1 "Power Save" 2 "Safe" 3 "Operating" 4 "Diagnostic" 5 "Remote Power Off" 252 "Last Mode" 253 "Reserved" 254 "Out Of Range" 255 "Data Not Available Do Not Change" ;
VAL_ 2147610639 CurrentMode 0 "Hibernate" 1 "Power Save" 2 "Safe" 3 "Operating" 4 "Diagnostic" 5 "Remote Power Off" 252 "Last Mode" 253 "Reserved" 254 "Out Of Range" 255 "Data Not Available Do Not Change" ;
VAL_ 2147605760 CharType 0 "Unicode" 1 "Ascii" ;
VAL_ 2147605760 CfgType 0 "User" 1 "OEM" 2 "Factory" 3 "Reserved" ;
VAL_ 2147612873 StateId 0 "Hibernate" 1 "Safe" 2 "Power Save" 3 "Operating" 4 "Diagnostic" 265 "Quiet Time" 266 "Auto On" 267 "Auto Off" 268 "Manual On" 269 "Manual Off" 270 "Generator Shutdown" 271 "External Shutdown" 272 "AGS Fault" 273 "Suspend" 274 "Not Operating" 512 "Monitoring" 768 "Not Charging" 769 "Bulk" 770 "Absorption" 771 "Overcharge" 772 "Equalize" 773 "Float" 774 "No Float" 775 "Constant VI" 776 "Charger Disabled" 777 "Qualifying AC" 778 "Qualifying APS" 779 "Engaging Charger" 780 "Charge Fault" 781 "Charger Suspend" 782 "AC Good" 783 "APS Good" 784 "AC Fault" 785 "Charge" 786 "Absorption Exit Pending" 787 "Ground Fault" 800 "Inactive" 801 "Input1Active" 802 "Input2Active" 803 "Input1Delay" 804 "Input2Delay" 1024 "Inv" 1025 "AC Passthru" 1026 "APS Only" 1027 "Load Sense Active" 1028 "Inverter Disabled" 1029 "Load Sense Ready" 1030 "Engaging Inverter" 1031 "Invert Fault" 1032 "Inverter Standby" 1033 "Grid Tied" 1034 "Grid Support" 1035 "Gen Support" 1036 "Sell To Grid" 1037 "Load Shaving" 1280 "Screen Saver" 1281 "Active" 1408 "Gateway Translating" 1409 "Gateway Disabled" 1410 "Grid Frequency Stabilization" ;
VAL_ 2147612873 EvtId 436 "SPS Auto Off Array V Low" 437 "SPS Auto On Array V Low" 438 "SPS Auto Off Ground Flt" 439 "SPS Auto On Ground Flt" 440 "SPS Auto Off External Shutdown Flt" 0 "None" 10 "Control Command Hibernate" 11 "Control Command Safe" 12 "Control Command Power Save" 13 "Control Command Operating" 14 "Control Command Diagnostic" 15 "Control Command Last Mode" 20 "Reset Command Reboot" 21 "Reset Command Download" 22 "Reset Command Oem" 23 "Reset Command Factory" 24 "Reset Command Reboot Clear Nv" 25 "Powered Up" 30 "Clear Command Active Faults" 31 "Clear Command Fault Log" 32 "Clear Command Active Warns" 33 "Clear Command Warn Log" 34 "Clear Command State Event Log" 35 "Clear Command Comm Stats" 36 "Clear Command Stats" 37 "Clear Command All" 40 "Date Time Configured" 50 "Warn Cleared" 51 "Fault Cleared" 52 "Fault Set" 60 "User Cfg Changed" 61 "Oem Cfg Changed" 70 "Triggered Fault" 250 "Shutdown Threshold" 251 "Shutdown Hysteresis" 252 "Warning Threshold" 253 "Warning Hysteresis" 254 "Transfer Threshold" 255 "Fan 0 Threshold" 256 "Fan 10 Threshold" 257 "Fan 20 Threshold" 258 "Fan 30 Threshold" 259 "Fan 40 Threshold" 260 "Fan 50 Threshold" 261 "Fan 60 Threshold" 262 "Fan 70 Threshold" 263 "Fan 80 Threshold" 264 "Fan 90 Threshold" 265 "Fan 100 Threshold" 266 "Relay Open Threshold" 267 "Relay Close Threshold" 268 "Charger Derating Ac In V" 269 "Charger Derating Ac In I" 270 "Charger Derating Ext Temp" 271 "Charger Derating Int Temp" 272 "Charger Derating Ripple V" 273 "Lost Ac Threshold" 274 "Lost Ac Hysteresis" 275 "Imm Shutdown Threshold" 276 "Imm Shutdown Hysteresis" 277 "Charger Shutdown Threshold" 278 "Charger Shutdown Hysteresis" 279 "Charger Warning Threshold" 280 "Charger Warning Hysteresis" 281 "Inverter Shutdown Threshold" 282 "Inverter Shutdown Hysteresis" 283 "Inverter Warning Threshold" 284 "Inverter Warning Hysteresis" 285 "Charger Derating Temp Start Point" 286 "Charger Derating Temp End Point" 287 "Charger Recharge Threshold" 300 "Ags Exercise Start" 301 "Ags Exercise Stop" 302 "Ags Quiet Time Begin" 303 "Ags Quiet Time End" 304 "Ags Battery Soc Start" 305 "Ags Battery Soc Stop" 306 "Ags Dc V Start" 307 "Ags Dc V Stop" 308 "Ags Ac I Start" 309 "Ags Ac I Stop" 310 "Ags Contact Start" 311 "Ags Contact Stop" 312 "Ags Float Stop" 313 "Ags Absorp Stop" 314 "Ags Manual On" 315 "Ags Manual Off" 316 "Ags Auto" 317 "Ags External On" 318 "Ags External Off" 319 "Gen External On" 320 "Gen External Off" 321 "Ags External Shutdown" 322 "Ags Auto Off" 323 "Ags Dc I Start" 324 "Ags Dc I Stop" 325 "Ags Ac Power Start" 326 "Ags Ac Power Stop" 400 "Sps Manual Off" 401 "Sps Manual On" 410 "Sps Auto Off" 411 "Sps Auto On" 420 "Sps Auto Off Batt V Low" 421 "Sps Auto On Batt V Low" 422 "Sps Auto Off Batt V High" 423 "Sps Auto On Batt V High" 424 "Sps Auto Off Array V High" 425 "Sps Auto On Array V High" 426 "Sps Auto Off Batt Temp Low" 427 "Sps Auto On Batt Temp Low" 428 "Sps Auto Off Batt Temp High" 429 "Sps Auto On Batt Temp High" 430 "Sps Auto Off Heat Sink Temp High" 431 "Sps Auto On Heat Sink Temp High" 432 "Sps Auto Off Fault" 433 "Sps Auto On Fault" 434 "Aps Check Timeout" 435 "Aps Qualify Timeout" 512 "Resume From Safe" 513 "AC Fault Set" 514 "Invert Fault Set" 515 "Charge Fault Set" 516 "Charger Enable" 517 "Charger Disable" 518 "Inverter Enable" 519 "Inverter Disable" 520 "Charge Suspend On" 521 "Charge Suspend Off" 522 "AC Good" 523 "AC Bad" 524 "Load Sense Enable" 525 "Load Sense Active" 526 "Invert Active" 527 "Bulk Exit" 528 "Absorption Exit" 529 "Float Exit" 530 "Float 3-Stage Set" 531 "Float 2-Stage Set" 532 "Equalize Enable" 533 "Equalize Disable" 534 "Equalize Exit" 535 "Load Sense Disable" 536 "Sell To Grid Enabled" 537 "Sell To Grid Disabled" 538 "Grid Support Enable" 539 "Grid Support Disable" 540 "Gen Support Enable" 541 "Gen Support Disable" 542 "Peak Load Shaving Enable" 543 "Peak Load Shaving Disable" 544 "Peak Load Shaving Tod Start" 545 "Peak Load Shaving Tod Stop" 546 "Unit Off" 547 "System Absorption Exit" 548 "System Inverter Enable" 549 "System AC Good" 550 "Anti Islanding Condition" 551 "Hibernate Timeout" 552 "External Sync Error" 553 "External Suspend Request" 554 "Engaging Charger" 555 "Engaging Gen Support" 556 "Grid Tie Engage Timeout" 557 "Gen Support Engage Timeout" 558 "Charge Engage Timeout" 559 "Inverter Engage Timeout" 560 "Charge Exit Timeout" 561 "Grid Support Entry Amps" 562 "Grid Support Exit Amps" 563 "Gen Support Entry Amps" 564 "Gen Support Exit Amps" 565 "Grid Support Entry Vdc" 566 "Grid Support Exit Vdc" 567 "Low Batt Cut Off Entry Vdc" 568 "Low Batt Recharge Vdc" 569 "Low Batt Cut Off Exit Vdc" 570 "Invert To Bypass Timeout" 571 "Force Charge" 572 "System Engage Bulk Charge" 441 "SPS Auto On External Shutdown Flt" 442 "SPS Auto Off Input Over Volt Flt" 443 "SPS Auto On Input Over Volt Flt" 444 "SPS Auto Off Input Over Volt Err" 445 "SPS Auto On Input Over Volt Err" 446 "SPS Auto Off Input Over Volt Wrn" 447 "SPS Auto On Input Over Volt Wrn" 448 "SPS Auto Off Output Over Volt Err" 449 "SPS Auto On Output Over Volt Err" 450 "SPS Auto Off Output Over Volt Wrn" 451 "SPS Auto On Output Over Volt Wrn" 452 "SPS Auto Off Output Under Volt Err" 453 "SPS Auto On Output Under Volt Err" 454 "SPS Auto Off Output Under Volt Wrn" 455 "SPS Auto On Output Under Volt Wrn" 456 "SPS Auto Off Output Over Curr Err" 457 "SPS Auto On Output Over Curr Err" 458 "SPS Auto Off Batt Over Temp Err" 459 "SPS Auto On Batt Over Temp Err" 460 "SPS Auto Off Batt Over Temp Wrn" 461 "SPS Auto On Batt Over Temp Wrn" 462 "SPS Auto Off Batt Under Temp Wrn" 463 "SPS Auto On Batt Under Temp Wrn" 464 "SPS Auto Off Heatsink Over Temp Err" 465 "SPS Auto On Heatsink Over Temp Err" 466 "SPS Auto Off Heatsink Over Temp Wrn" 467 "SPS Auto On Heatsink Over Temp Wrn" 468 "SPS Auto Off Ambient Over Temp Err" 469 "SPS Auto On Ambient Over Temp Err" 470 "SPS Auto Off Ambient Over Temp Wrn" 471 "SPS Auto On Ambient Over Temp Wrn" 472 "SPS Auto Off Capacitor Over Temp Err" 473 "SPS Auto On Capacitor Over Temp Err" 474 "SPS Auto Off Fan Flt" 475 "SPS Auto On Fan Flt" 476 "SPS Auto Off Fan Err" 477 "SPS Auto On Fan Err" 478 "SPS Auto Off Input Over Curr Err" 479 "SPS Auto On Input Over Curr Err" 480 "SPS Auto Off Output Over Curr Flt" 481 "SPS Auto On Output Over Curr Flt" 482 "SPS Auto Off Network PS Flt" 483 "SPS Auto On Network PS Flt" 484 "SPS Auto Off Setup Flt" 485 "SPS Auto On Setup Flt" 38 "Clear Command User Stats" 573 "AC Good Pending" 574 "Grid Safe" 585 "PLS Time In Float Ready" 575 "Power Conversion Fault" 576 "Low Battery Support Exit" 577 "Grid Support Exit" 578 "GFS Enable" 579 "GFS Disable" 580 "Force Sell" 486 "SPS Auto On Bulk Exit" 487 "SPS Auto Off Bulk Exit" 488 "SPS Auto On Absorption Exit" 489 "SPS Auto Off Absorption Exit" 490 "SPS Auto On State Of Charge Low" 491 "SPS Auto Off State Of Charge Low" 492 "SPS Auto On Time Of Day" 493 "SPS Auto Off Time Of Day" 581 "Sell Time Of Day Start" 582 "Sell Time Of Day Stop" 583 "Aux Port Time Of Day Start" 584 "Aux Port Time Of Day Stop" ;
VAL_ 2147612687 StateId 0 "Hibernate" 1 "Safe" 2 "Power Save" 3 "Operating" 4 "Diagnostic" 265 "Quiet Time" 266 "Auto On" 267 "Auto Off" 268 "Manual On" 269 "Manual Off" 270 "Generator Shutdown" 271 "External Shutdown" 272 "AGS Fault" 273 "Suspend" 274 "Not Operating" 512 "Monitoring" 768 "Not Charging" 769 "Bulk" 770 "Absorption" 771 "Overcharge" 772 "Equalize" 773 "Float" 774 "No Float" 775 "Constant VI" 776 "Charger Disabled" 777 "Qualifying AC" 778 "Qualifying APS" 779 "Engaging Charger" 780 "Charge Fault" 781 "Charger Suspend" 782 "AC Good" 783 "APS Good" 784 "AC Fault" 785 "Charge" 786 "Absorption Exit Pending" 787 "Ground Fault" 800 "Inactive" 801 "Input1Active" 802 "Input2Active" 803 "Input1Delay" 804 "Input2Delay" 1024 "Inv" 1025 "AC Passthru" 1026 "APS Only" 1027 "Load Sense Active" 1028 "Inverter Disabled" 1029 "Load Sense Ready" 1030 "Engaging Inverter" 1031 "Invert Fault" 1032 "Inverter Standby" 1033 "Grid Tied" 1034 "Grid Support" 1035 "Gen Support" 1036 "Sell To Grid" 1037 "Load Shaving" 1280 "Screen Saver" 1281 "Active" 1408 "Gateway Translating" 1409 "Gateway Disabled" 1410 "Grid Frequency Stabilization" ;
VAL_ 2147612687 EvtId 436 "SPS Auto Off Array V Low" 437 "SPS Auto On Array V Low" 438 "SPS Auto Off Ground Flt" 439 "SPS Auto On Ground Flt" 440 "SPS Auto Off External Shutdown Flt" 0 "None" 10 "Control Command Hibernate" 11 "Control Command Safe" 12 "Control Command Power Save" 13 "Control Command Operating" 14 "Control Command Diagnostic" 15 "Control Command Last Mode" 20 "Reset Command Reboot" 21 "Reset Command Download" 22 "Reset Command Oem" 23 "Reset Command Factory" 24 "Reset Command Reboot Clear Nv" 25 "Powered Up" 30 "Clear Command Active Faults" 31 "Clear Command Fault Log" 32 "Clear Command Active Warns" 33 "Clear Command Warn Log" 34 "Clear Command State Event Log" 35 "Clear Command Comm Stats" 36 "Clear Command Stats" 37 "Clear Command All" 40 "Date Time Configured" 50 "Warn Cleared" 51 "Fault Cleared" 52 "Fault Set" 60 "User Cfg Changed" 61 "Oem Cfg Changed" 70 "Triggered Fault" 250 "Shutdown Threshold" 251 "Shutdown Hysteresis" 252 "Warning Threshold" 253 "Warning Hysteresis" 254 "Transfer Threshold" 255 "Fan 0 Threshold" 256 "Fan 10 Threshold" 257 "Fan 20 Threshold" 258 "Fan 30 Threshold" 259 "Fan 40 Threshold" 260 "Fan 50 Threshold" 261 "Fan 60 Threshold" 262 "Fan 70 Threshold" 263 "Fan 80 Threshold" 264 "Fan 90 Threshold" 265 "Fan 100 Threshold" 266 "Relay Open Threshold" 267 "Relay Close Threshold" 268 "Charger Derating Ac In V" 269 "Charger Derating Ac In I" 270 "Charger Derating Ext Temp" 271 "Charger Derating Int Temp" 272 "Charger Derating Ripple V" 273 "Lost Ac Threshold" 274 "Lost Ac Hysteresis" 275 "Imm Shutdown Threshold" 276 "Imm Shutdown Hysteresis" 277 "Charger Shutdown Threshold" 278 "Charger Shutdown Hysteresis" 279 "Charger Warning Threshold" 280 "Charger Warning Hysteresis" 281 "Inverter Shutdown Threshold" 282 "Inverter Shutdown Hysteresis" 283 "Inverter Warning Threshold" 284 "Inverter Warning Hysteresis" 285 "Charger Derating Temp Start Point" 286 "Charger Derating Temp End Point" 287 "Charger Recharge Threshold" 300 "Ags Exercise Start" 301 "Ags Exercise Stop" 302 "Ags Quiet Time Begin" 303 "Ags Quiet Time End" 304 "Ags Battery Soc Start" 305 "Ags Battery Soc Stop" 306 "Ags Dc V Start" 307 "Ags Dc V Stop" 308 "Ags Ac I Start" 309 "Ags Ac I Stop" 310 "Ags Contact Start" 311 "Ags Contact Stop" 312 "Ags Float Stop" 313 "Ags Absorp Stop" 314 "Ags Manual On" 315 "Ags Manual Off" 316 "Ags Auto" 317 "Ags External On" 318 "Ags External Off" 319 "Gen External On" 320 "Gen External Off" 321 "Ags External Shutdown" 322 "Ags Auto Off" 323 "Ags Dc I Start" 324 "Ags Dc I Stop" 325 "Ags Ac Power Start" 326 "Ags Ac Power Stop" 400 "Sps Manual Off" 401 "Sps Manual On" 410 "Sps Auto Off" 411 "Sps Auto On" 420 "Sps Auto Off Batt V Low" 421 "Sps Auto On Batt V Low" 422 "Sps Auto Off Batt V High" 423 "Sps Auto On Batt V High" 424 "Sps Auto Off Array V High" 425 "Sps Auto On Array V High" 426 "Sps Auto Off Batt Temp Low" 427 "Sps Auto On Batt Temp Low" 428 "Sps Auto Off Batt Temp High" 429 "Sps Auto On Batt Temp High" 430 "Sps Auto Off Heat Sink Temp High" 431 "Sps Auto On Heat Sink Temp High" 432 "Sps Auto Off Fault" 433 "Sps Auto On Fault" 434 "Aps Check Timeout" 435 "Aps Qualify Timeout" 512 "Resume From Safe" 513 "AC Fault Set" 514 "Invert Fault Set" 515 "Charge Fault Set" 516 "Charger Enable" 517 "Charger Disable" 518 "Inverter Enable" 519 "Inverter Disable" 520 "Charge Suspend On" 521 "Charge Suspend Off" 522 "AC Good" 523 "AC Bad" 524 "Load Sense Enable" 525 "Load Sense Active" 526 "Invert Active" 527 "Bulk Exit" 528 "Absorption Exit" 529 "Float Exit" 530 "Float 3-Stage Set" 531 "Float 2-Stage Set" 532 "Equalize Enable" 533 "Equalize Disable" 534 "Equalize Exit" 535 "Load Sense Disable" 536 "Sell To Grid Enabled" 537 "Sell To Grid Disabled" 538 "Grid Support Enable" 539 "Grid Support Disable" 540 "Gen Support Enable" 541 "Gen Support Disable" 542 "Peak Load Shaving Enable" 543 "Peak Load Shaving Disable" 544 "Peak Load Shaving Tod Start" 545 "Peak Load Shaving Tod Stop" 546 "Unit Off" 547 "System Absorption Exit" 548 "System Inverter Enable" 549 "System AC Good" 550 "Anti Islanding Condition" 551 "Hibernate Timeout" 552 "External Sync Error" 553 "External Suspend Request" 554 "Engaging Charger" 555 "Engaging Gen Support" 556 "Grid Tie Engage Timeout" 557 "Gen Support Engage Timeout" 558 "Charge Engage Timeout" 559 "Inverter Engage Timeout" 560 "Charge Exit Timeout" 561 "Grid Support Entry Amps" 562 "Grid Support Exit Amps" 563 "Gen Support Entry Amps" 564 "Gen Support Exit Amps" 565 "Grid Support Entry Vdc" 566 "Grid Support Exit Vdc" 567 "Low Batt Cut Off Entry Vdc" 568 "Low Batt Recharge Vdc" 569 "Low Batt Cut Off Exit Vdc" 570 "Invert To Bypass Timeout" 571 "Force Charge" 572 "System Engage Bulk Charge" 441 "SPS Auto On External Shutdown Flt" 442 "SPS Auto Off Input Over Volt Flt" 443 "SPS Auto On Input Over Volt Flt" 444 "SPS Auto Off Input Over Volt Err" 445 "SPS Auto On Input Over Volt Err" 446 "SPS Auto Off Input Over Volt Wrn" 447 "SPS Auto On Input Over Volt Wrn" 448 "SPS Auto Off Output Over Volt Err" 449 "SPS Auto On Output Over Volt Err" 450 "SPS Auto Off Output Over Volt Wrn" 451 "SPS Auto On Output Over Volt Wrn" 452 "SPS Auto Off Output Under Volt Err" 453 "SPS Auto On Output Under Volt Err" 454 "SPS Auto Off Output Under Volt Wrn" 455 "SPS Auto On Output Under Volt Wrn" 456 "SPS Auto Off Output Over Curr Err" 457 "SPS Auto On Output Over Curr Err" 458 "SPS Auto Off Batt Over Temp Err" 459 "SPS Auto On Batt Over Temp Err" 460 "SPS Auto Off Batt Over Temp Wrn" 461 "SPS Auto On Batt Over Temp Wrn" 462 "SPS Auto Off Batt Under Temp Wrn" 463 "SPS Auto On Batt Under Temp Wrn" 464 "SPS Auto Off Heatsink Over Temp Err" 465 "SPS Auto On Heatsink Over Temp Err" 466 "SPS Auto Off Heatsink Over Temp Wrn" 467 "SPS Auto On Heatsink Over Temp Wrn" 468 "SPS Auto Off Ambient Over Temp Err" 469 "SPS Auto On Ambient Over Temp Err" 470 "SPS Auto Off Ambient Over Temp Wrn" 471 "SPS Auto On Ambient Over Temp Wrn" 472 "SPS Auto Off Capacitor Over Temp Err" 473 "SPS Auto On Capacitor Over Temp Err" 474 "SPS Auto Off Fan Flt" 475 "SPS Auto On Fan Flt" 476 "SPS Auto Off Fan Err" 477 "SPS Auto On Fan Err" 478 "SPS Auto Off Input Over Curr Err" 479 "SPS Auto On Input Over Curr Err" 480 "SPS Auto Off Output Over Curr Flt" 481 "SPS Auto On Output Over Curr Flt" 482 "SPS Auto Off Network PS Flt" 483 "SPS Auto On Network PS Flt" 484 "SPS Auto Off Setup Flt" 485 "SPS Auto On Setup Flt" 38 "Clear Command User Stats" 573 "AC Good Pending" 574 "Grid Safe" 585 "PLS Time In Float Ready" 575 "Power Conversion Fault" 576 "Low Battery Support Exit" 577 "Grid Support Exit" 578 "GFS Enable" 579 "GFS Disable" 580 "Force Sell" 486 "SPS Auto On Bulk Exit" 487 "SPS Auto Off Bulk Exit" 488 "SPS Auto On Absorption Exit" 489 "SPS Auto Off Absorption Exit" 490 "SPS Auto On State Of Charge Low" 491 "SPS Auto Off State Of Charge Low" 492 "SPS Auto On Time Of Day" 493 "SPS Auto Off Time Of Day" 581 "Sell Time Of Day Start" 582 "Sell Time Of Day Stop" 583 "Aux Port Time Of Day Start" 584 "Aux Port Time Of Day Stop" ;
VAL_ 2147610822 OpState 266 "Auto On" 267 "Auto Off" 268 "Manual On" 269 "Manual Off" ;
VAL_ 2147610822 OnReason 0 "Not On" 1 "Manual On" 2 "Battery Voltage Low" 3 "Battery Voltage High" 4 "Array Voltage High" 5 "Battery Temp Low" 6 "Battery Temp High" 7 "Heat Sink Temp High" 8 "Fault" 9 "State Of Charge" 10 "Time Of Day" ;
VAL_ 2147610822 OffReason 0 "Not Off" 1 "Manual Off" 2 "No Active Trigger" 3 "Trigger Override" 4 "Fault" 5 "Bulk Exit" 6 "Absorption Exit" ;
VAL_ 2147599616 DesiredState 0 "Manual Off" 1 "Manual On" 2 "Automatic" ;
VAL_ 2147600128 TrigEnDis 0 "Off" 1 "On" 2 "Error" 3 "Unknown" ;
VAL_ 2147600128 EvtId 436 "SPS Auto Off Array V Low" 437 "SPS Auto On Array V Low" 438 "SPS Auto Off Ground Flt" 439 "SPS Auto On Ground Flt" 440 "SPS Auto Off External Shutdown Flt" 0 "None" 10 "Control Command Hibernate" 11 "Control Command Safe" 12 "Control Command Power Save" 13 "Control Command Operating" 14 "Control Command Diagnostic" 15 "Control Command Last Mode" 20 "Reset Command Reboot" 21 "Reset Command Download" 22 "Reset Command Oem" 23 "Reset Command Factory" 24 "Reset Command Reboot Clear Nv" 25 "Powered Up" 30 "Clear Command Active Faults" 31 "Clear Command Fault Log" 32 "Clear Command Active Warns" 33 "Clear Command Warn Log" 34 "Clear Command State Event Log" 35 "Clear Command Comm Stats" 36 "Clear Command Stats" 37 "Clear Command All" 40 "Date Time Configured" 50 "Warn Cleared" 51 "Fault Cleared" 52 "Fault Set" 60 "User Cfg Changed" 61 "Oem Cfg Changed" 70 "Triggered Fault" 250 "Shutdown Threshold" 251 "Shutdown Hysteresis" 252 "Warning Threshold" 253 "Warning Hysteresis" 254 "Transfer Threshold" 255 "Fan 0 Threshold" 256 "Fan 10 Threshold" 257 "Fan 20 Threshold" 258 "Fan 30 Threshold" 259 "Fan 40 Threshold" 260 "Fan 50 Threshold" 261 "Fan 60 Threshold" 262 "Fan 70 Threshold" 263 "Fan 80 Threshold" 264 "Fan 90 Threshold" 265 "Fan 100 Threshold" 266 "Relay Open Threshold" 267 "Relay Close Threshold" 268 "Charger Derating Ac In V" 269 "Charger Derating Ac In I" 270 "Charger Derating Ext Temp" 271 "Charger Derating Int Temp" 272 "Charger Derating Ripple V" 273 "Lost Ac Threshold" 274 "Lost Ac Hysteresis" 275 "Imm Shutdown Threshold" 276 "Imm Shutdown Hysteresis" 277 "Charger Shutdown Threshold" 278 "Charger Shutdown Hysteresis" 279 "Charger Warning Threshold" 280 "Charger Warning Hysteresis" 281 "Inverter Shutdown Threshold" 282 "Inverter Shutdown Hysteresis" 283 "Inverter Warning Threshold" 284 "Inverter Warning Hysteresis" 285 "Charger Derating Temp Start Point" 286 "Charger Derating Temp End Point" 287 "Charger Recharge Threshold" 300 "Ags Exercise Start" 301 "Ags Exercise Stop" 302 "Ags Quiet Time Begin" 303 "Ags Quiet Time End" 304 "Ags Battery Soc Start" 305 "Ags Battery Soc Stop" 306 "Ags Dc V Start" 307 "Ags Dc V Stop" 308 "Ags Ac I Start" 309 "Ags Ac I Stop" 310 "Ags Contact Start" 311 "Ags Contact Stop" 312 "Ags Float Stop" 313 "Ags Absorp Stop" 314 "Ags Manual On" 315 "Ags Manual Off" 316 "Ags Auto" 317 "Ags External On" 318 "Ags External Off" 319 "Gen External On" 320 "Gen External Off" 321 "Ags External Shutdown" 322 "Ags Auto Off" 323 "Ags Dc I Start" 324 "Ags Dc I Stop" 325 "Ags Ac Power Start" 326 "Ags Ac Power Stop" 400 "Sps Manual Off" 401 "Sps Manual On" 410 "Sps Auto Off" 411 "Sps Auto On" 420 "Sps Auto Off Batt V Low" 421 "Sps Auto On Batt V Low" 422 "Sps Auto Off Batt V High" 423 "Sps Auto On Batt V High" 424 "Sps Auto Off Array V High" 425 "Sps Auto On Array V High" 426 "Sps Auto Off Batt Temp Low" 427 "Sps Auto On Batt Temp Low" 428 "Sps Auto Off Batt Temp High" 429 "Sps Auto On Batt Temp High" 430 "Sps Auto Off Heat Sink Temp High" 431 "Sps Auto On Heat Sink Temp High" 432 "Sps Auto Off Fault" 433 "Sps Auto On Fault" 434 "Aps Check Timeout" 435 "Aps Qualify Timeout" 512 "Resume From Safe" 513 "AC Fault Set" 514 "Invert Fault Set" 515 "Charge Fault Set" 516 "Charger Enable" 517 "Charger Disable" 518 "Inverter Enable" 519 "Inverter Disable" 520 "Charge Suspend On" 521 "Charge Suspend Off" 522 "AC Good" 523 "AC Bad" 524 "Load Sense Enable" 525 "Load Sense Active" 526 "Invert Active" 527 "Bulk Exit" 528 "Absorption Exit" 529 "Float Exit" 530 "Float 3-Stage Set" 531 "Float 2-Stage Set" 532 "Equalize Enable" 533 "Equalize Disable" 534 "Equalize Exit" 535 "Load Sense Disable" 536 "Sell To Grid Enabled" 537 "Sell To Grid Disabled" 538 "Grid Support Enable" 539 "Grid Support Disable" 540 "Gen Support Enable" 541 "Gen Support Disable" 542 "Peak Load Shaving Enable" 543 "Peak Load Shaving Disable" 544 "Peak Load Shaving Tod Start" 545 "Peak Load Shaving Tod Stop" 546 "Unit Off" 547 "System Absorption Exit" 548 "System Inverter Enable" 549 "System AC Good" 550 "Anti Islanding Condition" 551 "Hibernate Timeout" 552 "External Sync Error" 553 "External Suspend Request" 554 "Engaging Charger" 555 "Engaging Gen Support" 556 "Grid Tie Engage Timeout" 557 "Gen Support Engage Timeout" 558 "Charge Engage Timeout" 559 "Inverter Engage Timeout" 560 "Charge Exit Timeout" 561 "Grid Support Entry Amps" 562 "Grid Support Exit Amps" 563 "Gen Support Entry Amps" 564 "Gen Support Exit Amps" 565 "Grid Support Entry Vdc" 566 "Grid Support Exit Vdc" 567 "Low Batt Cut Off Entry Vdc" 568 "Low Batt Recharge Vdc" 569 "Low Batt Cut Off Exit Vdc" 570 "Invert To Bypass Timeout" 571 "Force Charge" 572 "System Engage Bulk Charge" 441 "SPS Auto On External Shutdown Flt" 442 "SPS Auto Off Input Over Volt Flt" 443 "SPS Auto On Input Over Volt Flt" 444 "SPS Auto Off Input Over Volt Err" 445 "SPS Auto On Input Over Volt Err" 446 "SPS Auto Off Input Over Volt Wrn" 447 "SPS Auto On Input Over Volt Wrn" 448 "SPS Auto Off Output Over Volt Err" 449 "SPS Auto On Output Over Volt Err" 450 "SPS Auto Off Output Over Volt Wrn" 451 "SPS Auto On Output Over Volt Wrn" 452 "SPS Auto Off Output Under Volt Err" 453 "SPS Auto On Output Under Volt Err" 454 "SPS Auto Off Output Under Volt Wrn" 455 "SPS Auto On Output Under Volt Wrn" 456 "SPS Auto Off Output Over Curr Err" 457 "SPS Auto On Output Over Curr Err" 458 "SPS Auto Off Batt Over Temp Err" 459 "SPS Auto On Batt Over Temp Err" 460 "SPS Auto Off Batt Over Temp Wrn" 461 "SPS Auto On Batt Over Temp Wrn" 462 "SPS Auto Off Batt Under Temp Wrn" 463 "SPS Auto On Batt Under Temp Wrn" 464 "SPS Auto Off Heatsink Over Temp Err" 465 "SPS Auto On Heatsink Over Temp Err" 466 "SPS Auto Off Heatsink Over Temp Wrn" 467 "SPS Auto On Heatsink Over Temp Wrn" 468 "SPS Auto Off Ambient Over Temp Err" 469 "SPS Auto On Ambient Over Temp Err" 470 "SPS Auto Off Ambient Over Temp Wrn" 471 "SPS Auto On Ambient Over Temp Wrn" 472 "SPS Auto Off Capacitor Over Temp Err" 473 "SPS Auto On Capacitor Over Temp Err" 474 "SPS Auto Off Fan Flt" 475 "SPS Auto On Fan Flt" 476 "SPS Auto Off Fan Err" 477 "SPS Auto On Fan Err" 478 "SPS Auto Off Input Over Curr Err" 479 "SPS Auto On Input Over Curr Err" 480 "SPS Auto Off Output Over Curr Flt" 481 "SPS Auto On Output Over Curr Flt" 482 "SPS Auto Off Network PS Flt" 483 "SPS Auto On Network PS Flt" 484 "SPS Auto Off Setup Flt" 485 "SPS Auto On Setup Flt" 38 "Clear Command User Stats" 573 "AC Good Pending" 574 "Grid Safe" 585 "PLS Time In Float Ready" 575 "Power Conversion Fault" 576 "Low Battery Support Exit" 577 "Grid Support Exit" 578 "GFS Enable" 579 "GFS Disable" 580 "Force Sell" 486 "SPS Auto On Bulk Exit" 487 "SPS Auto Off Bulk Exit" 488 "SPS Auto On Absorption Exit" 489 "SPS Auto Off Absorption Exit" 490 "SPS Auto On State Of Charge Low" 491 "SPS Auto Off State Of Charge Low" 492 "SPS Auto On Time Of Day" 493 "SPS Auto Off Time Of Day" 581 "Sell Time Of Day Start" 582 "Sell Time Of Day Stop" 583 "Aux Port Time Of Day Start" 584 "Aux Port Time Of Day Stop" ;
VAL_ 2147600128 CfgType 0 "User" 1 "OEM" 2 "Factory" 3 "Reserved" ;
VAL_ 2147574272 DcSrcId 0 "Invalid" 1 "None" 2 "Anonymous" 3 "HouseBatBank1" 4 "HouseBatBank2" 5 "HouseBatBank3" 6 "HouseBatBank4" 7 "HouseBatBank5" 8 "HouseBatBank6" 9 "StartBatBank1" 10 "StartBatBank2" 11 "StartBatBank3" 12 "StartBatBank4" 13 "StartBatBank5" 14 "StartBatBank6" 21 "SolarArray1" 22 "SolarArray2" 23 "SolarArray3" 24 "SolarArray4" 25 "SolarArray5" 26 "SolarArray6" 27 "SolarArray7" 28 "SolarArray8" 29 "SolarArray9" 30 "SolarArray10" 31 "SolarArray11" 32 "SolarArray12" 33 "SolarArray13" 34 "SolarArray14" 35 "SolarArray15" 36 "SolarArray16" 252 "All" 253 "Reserved" 254 "Out of Range" 255 "Data Not Available Do Not Change" ;
VAL_ 2147574272 CfgType 0 "User" 1 "OEM" 2 "Factory" 3 "Reserved" ;
VAL_ 2147599872 CfgType 0 "User" 1 "OEM" 2 "Factory" 3 "Reserved" ;
VAL_ 2147599872 ActiveLevel 2 "Data Not Supported" 0 "Active Low" 1 "Active High" ;
VAL_ 2147562240 CfgType 0 "User" 1 "OEM" 2 "Factory" 3 "Reserved" ;
VAL_ 2147575040 StopBits 1 "One" 2 "Two" ;
VAL_ 2147575040 Parity 0 "None" 1 "Odd" 2 "Even" 3 "Reserved" ;
VAL_ 2147575040 CfgType 0 "User" 1 "OEM" 2 "Factory" 3 "Reserved" ;
VAL_ 2147575040 ByteOrder 0 "LSB" 1 "MSB" ;
VAL_ 2147575040 BaudRate 0 "9600" 1 "19200" 2 "38400" 3 "57600" 4 "115200" ;
VAL_ 2147558400 Cmd 0 "Reboot" 1 "RebootDLMode" 2 "Factory" 3 "OEM" 4 "Clear Nv And Reboot" 252 "NoChange" 253 "Reserved" 254 "Out Of Range" 255 "Data Not Available Do Not Change" ;
VAL_ 2147610826 LoopId 0 "Invalid" 1 "Loop 1" 2 "Loop 2" 3 "Loop 3" 4 "Loop 4" 5 "Loop 5" 6 "Loop 6" 7 "Loop 7" 8 "Loop 8" 9 "Loop 9" 10 "Loop 10" 253 "Reserved" 254 "Out Of Range" 255 "Data Not Available Do Not Change" ;
VAL_ 2147600640 LoopId 0 "Invalid" 1 "Loop 1" 2 "Loop 2" 3 "Loop 3" 4 "Loop 4" 5 "Loop 5" 6 "Loop 6" 7 "Loop 7" 8 "Loop 8" 9 "Loop 9" 10 "Loop 10" 253 "Reserved" 254 "Out Of Range" 255 "Data Not Available Do Not Change" ;
VAL_ 2147600640 LoopEnDis 0 "Off" 1 "On" 2 "Reserved" 3 "No Change" ;
VAL_ 2147600640 CfgType 0 "User" 1 "OEM" 2 "Factory" 3 "Reserved" ;
VAL_ 2147610112 TXedPgnGroupFunctionCode 0 "TxPGNListMessage" 1 "RxPGNListMessage" ;
VAL_ 2147560704 CfgType 0 "User" 1 "OEM" 2 "Factory" 3 "Reserved" ;
VAL_ 2147553024 RefEvtId 436 "SPS Auto Off Array V Low" 437 "SPS Auto On Array V Low" 438 "SPS Auto Off Ground Flt" 439 "SPS Auto On Ground Flt" 440 "SPS Auto Off External Shutdown Flt" 0 "None" 10 "Control Command Hibernate" 11 "Control Command Safe" 12 "Control Command Power Save" 13 "Control Command Operating" 14 "Control Command Diagnostic" 15 "Control Command Last Mode" 20 "Reset Command Reboot" 21 "Reset Command Download" 22 "Reset Command Oem" 23 "Reset Command Factory" 24 "Reset Command Reboot Clear Nv" 25 "Powered Up" 30 "Clear Command Active Faults" 31 "Clear Command Fault Log" 32 "Clear Command Active Warns" 33 "Clear Command Warn Log" 34 "Clear Command State Event Log" 35 "Clear Command Comm Stats" 36 "Clear Command Stats" 37 "Clear Command All" 40 "Date Time Configured" 50 "Warn Cleared" 51 "Fault Cleared" 52 "Fault Set" 60 "User Cfg Changed" 61 "Oem Cfg Changed" 70 "Triggered Fault" 250 "Shutdown Threshold" 251 "Shutdown Hysteresis" 252 "Warning Threshold" 253 "Warning Hysteresis" 254 "Transfer Threshold" 255 "Fan 0 Threshold" 256 "Fan 10 Threshold" 257 "Fan 20 Threshold" 258 "Fan 30 Threshold" 259 "Fan 40 Threshold" 260 "Fan 50 Threshold" 261 "Fan 60 Threshold" 262 "Fan 70 Threshold" 263 "Fan 80 Threshold" 264 "Fan 90 Threshold" 265 "Fan 100 Threshold" 266 "Relay Open Threshold" 267 "Relay Close Threshold" 268 "Charger Derating Ac In V" 269 "Charger Derating Ac In I" 270 "Charger Derating Ext Temp" 271 "Charger Derating Int Temp" 272 "Charger Derating Ripple V" 273 "Lost Ac Threshold" 274 "Lost Ac Hysteresis" 275 "Imm Shutdown Threshold" 276 "Imm Shutdown Hysteresis" 277 "Charger Shutdown Threshold" 278 "Charger Shutdown Hysteresis" 279 "Charger Warning Threshold" 280 "Charger Warning Hysteresis" 281 "Inverter Shutdown Threshold" 282 "Inverter Shutdown Hysteresis" 283 "Inverter Warning Threshold" 284 "Inverter Warning Hysteresis" 285 "Charger Derating Temp Start Point" 286 "Charger Derating Temp End Point" 287 "Charger Recharge Threshold" 300 "Ags Exercise Start" 301 "Ags Exercise Stop" 302 "Ags Quiet Time Begin" 303 "Ags Quiet Time End" 304 "Ags Battery Soc Start" 305 "Ags Battery Soc Stop" 306 "Ags Dc V Start" 307 "Ags Dc V Stop" 308 "Ags Ac I Start" 309 "Ags Ac I Stop" 310 "Ags Contact Start" 311 "Ags Contact Stop" 312 "Ags Float Stop" 313 "Ags Absorp Stop" 314 "Ags Manual On" 315 "Ags Manual Off" 316 "Ags Auto" 317 "Ags External On" 318 "Ags External Off" 319 "Gen External On" 320 "Gen External Off" 321 "Ags External Shutdown" 322 "Ags Auto Off" 323 "Ags Dc I Start" 324 "Ags Dc I Stop" 325 "Ags Ac Power Start" 326 "Ags Ac Power Stop" 400 "Sps Manual Off" 401 "Sps Manual On" 410 "Sps Auto Off" 411 "Sps Auto On" 420 "Sps Auto Off Batt V Low" 421 "Sps Auto On Batt V Low" 422 "Sps Auto Off Batt V High" 423 "Sps Auto On Batt V High" 424 "Sps Auto Off Array V High" 425 "Sps Auto On Array V High" 426 "Sps Auto Off Batt Temp Low" 427 "Sps Auto On Batt Temp Low" 428 "Sps Auto Off Batt Temp High" 429 "Sps Auto On Batt Temp High" 430 "Sps Auto Off Heat Sink Temp High" 431 "Sps Auto On Heat Sink Temp High" 432 "Sps Auto Off Fault" 433 "Sps Auto On Fault" 434 "Aps Check Timeout" 435 "Aps Qualify Timeout" 512 "Resume From Safe" 513 "AC Fault Set" 514 "Invert Fault Set" 515 "Charge Fault Set" 516 "Charger Enable" 517 "Charger Disable" 518 "Inverter Enable" 519 "Inverter Disable" 520 "Charge Suspend On" 521 "Charge Suspend Off" 522 "AC Good" 523 "AC Bad" 524 "Load Sense Enable" 525 "Load Sense Active" 526 "Invert Active" 527 "Bulk Exit" 528 "Absorption Exit" 529 "Float Exit" 530 "Float 3-Stage Set" 531 "Float 2-Stage Set" 532 "Equalize Enable" 533 "Equalize Disable" 534 "Equalize Exit" 535 "Load Sense Disable" 536 "Sell To Grid Enabled" 537 "Sell To Grid Disabled" 538 "Grid Support Enable" 539 "Grid Support Disable" 540 "Gen Support Enable" 541 "Gen Support Disable" 542 "Peak Load Shaving Enable" 543 "Peak Load Shaving Disable" 544 "Peak Load Shaving Tod Start" 545 "Peak Load Shaving Tod Stop" 546 "Unit Off" 547 "System Absorption Exit" 548 "System Inverter Enable" 549 "System AC Good" 550 "Anti Islanding Condition" 551 "Hibernate Timeout" 552 "External Sync Error" 553 "External Suspend Request" 554 "Engaging Charger" 555 "Engaging Gen Support" 556 "Grid Tie Engage Timeout" 557 "Gen Support Engage Timeout" 558 "Charge Engage Timeout" 559 "Inverter Engage Timeout" 560 "Charge Exit Timeout" 561 "Grid Support Entry Amps" 562 "Grid Support Exit Amps" 563 "Gen Support Entry Amps" 564 "Gen Support Exit Amps" 565 "Grid Support Entry Vdc" 566 "Grid Support Exit Vdc" 567 "Low Batt Cut Off Entry Vdc" 568 "Low Batt Recharge Vdc" 569 "Low Batt Cut Off Exit Vdc" 570 "Invert To Bypass Timeout" 571 "Force Charge" 572 "System Engage Bulk Charge" 441 "SPS Auto On External Shutdown Flt" 442 "SPS Auto Off Input Over Volt Flt" 443 "SPS Auto On Input Over Volt Flt" 444 "SPS Auto Off Input Over Volt Err" 445 "SPS Auto On Input Over Volt Err" 446 "SPS Auto Off Input Over Volt Wrn" 447 "SPS Auto On Input Over Volt Wrn" 448 "SPS Auto Off Output Over Volt Err" 449 "SPS Auto On Output Over Volt Err" 450 "SPS Auto Off Output Over Volt Wrn" 451 "SPS Auto On Output Over Volt Wrn" 452 "SPS Auto Off Output Under Volt Err" 453 "SPS Auto On Output Under Volt Err" 454 "SPS Auto Off Output Under Volt Wrn" 455 "SPS Auto On Output Under Volt Wrn" 456 "SPS Auto Off Output Over Curr Err" 457 "SPS Auto On Output Over Curr Err" 458 "SPS Auto Off Batt Over Temp Err" 459 "SPS Auto On Batt Over Temp Err" 460 "SPS Auto Off Batt Over Temp Wrn" 461 "SPS Auto On Batt Over Temp Wrn" 462 "SPS Auto Off Batt Under Temp Wrn" 463 "SPS Auto On Batt Under Temp Wrn" 464 "SPS Auto Off Heatsink Over Temp Err" 465 "SPS Auto On Heatsink Over Temp Err" 466 "SPS Auto Off Heatsink Over Temp Wrn" 467 "SPS Auto On Heatsink Over Temp Wrn" 468 "SPS Auto Off Ambient Over Temp Err" 469 "SPS Auto On Ambient Over Temp Err" 470 "SPS Auto Off Ambient Over Temp Wrn" 471 "SPS Auto On Ambient Over Temp Wrn" 472 "SPS Auto Off Capacitor Over Temp Err" 473 "SPS Auto On Capacitor Over Temp Err" 474 "SPS Auto Off Fan Flt" 475 "SPS Auto On Fan Flt" 476 "SPS Auto Off Fan Err" 477 "SPS Auto On Fan Err" 478 "SPS Auto Off Input Over Curr Err" 479 "SPS Auto On Input Over Curr Err" 480 "SPS Auto Off Output Over Curr Flt" 481 "SPS Auto On Output Over Curr Flt" 482 "SPS Auto Off Network PS Flt" 483 "SPS Auto On Network PS Flt" 484 "SPS Auto Off Setup Flt" 485 "SPS Auto On Setup Flt" 38 "Clear Command User Stats" 573 "AC Good Pending" 574 "Grid Safe" 585 "PLS Time In Float Ready" 575 "Power Conversion Fault" 576 "Low Battery Support Exit" 577 "Grid Support Exit" 578 "GFS Enable" 579 "GFS Disable" 580 "Force Sell" 486 "SPS Auto On Bulk Exit" 487 "SPS Auto Off Bulk Exit" 488 "SPS Auto On Absorption Exit" 489 "SPS Auto Off Absorption Exit" 490 "SPS Auto On State Of Charge Low" 491 "SPS Auto Off State Of Charge Low" 492 "SPS Auto On Time Of Day" 493 "SPS Auto Off Time Of Day" 581 "Sell Time Of Day Start" 582 "Sell Time Of Day Stop" 583 "Aux Port Time Of Day Start" 584 "Aux Port Time Of Day Stop" ;
VAL_ 2147553024 EvtId 436 "SPS Auto Off Array V Low" 437 "SPS Auto On Array V Low" 438 "SPS Auto Off Ground Flt" 439 "SPS Auto On Ground Flt" 440 "SPS Auto Off External Shutdown Flt" 0 "None" 10 "Control Command Hibernate" 11 "Control Command Safe" 12 "Control Command Power Save" 13 "Control Command Operating" 14 "Control Command Diagnostic" 15 "Control Command Last Mode" 20 "Reset Command Reboot" 21 "Reset Command Download" 22 "Reset Command Oem" 23 "Reset Command Factory" 24 "Reset Command Reboot Clear Nv" 25 "Powered Up" 30 "Clear Command Active Faults" 31 "Clear Command Fault Log" 32 "Clear Command Active Warns" 33 "Clear Command Warn Log" 34 "Clear Command State Event Log" 35 "Clear Command Comm Stats" 36 "Clear Command Stats" 37 "Clear Command All" 40 "Date Time Configured" 50 "Warn Cleared" 51 "Fault Cleared" 52 "Fault Set" 60 "User Cfg Changed" 61 "Oem Cfg Changed" 70 "Triggered Fault" 250 "Shutdown Threshold" 251 "Shutdown Hysteresis" 252 "Warning Threshold" 253 "Warning Hysteresis" 254 "Transfer Threshold" 255 "Fan 0 Threshold" 256 "Fan 10 Threshold" 257 "Fan 20 Threshold" 258 "Fan 30 Threshold" 259 "Fan 40 Threshold" 260 "Fan 50 Threshold" 261 "Fan 60 Threshold" 262 "Fan 70 Threshold" 263 "Fan 80 Threshold" 264 "Fan 90 Threshold" 265 "Fan 100 Threshold" 266 "Relay Open Threshold" 267 "Relay Close Threshold" 268 "Charger Derating Ac In V" 269 "Charger Derating Ac In I" 270 "Charger Derating Ext Temp" 271 "Charger Derating Int Temp" 272 "Charger Derating Ripple V" 273 "Lost Ac Threshold" 274 "Lost Ac Hysteresis" 275 "Imm Shutdown Threshold" 276 "Imm Shutdown Hysteresis" 277 "Charger Shutdown Threshold" 278 "Charger Shutdown Hysteresis" 279 "Charger Warning Threshold" 280 "Charger Warning Hysteresis" 281 "Inverter Shutdown Threshold" 282 "Inverter Shutdown Hysteresis" 283 "Inverter Warning Threshold" 284 "Inverter Warning Hysteresis" 285 "Charger Derating Temp Start Point" 286 "Charger Derating Temp End Point" 287 "Charger Recharge Threshold" 300 "Ags Exercise Start" 301 "Ags Exercise Stop" 302 "Ags Quiet Time Begin" 303 "Ags Quiet Time End" 304 "Ags Battery Soc Start" 305 "Ags Battery Soc Stop" 306 "Ags Dc V Start" 307 "Ags Dc V Stop" 308 "Ags Ac I Start" 309 "Ags Ac I Stop" 310 "Ags Contact Start" 311 "Ags Contact Stop" 312 "Ags Float Stop" 313 "Ags Absorp Stop" 314 "Ags Manual On" 315 "Ags Manual Off" 316 "Ags Auto" 317 "Ags External On" 318 "Ags External Off" 319 "Gen External On" 320 "Gen External Off" 321 "Ags External Shutdown" 322 "Ags Auto Off" 323 "Ags Dc I Start" 324 "Ags Dc I Stop" 325 "Ags Ac Power Start" 326 "Ags Ac Power Stop" 400 "Sps Manual Off" 401 "Sps Manual On" 410 "Sps Auto Off" 411 "Sps Auto On" 420 "Sps Auto Off Batt V Low" 421 "Sps Auto On Batt V Low" 422 "Sps Auto Off Batt V High" 423 "Sps Auto On Batt V High" 424 "Sps Auto Off Array V High" 425 "Sps Auto On Array V High" 426 "Sps Auto Off Batt Temp Low" 427 "Sps Auto On Batt Temp Low" 428 "Sps Auto Off Batt Temp High" 429 "Sps Auto On Batt Temp High" 430 "Sps Auto Off Heat Sink Temp High" 431 "Sps Auto On Heat Sink Temp High" 432 "Sps Auto Off Fault" 433 "Sps Auto On Fault" 434 "Aps Check Timeout" 435 "Aps Qualify Timeout" 512 "Resume From Safe" 513 "AC Fault Set" 514 "Invert Fault Set" 515 "Charge Fault Set" 516 "Charger Enable" 517 "Charger Disable" 518 "Inverter Enable" 519 "Inverter Disable" 520 "Charge Suspend On" 521 "Charge Suspend Off" 522 "AC Good" 523 "AC Bad" 524 "Load Sense Enable" 525 "Load Sense Active" 526 "Invert Active" 527 "Bulk Exit" 528 "Absorption Exit" 529 "Float Exit" 530 "Float 3-Stage Set" 531 "Float 2-Stage Set" 532 "Equalize Enable" 533 "Equalize Disable" 534 "Equalize Exit" 535 "Load Sense Disable" 536 "Sell To Grid Enabled" 537 "Sell To Grid Disabled" 538 "Grid Support Enable" 539 "Grid Support Disable" 540 "Gen Support Enable" 541 "Gen Support Disable" 542 "Peak Load Shaving Enable" 543 "Peak Load Shaving Disable" 544 "Peak Load Shaving Tod Start" 545 "Peak Load Shaving Tod Stop" 546 "Unit Off" 547 "System Absorption Exit" 548 "System Inverter Enable" 549 "System AC Good" 550 "Anti Islanding Condition" 551 "Hibernate Timeout" 552 "External Sync Error" 553 "External Suspend Request" 554 "Engaging Charger" 555 "Engaging Gen Support" 556 "Grid Tie Engage Timeout" 557 "Gen Support Engage Timeout" 558 "Charge Engage Timeout" 559 "Inverter Engage Timeout" 560 "Charge Exit Timeout" 561 "Grid Support Entry Amps" 562 "Grid Support Exit Amps" 563 "Gen Support Entry Amps" 564 "Gen Support Exit Amps" 565 "Grid Support Entry Vdc" 566 "Grid Support Exit Vdc" 567 "Low Batt Cut Off Entry Vdc" 568 "Low Batt Recharge Vdc" 569 "Low Batt Cut Off Exit Vdc" 570 "Invert To Bypass Timeout" 571 "Force Charge" 572 "System Engage Bulk Charge" 441 "SPS Auto On External Shutdown Flt" 442 "SPS Auto Off Input Over Volt Flt" 443 "SPS Auto On Input Over Volt Flt" 444 "SPS Auto Off Input Over Volt Err" 445 "SPS Auto On Input Over Volt Err" 446 "SPS Auto Off Input Over Volt Wrn" 447 "SPS Auto On Input Over Volt Wrn" 448 "SPS Auto Off Output Over Volt Err" 449 "SPS Auto On Output Over Volt Err" 450 "SPS Auto Off Output Over Volt Wrn" 451 "SPS Auto On Output Over Volt Wrn" 452 "SPS Auto Off Output Under Volt Err" 453 "SPS Auto On Output Under Volt Err" 454 "SPS Auto Off Output Under Volt Wrn" 455 "SPS Auto On Output Under Volt Wrn" 456 "SPS Auto Off Output Over Curr Err" 457 "SPS Auto On Output Over Curr Err" 458 "SPS Auto Off Batt Over Temp Err" 459 "SPS Auto On Batt Over Temp Err" 460 "SPS Auto Off Batt Over Temp Wrn" 461 "SPS Auto On Batt Over Temp Wrn" 462 "SPS Auto Off Batt Under Temp Wrn" 463 "SPS Auto On Batt Under Temp Wrn" 464 "SPS Auto Off Heatsink Over Temp Err" 465 "SPS Auto On Heatsink Over Temp Err" 466 "SPS Auto Off Heatsink Over Temp Wrn" 467 "SPS Auto On Heatsink Over Temp Wrn" 468 "SPS Auto Off Ambient Over Temp Err" 469 "SPS Auto On Ambient Over Temp Err" 470 "SPS Auto Off Ambient Over Temp Wrn" 471 "SPS Auto On Ambient Over Temp Wrn" 472 "SPS Auto Off Capacitor Over Temp Err" 473 "SPS Auto On Capacitor Over Temp Err" 474 "SPS Auto Off Fan Flt" 475 "SPS Auto On Fan Flt" 476 "SPS Auto Off Fan Err" 477 "SPS Auto On Fan Err" 478 "SPS Auto Off Input Over Curr Err" 479 "SPS Auto On Input Over Curr Err" 480 "SPS Auto Off Output Over Curr Flt" 481 "SPS Auto On Output Over Curr Flt" 482 "SPS Auto Off Network PS Flt" 483 "SPS Auto On Network PS Flt" 484 "SPS Auto Off Setup Flt" 485 "SPS Auto On Setup Flt" 38 "Clear Command User Stats" 573 "AC Good Pending" 574 "Grid Safe" 585 "PLS Time In Float Ready" 575 "Power Conversion Fault" 576 "Low Battery Support Exit" 577 "Grid Support Exit" 578 "GFS Enable" 579 "GFS Disable" 580 "Force Sell" 486 "SPS Auto On Bulk Exit" 487 "SPS Auto Off Bulk Exit" 488 "SPS Auto On Absorption Exit" 489 "SPS Auto Off Absorption Exit" 490 "SPS Auto On State Of Charge Low" 491 "SPS Auto Off State Of Charge Low" 492 "SPS Auto On Time Of Day" 493 "SPS Auto Off Time Of Day" 581 "Sell Time Of Day Start" 582 "Sell Time Of Day Stop" 583 "Aux Port Time Of Day Start" 584 "Aux Port Time Of Day Stop" ;
VAL_ 2147553024 CfgType 0 "User" 1 "OEM" 2 "Factory" 3 "Reserved" ;
VAL_ 2147553280 RefEvtId 436 "SPS Auto Off Array V Low" 437 "SPS Auto On Array V Low" 438 "SPS Auto Off Ground Flt" 439 "SPS Auto On Ground Flt" 440 "SPS Auto Off External Shutdown Flt" 0 "None" 10 "Control Command Hibernate" 11 "Control Command Safe" 12 "Control Command Power Save" 13 "Control Command Operating" 14 "Control Command Diagnostic" 15 "Control Command Last Mode" 20 "Reset Command Reboot" 21 "Reset Command Download" 22 "Reset Command Oem" 23 "Reset Command Factory" 24 "Reset Command Reboot Clear Nv" 25 "Powered Up" 30 "Clear Command Active Faults" 31 "Clear Command Fault Log" 32 "Clear Command Active Warns" 33 "Clear Command Warn Log" 34 "Clear Command State Event Log" 35 "Clear Command Comm Stats" 36 "Clear Command Stats" 37 "Clear Command All" 40 "Date Time Configured" 50 "Warn Cleared" 51 "Fault Cleared" 52 "Fault Set" 60 "User Cfg Changed" 61 "Oem Cfg Changed" 70 "Triggered Fault" 250 "Shutdown Threshold" 251 "Shutdown Hysteresis" 252 "Warning Threshold" 253 "Warning Hysteresis" 254 "Transfer Threshold" 255 "Fan 0 Threshold" 256 "Fan 10 Threshold" 257 "Fan 20 Threshold" 258 "Fan 30 Threshold" 259 "Fan 40 Threshold" 260 "Fan 50 Threshold" 261 "Fan 60 Threshold" 262 "Fan 70 Threshold" 263 "Fan 80 Threshold" 264 "Fan 90 Threshold" 265 "Fan 100 Threshold" 266 "Relay Open Threshold" 267 "Relay Close Threshold" 268 "Charger Derating Ac In V" 269 "Charger Derating Ac In I" 270 "Charger Derating Ext Temp" 271 "Charger Derating Int Temp" 272 "Charger Derating Ripple V" 273 "Lost Ac Threshold" 274 "Lost Ac Hysteresis" 275 "Imm Shutdown Threshold" 276 "Imm Shutdown Hysteresis" 277 "Charger Shutdown Threshold" 278 "Charger Shutdown Hysteresis" 279 "Charger Warning Threshold" 280 "Charger Warning Hysteresis" 281 "Inverter Shutdown Threshold" 282 "Inverter Shutdown Hysteresis" 283 "Inverter Warning Threshold" 284 "Inverter Warning Hysteresis" 285 "Charger Derating Temp Start Point" 286 "Charger Derating Temp End Point" 287 "Charger Recharge Threshold" 300 "Ags Exercise Start" 301 "Ags Exercise Stop" 302 "Ags Quiet Time Begin" 303 "Ags Quiet Time End" 304 "Ags Battery Soc Start" 305 "Ags Battery Soc Stop" 306 "Ags Dc V Start" 307 "Ags Dc V Stop" 308 "Ags Ac I Start" 309 "Ags Ac I Stop" 310 "Ags Contact Start" 311 "Ags Contact Stop" 312 "Ags Float Stop" 313 "Ags Absorp Stop" 314 "Ags Manual On" 315 "Ags Manual Off" 316 "Ags Auto" 317 "Ags External On" 318 "Ags External Off" 319 "Gen External On" 320 "Gen External Off" 321 "Ags External Shutdown" 322 "Ags Auto Off" 323 "Ags Dc I Start" 324 "Ags Dc I Stop" 325 "Ags Ac Power Start" 326 "Ags Ac Power Stop" 400 "Sps Manual Off" 401 "Sps Manual On" 410 "Sps Auto Off" 411 "Sps Auto On" 420 "Sps Auto Off Batt V Low" 421 "Sps Auto On Batt V Low" 422 "Sps Auto Off Batt V High" 423 "Sps Auto On Batt V High" 424 "Sps Auto Off Array V High" 425 "Sps Auto On Array V High" 426 "Sps Auto Off Batt Temp Low" 427 "Sps Auto On Batt Temp Low" 428 "Sps Auto Off Batt Temp High" 429 "Sps Auto On Batt Temp High" 430 "Sps Auto Off Heat Sink Temp High" 431 "Sps Auto On Heat Sink Temp High" 432 "Sps Auto Off Fault" 433 "Sps Auto On Fault" 434 "Aps Check Timeout" 435 "Aps Qualify Timeout" 512 "Resume From Safe" 513 "AC Fault Set" 514 "Invert Fault Set" 515 "Charge Fault Set" 516 "Charger Enable" 517 "Charger Disable" 518 "Inverter Enable" 519 "Inverter Disable" 520 "Charge Suspend On" 521 "Charge Suspend Off" 522 "AC Good" 523 "AC Bad" 524 "Load Sense Enable" 525 "Load Sense Active" 526 "Invert Active" 527 "Bulk Exit" 528 "Absorption Exit" 529 "Float Exit" 530 "Float 3-Stage Set" 531 "Float 2-Stage Set" 532 "Equalize Enable" 533 "Equalize Disable" 534 "Equalize Exit" 535 "Load Sense Disable" 536 "Sell To Grid Enabled" 537 "Sell To Grid Disabled" 538 "Grid Support Enable" 539 "Grid Support Disable" 540 "Gen Support Enable" 541 "Gen Support Disable" 542 "Peak Load Shaving Enable" 543 "Peak Load Shaving Disable" 544 "Peak Load Shaving Tod Start" 545 "Peak Load Shaving Tod Stop" 546 "Unit Off" 547 "System Absorption Exit" 548 "System Inverter Enable" 549 "System AC Good" 550 "Anti Islanding Condition" 551 "Hibernate Timeout" 552 "External Sync Error" 553 "External Suspend Request" 554 "Engaging Charger" 555 "Engaging Gen Support" 556 "Grid Tie Engage Timeout" 557 "Gen Support Engage Timeout" 558 "Charge Engage Timeout" 559 "Inverter Engage Timeout" 560 "Charge Exit Timeout" 561 "Grid Support Entry Amps" 562 "Grid Support Exit Amps" 563 "Gen Support Entry Amps" 564 "Gen Support Exit Amps" 565 "Grid Support Entry Vdc" 566 "Grid Support Exit Vdc" 567 "Low Batt Cut Off Entry Vdc" 568 "Low Batt Recharge Vdc" 569 "Low Batt Cut Off Exit Vdc" 570 "Invert To Bypass Timeout" 571 "Force Charge" 572 "System Engage Bulk Charge" 441 "SPS Auto On External Shutdown Flt" 442 "SPS Auto Off Input Over Volt Flt" 443 "SPS Auto On Input Over Volt Flt" 444 "SPS Auto Off Input Over Volt Err" 445 "SPS Auto On Input Over Volt Err" 446 "SPS Auto Off Input Over Volt Wrn" 447 "SPS Auto On Input Over Volt Wrn" 448 "SPS Auto Off Output Over Volt Err" 449 "SPS Auto On Output Over Volt Err" 450 "SPS Auto Off Output Over Volt Wrn" 451 "SPS Auto On Output Over Volt Wrn" 452 "SPS Auto Off Output Under Volt Err" 453 "SPS Auto On Output Under Volt Err" 454 "SPS Auto Off Output Under Volt Wrn" 455 "SPS Auto On Output Under Volt Wrn" 456 "SPS Auto Off Output Over Curr Err" 457 "SPS Auto On Output Over Curr Err" 458 "SPS Auto Off Batt Over Temp Err" 459 "SPS Auto On Batt Over Temp Err" 460 "SPS Auto Off Batt Over Temp Wrn" 461 "SPS Auto On Batt Over Temp Wrn" 462 "SPS Auto Off Batt Under Temp Wrn" 463 "SPS Auto On Batt Under Temp Wrn" 464 "SPS Auto Off Heatsink Over Temp Err" 465 "SPS Auto On Heatsink Over Temp Err" 466 "SPS Auto Off Heatsink Over Temp Wrn" 467 "SPS Auto On Heatsink Over Temp Wrn" 468 "SPS Auto Off Ambient Over Temp Err" 469 "SPS Auto On Ambient Over Temp Err" 470 "SPS Auto Off Ambient Over Temp Wrn" 471 "SPS Auto On Ambient Over Temp Wrn" 472 "SPS Auto Off Capacitor Over Temp Err" 473 "SPS Auto On Capacitor Over Temp Err" 474 "SPS Auto Off Fan Flt" 475 "SPS Auto On Fan Flt" 476 "SPS Auto Off Fan Err" 477 "SPS Auto On Fan Err" 478 "SPS Auto Off Input Over Curr Err" 479 "SPS Auto On Input Over Curr Err" 480 "SPS Auto Off Output Over Curr Flt" 481 "SPS Auto On Output Over Curr Flt" 482 "SPS Auto Off Network PS Flt" 483 "SPS Auto On Network PS Flt" 484 "SPS Auto Off Setup Flt" 485 "SPS Auto On Setup Flt" 38 "Clear Command User Stats" 573 "AC Good Pending" 574 "Grid Safe" 585 "PLS Time In Float Ready" 575 "Power Conversion Fault" 576 "Low Battery Support Exit" 577 "Grid Support Exit" 578 "GFS Enable" 579 "GFS Disable" 580 "Force Sell" 486 "SPS Auto On Bulk Exit" 487 "SPS Auto Off Bulk Exit" 488 "SPS Auto On Absorption Exit" 489 "SPS Auto Off Absorption Exit" 490 "SPS Auto On State Of Charge Low" 491 "SPS Auto Off State Of Charge Low" 492 "SPS Auto On Time Of Day" 493 "SPS Auto Off Time Of Day" 581 "Sell Time Of Day Start" 582 "Sell Time Of Day Stop" 583 "Aux Port Time Of Day Start" 584 "Aux Port Time Of Day Stop" ;
VAL_ 2147553280 EvtId 436 "SPS Auto Off Array V Low" 437 "SPS Auto On Array V Low" 438 "SPS Auto Off Ground Flt" 439 "SPS Auto On Ground Flt" 440 "SPS Auto Off External Shutdown Flt" 0 "None" 10 "Control Command Hibernate" 11 "Control Command Safe" 12 "Control Command Power Save" 13 "Control Command Operating" 14 "Control Command Diagnostic" 15 "Control Command Last Mode" 20 "Reset Command Reboot" 21 "Reset Command Download" 22 "Reset Command Oem" 23 "Reset Command Factory" 24 "Reset Command Reboot Clear Nv" 25 "Powered Up" 30 "Clear Command Active Faults" 31 "Clear Command Fault Log" 32 "Clear Command Active Warns" 33 "Clear Command Warn Log" 34 "Clear Command State Event Log" 35 "Clear Command Comm Stats" 36 "Clear Command Stats" 37 "Clear Command All" 40 "Date Time Configured" 50 "Warn Cleared" 51 "Fault Cleared" 52 "Fault Set" 60 "User Cfg Changed" 61 "Oem Cfg Changed" 70 "Triggered Fault" 250 "Shutdown Threshold" 251 "Shutdown Hysteresis" 252 "Warning Threshold" 253 "Warning Hysteresis" 254 "Transfer Threshold" 255 "Fan 0 Threshold" 256 "Fan 10 Threshold" 257 "Fan 20 Threshold" 258 "Fan 30 Threshold" 259 "Fan 40 Threshold" 260 "Fan 50 Threshold" 261 "Fan 60 Threshold" 262 "Fan 70 Threshold" 263 "Fan 80 Threshold" 264 "Fan 90 Threshold" 265 "Fan 100 Threshold" 266 "Relay Open Threshold" 267 "Relay Close Threshold" 268 "Charger Derating Ac In V" 269 "Charger Derating Ac In I" 270 "Charger Derating Ext Temp" 271 "Charger Derating Int Temp" 272 "Charger Derating Ripple V" 273 "Lost Ac Threshold" 274 "Lost Ac Hysteresis" 275 "Imm Shutdown Threshold" 276 "Imm Shutdown Hysteresis" 277 "Charger Shutdown Threshold" 278 "Charger Shutdown Hysteresis" 279 "Charger Warning Threshold" 280 "Charger Warning Hysteresis" 281 "Inverter Shutdown Threshold" 282 "Inverter Shutdown Hysteresis" 283 "Inverter Warning Threshold" 284 "Inverter Warning Hysteresis" 285 "Charger Derating Temp Start Point" 286 "Charger Derating Temp End Point" 287 "Charger Recharge Threshold" 300 "Ags Exercise Start" 301 "Ags Exercise Stop" 302 "Ags Quiet Time Begin" 303 "Ags Quiet Time End" 304 "Ags Battery Soc Start" 305 "Ags Battery Soc Stop" 306 "Ags Dc V Start" 307 "Ags Dc V Stop" 308 "Ags Ac I Start" 309 "Ags Ac I Stop" 310 "Ags Contact Start" 311 "Ags Contact Stop" 312 "Ags Float Stop" 313 "Ags Absorp Stop" 314 "Ags Manual On" 315 "Ags Manual Off" 316 "Ags Auto" 317 "Ags External On" 318 "Ags External Off" 319 "Gen External On" 320 "Gen External Off" 321 "Ags External Shutdown" 322 "Ags Auto Off" 323 "Ags Dc I Start" 324 "Ags Dc I Stop" 325 "Ags Ac Power Start" 326 "Ags Ac Power Stop" 400 "Sps Manual Off" 401 "Sps Manual On" 410 "Sps Auto Off" 411 "Sps Auto On" 420 "Sps Auto Off Batt V Low" 421 "Sps Auto On Batt V Low" 422 "Sps Auto Off Batt V High" 423 "Sps Auto On Batt V High" 424 "Sps Auto Off Array V High" 425 "Sps Auto On Array V High" 426 "Sps Auto Off Batt Temp Low" 427 "Sps Auto On Batt Temp Low" 428 "Sps Auto Off Batt Temp High" 429 "Sps Auto On Batt Temp High" 430 "Sps Auto Off Heat Sink Temp High" 431 "Sps Auto On Heat Sink Temp High" 432 "Sps Auto Off Fault" 433 "Sps Auto On Fault" 434 "Aps Check Timeout" 435 "Aps Qualify Timeout" 512 "Resume From Safe" 513 "AC Fault Set" 514 "Invert Fault Set" 515 "Charge Fault Set" 516 "Charger Enable" 517 "Charger Disable" 518 "Inverter Enable" 519 "Inverter Disable" 520 "Charge Suspend On" 521 "Charge Suspend Off" 522 "AC Good" 523 "AC Bad" 524 "Load Sense Enable" 525 "Load Sense Active" 526 "Invert Active" 527 "Bulk Exit" 528 "Absorption Exit" 529 "Float Exit" 530 "Float 3-Stage Set" 531 "Float 2-Stage Set" 532 "Equalize Enable" 533 "Equalize Disable" 534 "Equalize Exit" 535 "Load Sense Disable" 536 "Sell To Grid Enabled" 537 "Sell To Grid Disabled" 538 "Grid Support Enable" 539 "Grid Support Disable" 540 "Gen Support Enable" 541 "Gen Support Disable" 542 "Peak Load Shaving Enable" 543 "Peak Load Shaving Disable" 544 "Peak Load Shaving Tod Start" 545 "Peak Load Shaving Tod Stop" 546 "Unit Off" 547 "System Absorption Exit" 548 "System Inverter Enable" 549 "System AC Good" 550 "Anti Islanding Condition" 551 "Hibernate Timeout" 552 "External Sync Error" 553 "External Suspend Request" 554 "Engaging Charger" 555 "Engaging Gen Support" 556 "Grid Tie Engage Timeout" 557 "Gen Support Engage Timeout" 558 "Charge Engage Timeout" 559 "Inverter Engage Timeout" 560 "Charge Exit Timeout" 561 "Grid Support Entry Amps" 562 "Grid Support Exit Amps" 563 "Gen Support Entry Amps" 564 "Gen Support Exit Amps" 565 "Grid Support Entry Vdc" 566 "Grid Support Exit Vdc" 567 "Low Batt Cut Off Entry Vdc" 568 "Low Batt Recharge Vdc" 569 "Low Batt Cut Off Exit Vdc" 570 "Invert To Bypass Timeout" 571 "Force Charge" 572 "System Engage Bulk Charge" 441 "SPS Auto On External Shutdown Flt" 442 "SPS Auto Off Input Over Volt Flt" 443 "SPS Auto On Input Over Volt Flt" 444 "SPS Auto Off Input Over Volt Err" 445 "SPS Auto On Input Over Volt Err" 446 "SPS Auto Off Input Over Volt Wrn" 447 "SPS Auto On Input Over Volt Wrn" 448 "SPS Auto Off Output Over Volt Err" 449 "SPS Auto On Output Over Volt Err" 450 "SPS Auto Off Output Over Volt Wrn" 451 "SPS Auto On Output Over Volt Wrn" 452 "SPS Auto Off Output Under Volt Err" 453 "SPS Auto On Output Under Volt Err" 454 "SPS Auto Off Output Under Volt Wrn" 455 "SPS Auto On Output Under Volt Wrn" 456 "SPS Auto Off Output Over Curr Err" 457 "SPS Auto On Output Over Curr Err" 458 "SPS Auto Off Batt Over Temp Err" 459 "SPS Auto On Batt Over Temp Err" 460 "SPS Auto Off Batt Over Temp Wrn" 461 "SPS Auto On Batt Over Temp Wrn" 462 "SPS Auto Off Batt Under Temp Wrn" 463 "SPS Auto On Batt Under Temp Wrn" 464 "SPS Auto Off Heatsink Over Temp Err" 465 "SPS Auto On Heatsink Over Temp Err" 466 "SPS Auto Off Heatsink Over Temp Wrn" 467 "SPS Auto On Heatsink Over Temp Wrn" 468 "SPS Auto Off Ambient Over Temp Err" 469 "SPS Auto On Ambient Over Temp Err" 470 "SPS Auto Off Ambient Over Temp Wrn" 471 "SPS Auto On Ambient Over Temp Wrn" 472 "SPS Auto Off Capacitor Over Temp Err" 473 "SPS Auto On Capacitor Over Temp Err" 474 "SPS Auto Off Fan Flt" 475 "SPS Auto On Fan Flt" 476 "SPS Auto Off Fan Err" 477 "SPS Auto On Fan Err" 478 "SPS Auto Off Input Over Curr Err" 479 "SPS Auto On Input Over Curr Err" 480 "SPS Auto Off Output Over Curr Flt" 481 "SPS Auto On Output Over Curr Flt" 482 "SPS Auto Off Network PS Flt" 483 "SPS Auto On Network PS Flt" 484 "SPS Auto Off Setup Flt" 485 "SPS Auto On Setup Flt" 38 "Clear Command User Stats" 573 "AC Good Pending" 574 "Grid Safe" 585 "PLS Time In Float Ready" 575 "Power Conversion Fault" 576 "Low Battery Support Exit" 577 "Grid Support Exit" 578 "GFS Enable" 579 "GFS Disable" 580 "Force Sell" 486 "SPS Auto On Bulk Exit" 487 "SPS Auto Off Bulk Exit" 488 "SPS Auto On Absorption Exit" 489 "SPS Auto Off Absorption Exit" 490 "SPS Auto On State Of Charge Low" 491 "SPS Auto Off State Of Charge Low" 492 "SPS Auto On Time Of Day" 493 "SPS Auto Off Time Of Day" 581 "Sell Time Of Day Start" 582 "Sell Time Of Day Stop" 583 "Aux Port Time Of Day Start" 584 "Aux Port Time Of Day Stop" ;
VAL_ 2147553280 CfgType 0 "User" 1 "OEM" 2 "Factory" 3 "Reserved" ;
VAL_ 2147564032 IndustryGroup 0 "All" 1 "On Highway" 2 "Agriculture" 3 "Construction" 4 "Marine" 5 "Industrial" 6 "Reserved 1" 7 "Reserved 2" ;
VAL_ 2147564032 DeviceFunction 128 "User Interface" 129 "Inverter Charger" 130 "Inverter" 131 "Charger" 132 "Battery Monitor" 133 "AGS" 134 "Diagnostic Terminal" 135 "Gateway" 136 "Energy Management System" 137 "Battery Management System" ;
VAL_ 2147564032 DeviceClass 30 "Power Management" ;
VAL_ 2147564032 CfgType 0 "User" 1 "OEM" 2 "Factory" 3 "Reserved" ;
VAL_ 2147610825 MpptMode 0 "Not Available" 1 "MPPT" 2 "Constant Current" 3 "Constant Voltage" 4 "Constant Power" ;
VAL_ 2147548888 IndustryGroup 0 "All" 1 "On Highway" 2 "Agriculture" 3 "Construction" 4 "Marine" 5 "Industrial" 6 "Reserved 1" 7 "Reserved 2" ;
VAL_ 2147548888 DeviceFunction 128 "User Interface" 129 "Inverter Charger" 130 "Inverter" 131 "Charger" 132 "Battery Monitor" 133 "AGS" 134 "Diagnostic Terminal" 135 "Gateway" 136 "Energy Management System" 137 "Battery Management System" ;
VAL_ 2147548888 DeviceClass 30 "Power Management" ;
VAL_ 2147544576 IndustryGroup 0 "All" 1 "On Highway" 2 "Agriculture" 3 "Construction" 4 "Marine" 5 "Industrial" 6 "Reserved 1" 7 "Reserved 2" ;
VAL_ 2147544576 DeviceFunction 128 "User Interface" 129 "Inverter Charger" 130 "Inverter" 131 "Charger" 132 "Battery Monitor" 133 "AGS" 134 "Diagnostic Terminal" 135 "Gateway" 136 "Energy Management System" 137 "Battery Management System" ;
VAL_ 2147544576 DeviceClass 30 "Power Management" ;
VAL_ 2147543040 GroupFunctionValue -1 "Do Not Care" 241 "Unsupported" 242 "Not Available" 243 "Data Access Error" 244 "Data Not Available" 245 "Data Invalid" 246 "DLC Invalid" 247 "Message Count" 248 "CAC" 249 "Configuration Type" 250 "Protocol" 251 "Security" 252 "Wrong Mode" 253 "Memory Error" ;
VAL_ 2147543040 CtrlByte 0 "Ack" 1 "Nak" 2 "Dny" ;
VAL_ 2147610653 Line 0 "Invalid" 1 "Line 1" 2 "Line 2" 3 "Line 3" 253 "Reserved" 254 "Out Of Range" 255 "Data Not Available Do Not Change" ;
VAL_ 2147610653 AcSrcId 0 "Invalid" 1 "None" 2 "Anonymous" 3 "Shore1" 4 "Shore2" 5 "Shore3" 6 "Shore4" 7 "Shore5" 8 "Shore6" 9 "Shore7" 10 "Shore8" 11 "Shore9" 12 "Shore10" 13 "Shore11" 14 "Shore12" 15 "Shore13" 16 "Shore14" 17 "Shore15" 18 "Shore16" 19 "Gen1" 20 "Gen2" 21 "Gen3" 22 "Gen4" 23 "Gen5" 24 "Gen6" 25 "Gen7" 26 "Gen8" 27 "Gen9" 28 "Gen10" 29 "Gen11" 30 "Gen12" 31 "Gen13" 32 "Gen14" 33 "Gen15" 34 "Gen16" 35 "AC1" 36 "AC2" 37 "AC3" 38 "AC4" 39 "AC5" 40 "AC6" 41 "AC7" 42 "AC8" 43 "AC9" 44 "AC10" 45 "AC11" 46 "AC12" 47 "AC13" 48 "AC14" 49 "AC15" 50 "AC16" 51 "AC Load1" 52 "AC Load2" 53 "AC Load3" 54 "AC Load4" 55 "AC Load5" 56 "AC Load6" 57 "AC Load7" 58 "AC Load8" 59 "AC Load9" 60 "AC Load10" 61 "AC Load11" 62 "AC Load12" 63 "AC Load13" 64 "AC Load14" 65 "AC Load15" 66 "AC Load16" 67 "Grid1" 68 "Grid2" 69 "Grid3" 70 "Grid4" 71 "Grid5" 72 "Grid6" 73 "Grid7" 74 "Grid8" 75 "Grid9" 76 "Grid10" 77 "Grid11" 78 "Grid12" 79 "Grid13" 80 "Grid14" 81 "Grid15" 82 "Grid16" 252 "All" 253 "Reserved" 254 "Out Of Range" 255 "Data Not Available Do Not Change" ;
VAL_ 2147610813 SellToGridEnDis 0 "Off" 1 "On" 2 "Error" 3 "Unknown" ;
VAL_ 2147610813 PeakLoadShavingEnDis 0 "Off" 1 "On" 2 "Error" 3 "Unknown" ;
VAL_ 2147610813 OpState 1024 "Invert" 1025 "AC Passthru" 1026 "APSOnly" 1027 "Load Sense Active" 1028 "Inverter Disabled" 1029 "Load Sense Ready" 1030 "Engaging Inverter" 1031 "Invert Fault" 1032 "Inverter Standby" 1033 "Grid Tied" 1034 "Grid Support" 1035 "Gen Support" 1036 "Sell To Grid" 1037 "Load Shaving" 1038 "Grid Frequency Stabilization" 1040 "Reverse Ibatt" 1039 "AC Coupling" ;
VAL_ 2147610813 InvMode 0 "Invalid" 1 "SinglePhaseStandAlone" 11 "SinglePhaseMaster" 12 "SinglePhaseSlave" 20 "SplitPhaseStandAlone" 21 "SplitPhaseMaster" 22 "SplitPhaseSlave" 23 "TwoPhase Phase1Master" 24 "TwoPhase Phase1Slave" 25 "TwoPhase Phase2Master" 26 "TwoPhase Phase2Slave" 30 "ThreePhaseStandAlone" 31 "ThreePhaseMaster" 32 "ThreePhaseSlave" 33 "ThreePhase Phase1Master" 34 "ThreePhase Phase1Slave" 35 "ThreePhase Phase2Master" 36 "ThreePhase Phase2Slave" 37 "ThreePhase Phase3Master" 38 "ThreePhase Phase3Slave" 253 "Reserved" 254 "Out Of Range" 255 "Data Not Available Do Not Change" ;
VAL_ 2147610813 InvEnDis 0 "Off" 1 "On" 2 "Error" 3 "Unknown" ;
VAL_ 2147610813 GridEnDis 0 "Off" 1 "On" 2 "Error" 3 "Unknown" ;
VAL_ 2147610813 ForceSell 0 "Off" 1 "On" 2 "Reserved" 3 "No Change" ;
VAL_ 2147610813 BattTempSensorPresent 0 "Off" 1 "On" 2 "Error" 3 "Unknown" ;
VAL_ 2147610813 AntiIslandingEnDis 0 "Off" 1 "On" 2 "Error" 3 "Unknown" ;
VAL_ 2147610813 AcSrcId 0 "Invalid" 1 "None" 2 "Anonymous" 3 "Shore1" 4 "Shore2" 5 "Shore3" 6 "Shore4" 7 "Shore5" 8 "Shore6" 9 "Shore7" 10 "Shore8" 11 "Shore9" 12 "Shore10" 13 "Shore11" 14 "Shore12" 15 "Shore13" 16 "Shore14" 17 "Shore15" 18 "Shore16" 19 "Gen1" 20 "Gen2" 21 "Gen3" 22 "Gen4" 23 "Gen5" 24 "Gen6" 25 "Gen7" 26 "Gen8" 27 "Gen9" 28 "Gen10" 29 "Gen11" 30 "Gen12" 31 "Gen13" 32 "Gen14" 33 "Gen15" 34 "Gen16" 35 "AC1" 36 "AC2" 37 "AC3" 38 "AC4" 39 "AC5" 40 "AC6" 41 "AC7" 42 "AC8" 43 "AC9" 44 "AC10" 45 "AC11" 46 "AC12" 47 "AC13" 48 "AC14" 49 "AC15" 50 "AC16" 51 "AC Load1" 52 "AC Load2" 53 "AC Load3" 54 "AC Load4" 55 "AC Load5" 56 "AC Load6" 57 "AC Load7" 58 "AC Load8" 59 "AC Load9" 60 "AC Load10" 61 "AC Load11" 62 "AC Load12" 63 "AC Load13" 64 "AC Load14" 65 "AC Load15" 66 "AC Load16" 67 "Grid1" 68 "Grid2" 69 "Grid3" 70 "Grid4" 71 "Grid5" 72 "Grid6" 73 "Grid7" 74 "Grid8" 75 "Grid9" 76 "Grid10" 77 "Grid11" 78 "Grid12" 79 "Grid13" 80 "Grid14" 81 "Grid15" 82 "Grid16" 252 "All" 253 "Reserved" 254 "Out Of Range" 255 "Data Not Available Do Not Change" ;
VAL_ 2147610649 SellToGridEnDis 0 "Off" 1 "On" 2 "Error" 3 "Unknown" ;
VAL_ 2147610649 OpState 1024 "Invert" 1025 "AC Passthru" 1026 "APSOnly" 1027 "Load Sense Active" 1028 "Inverter Disabled" 1029 "Load Sense Ready" 1030 "Engaging Inverter" 1031 "Invert Fault" 1032 "Inverter Standby" 1033 "Grid Tied" 1034 "Grid Support" 1035 "Gen Support" 1036 "Sell To Grid" 1037 "Load Shaving" 1038 "Grid Frequency Stabilization" 1040 "Reverse Ibatt" 1039 "AC Coupling" ;
VAL_ 2147610649 InvEnDis 0 "Off" 1 "On" 2 "Error" 3 "Unknown" ;
VAL_ 2147610649 BattTempSensorPresent 0 "Off" 1 "On" 2 "Error" 3 "Unknown" ;
VAL_ 2147610649 AcSrcId 0 "Invalid" 1 "None" 2 "Anonymous" 3 "Shore1" 4 "Shore2" 5 "Shore3" 6 "Shore4" 7 "Shore5" 8 "Shore6" 9 "Shore7" 10 "Shore8" 11 "Shore9" 12 "Shore10" 13 "Shore11" 14 "Shore12" 15 "Shore13" 16 "Shore14" 17 "Shore15" 18 "Shore16" 19 "Gen1" 20 "Gen2" 21 "Gen3" 22 "Gen4" 23 "Gen5" 24 "Gen6" 25 "Gen7" 26 "Gen8" 27 "Gen9" 28 "Gen10" 29 "Gen11" 30 "Gen12" 31 "Gen13" 32 "Gen14" 33 "Gen15" 34 "Gen16" 35 "AC1" 36 "AC2" 37 "AC3" 38 "AC4" 39 "AC5" 40 "AC6" 41 "AC7" 42 "AC8" 43 "AC9" 44 "AC10" 45 "AC11" 46 "AC12" 47 "AC13" 48 "AC14" 49 "AC15" 50 "AC16" 51 "AC Load1" 52 "AC Load2" 53 "AC Load3" 54 "AC Load4" 55 "AC Load5" 56 "AC Load6" 57 "AC Load7" 58 "AC Load8" 59 "AC Load9" 60 "AC Load10" 61 "AC Load11" 62 "AC Load12" 63 "AC Load13" 64 "AC Load14" 65 "AC Load15" 66 "AC Load16" 67 "Grid1" 68 "Grid2" 69 "Grid3" 70 "Grid4" 71 "Grid5" 72 "Grid6" 73 "Grid7" 74 "Grid8" 75 "Grid9" 76 "Grid10" 77 "Grid11" 78 "Grid12" 79 "Grid13" 80 "Grid14" 81 "Grid15" 82 "Grid16" 252 "All" 253 "Reserved" 254 "Out Of Range" 255 "Data Not Available Do Not Change" ;
VAL_ 2147610655 TempSensId 0 "Transistor 1" 1 "Transistor 2" 2 "Transistor 3" 3 "Transistor 4" 10 "Capacitor 1" 11 "Capacitor 2" 12 "Capacitor 3" 13 "Capacitor 4" 20 "Transformer 1" 21 "Transformer 2" 22 "Transformer 3" 23 "Transformer 4" 30 "Ambient 1" 31 "Ambient 2" 32 "Ambient 3" 33 "Ambient 4" 34 "Shunt 1" 35 "Shunt 2" 36 "Shunt 3" 37 "Shunt 4" 38 "Heatsink 1" 39 "Heatsink 2" 40 "Heatsink 3" 41 "Heatsink 4" 253 "Reserved" 254 "Out of Range" 255 "Data Not Available Do Not Change" ;
VAL_ 2147610656 TempSensId 0 "Battery 1" 1 "Battery 2" 2 "Battery 3" 3 "Battery 4" 4 "Battery 5" 5 "Battery 6" 10 "Ambient 1" 11 "Ambient 2" 12 "Ambient 3" 13 "Ambient 4" 14 "Shunt 1" 15 "Shunt 2" 16 "Shunt 3" 17 "Shunt 4" 253 "Reserved" 254 "Out of Range" 255 "Data Not Available Do Not Change" ;
VAL_ 2147610819 PreviousPeriod 0 "Life" 1 "Year" 2 "Month" 3 "Week" 4 "Day" 5 "Hour" 6 "User" ;
VAL_ 2147610819 DcSrcId 0 "Invalid" 1 "None" 2 "Anonymous" 3 "HouseBatBank1" 4 "HouseBatBank2" 5 "HouseBatBank3" 6 "HouseBatBank4" 7 "HouseBatBank5" 8 "HouseBatBank6" 9 "StartBatBank1" 10 "StartBatBank2" 11 "StartBatBank3" 12 "StartBatBank4" 13 "StartBatBank5" 14 "StartBatBank6" 21 "SolarArray1" 22 "SolarArray2" 23 "SolarArray3" 24 "SolarArray4" 25 "SolarArray5" 26 "SolarArray6" 27 "SolarArray7" 28 "SolarArray8" 29 "SolarArray9" 30 "SolarArray10" 31 "SolarArray11" 32 "SolarArray12" 33 "SolarArray13" 34 "SolarArray14" 35 "SolarArray15" 36 "SolarArray16" 252 "All" 253 "Reserved" 254 "Out of Range" 255 "Data Not Available Do Not Change" ;
VAL_ 2147610654 DcSrcId 0 "Invalid" 1 "None" 2 "Anonymous" 3 "HouseBatBank1" 4 "HouseBatBank2" 5 "HouseBatBank3" 6 "HouseBatBank4" 7 "HouseBatBank5" 8 "HouseBatBank6" 9 "StartBatBank1" 10 "StartBatBank2" 11 "StartBatBank3" 12 "StartBatBank4" 13 "StartBatBank5" 14 "StartBatBank6" 21 "SolarArray1" 22 "SolarArray2" 23 "SolarArray3" 24 "SolarArray4" 25 "SolarArray5" 26 "SolarArray6" 27 "SolarArray7" 28 "SolarArray8" 29 "SolarArray9" 30 "SolarArray10" 31 "SolarArray11" 32 "SolarArray12" 33 "SolarArray13" 34 "SolarArray14" 35 "SolarArray15" 36 "SolarArray16" 252 "All" 253 "Reserved" 254 "Out of Range" 255 "Data Not Available Do Not Change" ;
VAL_ 2147610818 PreviousPeriod 0 "Life" 1 "Year" 2 "Month" 3 "Week" 4 "Day" 5 "Hour" 6 "User" ;
VAL_ 2147610818 Line 0 "Invalid" 1 "Line 1" 2 "Line 2" 3 "Line 3" 253 "Reserved" 254 "Out Of Range" 255 "Data Not Available Do Not Change" ;
VAL_ 2147610818 AcSrcId 0 "Invalid" 1 "None" 2 "Anonymous" 3 "Shore1" 4 "Shore2" 5 "Shore3" 6 "Shore4" 7 "Shore5" 8 "Shore6" 9 "Shore7" 10 "Shore8" 11 "Shore9" 12 "Shore10" 13 "Shore11" 14 "Shore12" 15 "Shore13" 16 "Shore14" 17 "Shore15" 18 "Shore16" 19 "Gen1" 20 "Gen2" 21 "Gen3" 22 "Gen4" 23 "Gen5" 24 "Gen6" 25 "Gen7" 26 "Gen8" 27 "Gen9" 28 "Gen10" 29 "Gen11" 30 "Gen12" 31 "Gen13" 32 "Gen14" 33 "Gen15" 34 "Gen16" 35 "AC1" 36 "AC2" 37 "AC3" 38 "AC4" 39 "AC5" 40 "AC6" 41 "AC7" 42 "AC8" 43 "AC9" 44 "AC10" 45 "AC11" 46 "AC12" 47 "AC13" 48 "AC14" 49 "AC15" 50 "AC16" 51 "AC Load1" 52 "AC Load2" 53 "AC Load3" 54 "AC Load4" 55 "AC Load5" 56 "AC Load6" 57 "AC Load7" 58 "AC Load8" 59 "AC Load9" 60 "AC Load10" 61 "AC Load11" 62 "AC Load12" 63 "AC Load13" 64 "AC Load14" 65 "AC Load15" 66 "AC Load16" 67 "Grid1" 68 "Grid2" 69 "Grid3" 70 "Grid4" 71 "Grid5" 72 "Grid6" 73 "Grid7" 74 "Grid8" 75 "Grid9" 76 "Grid10" 77 "Grid11" 78 "Grid12" 79 "Grid13" 80 "Grid14" 81 "Grid15" 82 "Grid16" 252 "All" 253 "Reserved" 254 "Out Of Range" 255 "Data Not Available Do Not Change" ;
VAL_ 2147610640 TotalFlag 0 "Off" 1 "On" 2 "Error" 3 "Unknown" ;
VAL_ 2147610640 Line 0 "Invalid" 1 "Line 1" 2 "Line 2" 3 "Line 3" 253 "Reserved" 254 "Out Of Range" 255 "Data Not Available Do Not Change" ;
VAL_ 2147610640 AcSrcId 0 "Invalid" 1 "None" 2 "Anonymous" 3 "Shore1" 4 "Shore2" 5 "Shore3" 6 "Shore4" 7 "Shore5" 8 "Shore6" 9 "Shore7" 10 "Shore8" 11 "Shore9" 12 "Shore10" 13 "Shore11" 14 "Shore12" 15 "Shore13" 16 "Shore14" 17 "Shore15" 18 "Shore16" 19 "Gen1" 20 "Gen2" 21 "Gen3" 22 "Gen4" 23 "Gen5" 24 "Gen6" 25 "Gen7" 26 "Gen8" 27 "Gen9" 28 "Gen10" 29 "Gen11" 30 "Gen12" 31 "Gen13" 32 "Gen14" 33 "Gen15" 34 "Gen16" 35 "AC1" 36 "AC2" 37 "AC3" 38 "AC4" 39 "AC5" 40 "AC6" 41 "AC7" 42 "AC8" 43 "AC9" 44 "AC10" 45 "AC11" 46 "AC12" 47 "AC13" 48 "AC14" 49 "AC15" 50 "AC16" 51 "AC Load1" 52 "AC Load2" 53 "AC Load3" 54 "AC Load4" 55 "AC Load5" 56 "AC Load6" 57 "AC Load7" 58 "AC Load8" 59 "AC Load9" 60 "AC Load10" 61 "AC Load11" 62 "AC Load12" 63 "AC Load13" 64 "AC Load14" 65 "AC Load15" 66 "AC Load16" 67 "Grid1" 68 "Grid2" 69 "Grid3" 70 "Grid4" 71 "Grid5" 72 "Grid6" 73 "Grid7" 74 "Grid8" 75 "Grid9" 76 "Grid10" 77 "Grid11" 78 "Grid12" 79 "Grid13" 80 "Grid14" 81 "Grid15" 82 "Grid16" 252 "All" 253 "Reserved" 254 "Out Of Range" 255 "Data Not Available Do Not Change" ;
VAL_ 2147563264 SellToGridEnDis 0 "Off" 1 "On" 2 "Reserved" 3 "No Change" ;
VAL_ 2147563264 InvEnDis 0 "Off" 1 "On" 2 "Reserved" 3 "No Change" ;
VAL_ 2147563264 ForceSell 0 "Off" 1 "On" 2 "Reserved" 3 "No Change" ;
VAL_ 2147563264 AcSrcId 0 "Invalid" 1 "None" 2 "Anonymous" 3 "Shore1" 4 "Shore2" 5 "Shore3" 6 "Shore4" 7 "Shore5" 8 "Shore6" 9 "Shore7" 10 "Shore8" 11 "Shore9" 12 "Shore10" 13 "Shore11" 14 "Shore12" 15 "Shore13" 16 "Shore14" 17 "Shore15" 18 "Shore16" 19 "Gen1" 20 "Gen2" 21 "Gen3" 22 "Gen4" 23 "Gen5" 24 "Gen6" 25 "Gen7" 26 "Gen8" 27 "Gen9" 28 "Gen10" 29 "Gen11" 30 "Gen12" 31 "Gen13" 32 "Gen14" 33 "Gen15" 34 "Gen16" 35 "AC1" 36 "AC2" 37 "AC3" 38 "AC4" 39 "AC5" 40 "AC6" 41 "AC7" 42 "AC8" 43 "AC9" 44 "AC10" 45 "AC11" 46 "AC12" 47 "AC13" 48 "AC14" 49 "AC15" 50 "AC16" 51 "AC Load1" 52 "AC Load2" 53 "AC Load3" 54 "AC Load4" 55 "AC Load5" 56 "AC Load6" 57 "AC Load7" 58 "AC Load8" 59 "AC Load9" 60 "AC Load10" 61 "AC Load11" 62 "AC Load12" 63 "AC Load13" 64 "AC Load14" 65 "AC Load15" 66 "AC Load16" 67 "Grid1" 68 "Grid2" 69 "Grid3" 70 "Grid4" 71 "Grid5" 72 "Grid6" 73 "Grid7" 74 "Grid8" 75 "Grid9" 76 "Grid10" 77 "Grid11" 78 "Grid12" 79 "Grid13" 80 "Grid14" 81 "Grid15" 82 "Grid16" 252 "All" 253 "Reserved" 254 "Out Of Range" 255 "Data Not Available Do Not Change" ;
VAL_ 2147557632 CfgType 0 "User" 1 "OEM" 2 "Factory" 3 "Reserved" ;
VAL_ 2147557632 AcSrcId 0 "Invalid" 1 "None" 2 "Anonymous" 3 "Shore1" 4 "Shore2" 5 "Shore3" 6 "Shore4" 7 "Shore5" 8 "Shore6" 9 "Shore7" 10 "Shore8" 11 "Shore9" 12 "Shore10" 13 "Shore11" 14 "Shore12" 15 "Shore13" 16 "Shore14" 17 "Shore15" 18 "Shore16" 19 "Gen1" 20 "Gen2" 21 "Gen3" 22 "Gen4" 23 "Gen5" 24 "Gen6" 25 "Gen7" 26 "Gen8" 27 "Gen9" 28 "Gen10" 29 "Gen11" 30 "Gen12" 31 "Gen13" 32 "Gen14" 33 "Gen15" 34 "Gen16" 35 "AC1" 36 "AC2" 37 "AC3" 38 "AC4" 39 "AC5" 40 "AC6" 41 "AC7" 42 "AC8" 43 "AC9" 44 "AC10" 45 "AC11" 46 "AC12" 47 "AC13" 48 "AC14" 49 "AC15" 50 "AC16" 51 "AC Load1" 52 "AC Load2" 53 "AC Load3" 54 "AC Load4" 55 "AC Load5" 56 "AC Load6" 57 "AC Load7" 58 "AC Load8" 59 "AC Load9" 60 "AC Load10" 61 "AC Load11" 62 "AC Load12" 63 "AC Load13" 64 "AC Load14" 65 "AC Load15" 66 "AC Load16" 67 "Grid1" 68 "Grid2" 69 "Grid3" 70 "Grid4" 71 "Grid5" 72 "Grid6" 73 "Grid7" 74 "Grid8" 75 "Grid9" 76 "Grid10" 77 "Grid11" 78 "Grid12" 79 "Grid13" 80 "Grid14" 81 "Grid15" 82 "Grid16" 252 "All" 253 "Reserved" 254 "Out Of Range" 255 "Data Not Available Do Not Change" ;
VAL_ 2147557888 XferSwMode 0 "Unknown" 1 "Grid Priority" 2 "Generator Priority" 253 "Reserved" 254 "Out Of Range" 255 "Data Not Available Do Not Change" ;
VAL_ 2147557888 LoadSenseEnDis 0 "Off" 1 "On" 2 "Reserved" 3 "No Change" ;
VAL_ 2147557888 InvMode 0 "Invalid" 1 "SinglePhaseStandAlone" 11 "SinglePhaseMaster" 12 "SinglePhaseSlave" 20 "SplitPhaseStandAlone" 21 "SplitPhaseMaster" 22 "SplitPhaseSlave" 23 "TwoPhase Phase1Master" 24 "TwoPhase Phase1Slave" 25 "TwoPhase Phase2Master" 26 "TwoPhase Phase2Slave" 30 "ThreePhaseStandAlone" 31 "ThreePhaseMaster" 32 "ThreePhaseSlave" 33 "ThreePhase Phase1Master" 34 "ThreePhase Phase1Slave" 35 "ThreePhase Phase2Master" 36 "ThreePhase Phase2Slave" 37 "ThreePhase Phase3Master" 38 "ThreePhase Phase3Slave" 253 "Reserved" 254 "Out Of Range" 255 "Data Not Available Do Not Change" ;
VAL_ 2147557888 CfgType 0 "User" 1 "OEM" 2 "Factory" 3 "Reserved" ;
VAL_ 2147557888 AcSrcId 0 "Invalid" 1 "None" 2 "Anonymous" 3 "Shore1" 4 "Shore2" 5 "Shore3" 6 "Shore4" 7 "Shore5" 8 "Shore6" 9 "Shore7" 10 "Shore8" 11 "Shore9" 12 "Shore10" 13 "Shore11" 14 "Shore12" 15 "Shore13" 16 "Shore14" 17 "Shore15" 18 "Shore16" 19 "Gen1" 20 "Gen2" 21 "Gen3" 22 "Gen4" 23 "Gen5" 24 "Gen6" 25 "Gen7" 26 "Gen8" 27 "Gen9" 28 "Gen10" 29 "Gen11" 30 "Gen12" 31 "Gen13" 32 "Gen14" 33 "Gen15" 34 "Gen16" 35 "AC1" 36 "AC2" 37 "AC3" 38 "AC4" 39 "AC5" 40 "AC6" 41 "AC7" 42 "AC8" 43 "AC9" 44 "AC10" 45 "AC11" 46 "AC12" 47 "AC13" 48 "AC14" 49 "AC15" 50 "AC16" 51 "AC Load1" 52 "AC Load2" 53 "AC Load3" 54 "AC Load4" 55 "AC Load5" 56 "AC Load6" 57 "AC Load7" 58 "AC Load8" 59 "AC Load9" 60 "AC Load10" 61 "AC Load11" 62 "AC Load12" 63 "AC Load13" 64 "AC Load14" 65 "AC Load15" 66 "AC Load16" 67 "Grid1" 68 "Grid2" 69 "Grid3" 70 "Grid4" 71 "Grid5" 72 "Grid6" 73 "Grid7" 74 "Grid8" 75 "Grid9" 76 "Grid10" 77 "Grid11" 78 "Grid12" 79 "Grid13" 80 "Grid14" 81 "Grid15" 82 "Grid16" 252 "All" 253 "Reserved" 254 "Out Of Range" 255 "Data Not Available Do Not Change" ;
VAL_ 2147610637 TempSensId 0 "Transistor 1" 1 "Transistor 2" 2 "Transistor 3" 3 "Transistor 4" 10 "Capacitor 1" 11 "Capacitor 2" 12 "Capacitor 3" 13 "Capacitor 4" 20 "Transformer 1" 21 "Transformer 2" 22 "Transformer 3" 23 "Transformer 4" 30 "Ambient 1" 31 "Ambient 2" 32 "Ambient 3" 33 "Ambient 4" 34 "Shunt 1" 35 "Shunt 2" 36 "Shunt 3" 37 "Shunt 4" 38 "Heatsink 1" 39 "Heatsink 2" 40 "Heatsink 3" 41 "Heatsink 4" 253 "Reserved" 254 "Out of Range" 255 "Data Not Available Do Not Change" ;
VAL_ 2147610824 TempSensId 0 "Transistor 1" 1 "Transistor 2" 2 "Transistor 3" 3 "Transistor 4" 10 "Capacitor 1" 11 "Capacitor 2" 12 "Capacitor 3" 13 "Capacitor 4" 20 "Transformer 1" 21 "Transformer 2" 22 "Transformer 3" 23 "Transformer 4" 30 "Ambient 1" 31 "Ambient 2" 32 "Ambient 3" 33 "Ambient 4" 34 "Shunt 1" 35 "Shunt 2" 36 "Shunt 3" 37 "Shunt 4" 38 "Heatsink 1" 39 "Heatsink 2" 40 "Heatsink 3" 41 "Heatsink 4" 253 "Reserved" 254 "Out of Range" 255 "Data Not Available Do Not Change" ;
VAL_ 2147610824 PreviousPeriod 0 "Life" 1 "Year" 2 "Month" 3 "Week" 4 "Day" 5 "Hour" 6 "User" ;
